VERSION "$Format:%h$"

NS_ :

BS_:

BU_: APB APP APS BCCEN BDY DAS DBG EAS EPAS EPAS2 EPAS3S EPB EPBM ESP GTW GTWU IBST IC MCU OCS PARK PARK3 RADAR RCM RT3000 SCCM SDM SEC TAS TAS2 TAS2DBG TOOL TPMS VCSEATD VCSEATP

BO_ 1486 PARK_alertLog: 8 PARK
 SG_ PARK_alertID M : 0|15@1+ (1,0) [0|0] "" GTW
 SG_ PARK_sw060_subCode m60 : 55|9@1+ (1,0) [0|0] "" GTW
 SG_ PARK_sw061_ambTemp m61 : 16|8@1+ (0.5,-40) [-40|87.5] "C" GTW
 SG_ PARK_sw061_voltage m61 : 24|8@1+ (0.1,0) [0|25.4] "V" GTW
 SG_ PARK_sw061_timeHours m61 : 32|5@1+ (1,0) [0|30] "hours" GTW
 SG_ PARK_sw061_timeMinutes m61 : 40|6@1+ (1,0) [0|60] "minutes" GTW
 SG_ PARK_sw061_timeSeconds m61 : 48|7@1+ (0.5,0) [0|60] "seconds" GTW
 SG_ PARK_sw061_subCode m61 : 55|9@1+ (1,0) [0|0] "" GTW
 SG_ PARK_sw062_ambTemp m62 : 16|8@1+ (0.5,-40) [-40|87.5] "C" GTW
 SG_ PARK_sw062_voltage m62 : 24|8@1+ (0.1,0) [0|25.4] "V" GTW
 SG_ PARK_sw062_timeHours m62 : 32|5@1+ (1,0) [0|30] "hours" GTW
 SG_ PARK_sw062_timeMinutes m62 : 40|6@1+ (1,0) [0|60] "minutes" GTW
 SG_ PARK_sw062_timeSeconds m62 : 48|7@1+ (0.5,0) [0|60] "seconds" GTW
 SG_ PARK_sw062_subCode m62 : 55|9@1+ (1,0) [0|0] "" GTW
 SG_ PARK_sw063_ambTemp m63 : 16|8@1+ (0.5,-40) [-40|87.5] "C" GTW
 SG_ PARK_sw063_voltage m63 : 24|8@1+ (0.1,0) [0|25.4] "V" GTW
 SG_ PARK_sw063_timeHours m63 : 32|5@1+ (1,0) [0|30] "hours" GTW
 SG_ PARK_sw063_timeMinutes m63 : 40|6@1+ (1,0) [0|60] "minutes" GTW
 SG_ PARK_sw063_timeSeconds m63 : 48|7@1+ (0.5,0) [0|60] "seconds" GTW
 SG_ PARK_sw063_subCode m63 : 55|9@1+ (1,0) [0|0] "" GTW
 SG_ PARK_sw064_byte2 m64 : 16|8@1+ (1,0) [0|255] "" GTW
 SG_ PARK_sw064_byte3 m64 : 24|8@1+ (1,0) [0|255] "" GTW
 SG_ PARK_sw064_byte4 m64 : 32|8@1+ (1,0) [0|255] "" GTW
 SG_ PARK_sw064_byte5 m64 : 40|8@1+ (1,0) [0|255] "" GTW
 SG_ PARK_sw064_byte6 m64 : 48|8@1+ (1,0) [0|255] "" GTW
 SG_ PARK_sw064_byte7 m64 : 56|8@1+ (1,0) [0|255] "" GTW

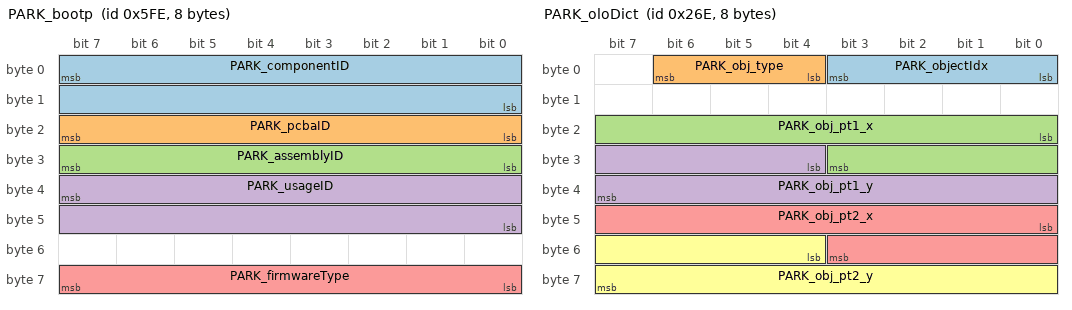
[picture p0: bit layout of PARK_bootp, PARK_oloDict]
BO_ 1534 PARK_bootp: 8 PARK
 SG_ PARK_componentID : 7|16@0+ (1,0) [0|0] "" Vector__XXX
 SG_ PARK_pcbaID : 23|8@0+ (1,0) [0|0] "" Vector__XXX
 SG_ PARK_assemblyID : 31|8@0+ (1,0) [0|0] "" Vector__XXX
 SG_ PARK_usageID : 39|16@0+ (1,0) [0|0] "" Vector__XXX
 SG_ PARK_firmwareType : 63|8@0+ (1,0) [0|0] "" Vector__XXX

BO_ 622 PARK_oloDict: 8 PARK
 SG_ PARK_objectIdx : 0|4@1+ (1,0) [0|15] "" GTW,DAS
 SG_ PARK_obj_type : 4|3@1+ (1,0) [0|7] "" GTW,DAS
 SG_ PARK_obj_pt1_x : 16|12@1+ (1,-2048) [-2048|2046] "" GTW,DAS
 SG_ PARK_obj_pt1_y : 28|12@1+ (1,-2048) [-2048|2046] "" GTW,DAS
 SG_ PARK_obj_pt2_x : 40|12@1+ (1,-2048) [-2048|2046] "" GTW,DAS
 SG_ PARK_obj_pt2_y : 52|12@1+ (1,-2048) [-2048|2046] "" GTW,DAS

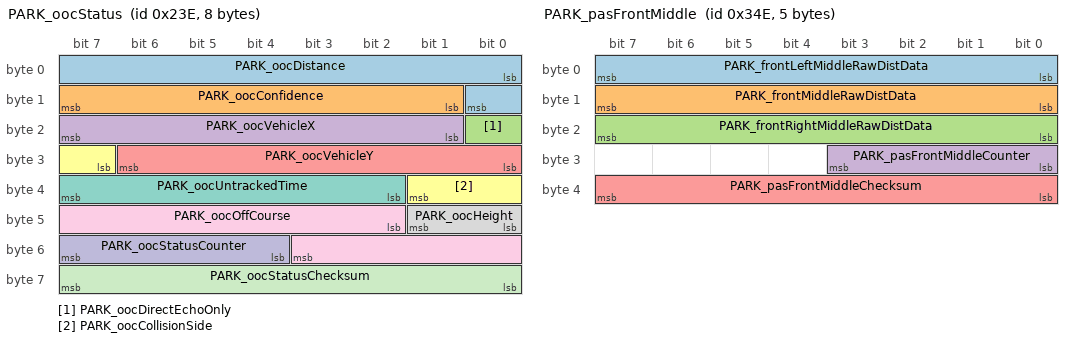
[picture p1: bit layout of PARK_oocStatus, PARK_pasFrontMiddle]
BO_ 574 PARK_oocStatus: 8 PARK
 SG_ PARK_oocDistance : 0|9@1+ (1,0) [0|512] "" EPB,EPBM,GTW,DAS
 SG_ PARK_oocConfidence : 9|7@1+ (1,0) [0|100] "" EPB,EPBM,GTW,DAS
 SG_ PARK_oocDirectEchoOnly : 16|1@1+ (1,0) [0|1] "" Vector__XXX
 SG_ PARK_oocVehicleX : 17|7@1+ (4,-114) [-114|394] "cm" Vector__XXX
 SG_ PARK_oocVehicleY : 24|7@1+ (2,-128) [-128|126] "cm" Vector__XXX
 SG_ PARK_oocCollisionSide : 31|3@1+ (1,0) [0|7] "" DAS,GTW
 SG_ PARK_oocUntrackedTime : 34|6@1+ (0.1,0) [0|6.3] "s" GTW,DAS
 SG_ PARK_oocHeight : 40|2@1+ (1,0) [0|4] "" DAS,GTW
 SG_ PARK_oocOffCourse : 42|10@1+ (1,-512) [-512|511] "" GTW,DAS
 SG_ PARK_oocStatusCounter : 52|4@1+ (1,0) [0|15] "" Vector__XXX
 SG_ PARK_oocStatusChecksum : 56|8@1+ (1,0) [0|255] "" Vector__XXX

BO_ 846 PARK_pasFrontMiddle: 5 PARK
 SG_ PARK_frontLeftMiddleRawDistData : 0|8@1+ (1,0) [0|255] "" GTW,DAS
 SG_ PARK_frontMiddleRawDistData : 8|8@1+ (1,0) [0|255] "" GTW,DAS
 SG_ PARK_frontRightMiddleRawDistData : 16|8@1+ (1,0) [0|255] "" GTW,DAS
 SG_ PARK_pasFrontMiddleCounter : 24|4@1+ (1,0) [0|0] "" GTW
 SG_ PARK_pasFrontMiddleChecksum : 32|8@1+ (1,0) [0|0] "" GTW

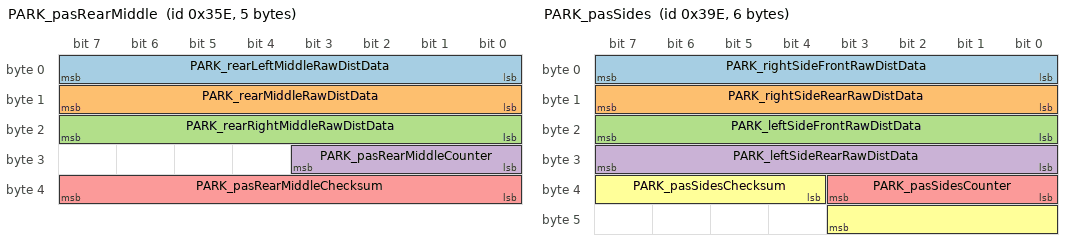
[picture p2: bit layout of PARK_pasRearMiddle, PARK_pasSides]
BO_ 862 PARK_pasRearMiddle: 5 PARK
 SG_ PARK_rearLeftMiddleRawDistData : 0|8@1+ (1,0) [0|255] "" GTW,DAS
 SG_ PARK_rearMiddleRawDistData : 8|8@1+ (1,0) [0|255] "" GTW,DAS
 SG_ PARK_rearRightMiddleRawDistData : 16|8@1+ (1,0) [0|255] "" GTW,DAS
 SG_ PARK_pasRearMiddleCounter : 24|4@1+ (1,0) [0|0] "" GTW,DAS
 SG_ PARK_pasRearMiddleChecksum : 32|8@1+ (1,0) [0|0] "" GTW

BO_ 926 PARK_pasSides: 6 PARK
 SG_ PARK_rightSideFrontRawDistData : 0|8@1+ (1,0) [0|255] "cm" GTW
 SG_ PARK_rightSideRearRawDistData : 8|8@1+ (1,0) [0|255] "cm" GTW
 SG_ PARK_leftSideFrontRawDistData : 16|8@1+ (1,0) [0|255] "cm" GTW
 SG_ PARK_leftSideRearRawDistData : 24|8@1+ (1,0) [0|255] "cm" GTW
 SG_ PARK_pasSidesCounter : 32|4@1+ (1,0) [0|0] "" GTW
 SG_ PARK_pasSidesChecksum : 36|8@1+ (1,0) [0|0] "" GTW

BO_ 606 PARK_pscEnvSlot: 8 PARK
 SG_ PARK_pscEnvSlotType M : 0|3@1+ (1,0) [0|7] "" GTW
 SG_ PARK_pscLeftParallelObj1X m0 : 3|11@1+ (2,-2048) [-2048|2046] "cm" GTW
 SG_ PARK_pscLeftParallelObj1Y m0 : 14|11@1+ (2,-2048) [-2048|2046] "cm" GTW
 SG_ PARK_pscLeftParallelObj1Alpha m0 : 25|7@1+ (2,-128) [-128|127] "deg" GTW
 SG_ PARK_pscLeftParallelObj2Y m0 : 35|11@1+ (2,-2048) [-2048|2046] "cm" GTW
 SG_ PARK_pscLeftParallelObj2X m0 : 46|11@1+ (2,-2048) [-2048|2046] "cm" GTW
 SG_ PARK_pscLeftParallelObj2Alpha m0 : 57|7@1+ (2,-128) [-128|127] "deg" GTW
 SG_ PARK_pscLeftCrossObj1X m1 : 3|11@1+ (2,-2048) [-2048|2046] "cm" GTW
 SG_ PARK_pscLeftCrossObj1Y m1 : 14|11@1+ (2,-2048) [-2048|2046] "cm" GTW
 SG_ PARK_pscLeftCrossObj1Alpha m1 : 25|7@1+ (2,-128) [-128|127] "deg" GTW
 SG_ PARK_pscLeftCrossObj2Y m1 : 35|11@1+ (2,-2048) [-2048|2046] "cm" GTW
 SG_ PARK_pscLeftCrossObj2X m1 : 46|11@1+ (2,-2048) [-2048|2046] "cm" GTW
 SG_ PARK_pscLeftCrossObj2Alpha m1 : 57|7@1+ (2,-128) [-128|127] "deg" GTW
 SG_ PARK_pscRightParallelObj1X m2 : 3|11@1+ (2,-2048) [-2048|2046] "cm" GTW
 SG_ PARK_pscRightParallelObj1Y m2 : 14|11@1+ (2,-2048) [-2048|2046] "cm" GTW
 SG_ PARK_pscRightParallelObj1Alpha m2 : 25|7@1+ (2,-128) [-128|127] "deg" GTW
 SG_ PARK_pscRightParallelObj2Y m2 : 35|11@1+ (2,-2048) [-2048|2046] "cm" GTW
 SG_ PARK_pscRightParallelObj2X m2 : 46|11@1+ (2,-2048) [-2048|2046] "cm" GTW
 SG_ PARK_pscRightParallelObj2Alpha m2 : 57|7@1+ (2,-128) [-128|127] "deg" GTW
 SG_ PARK_pscRightCrossObj1X m3 : 3|11@1+ (2,-2048) [-2048|2046] "cm" GTW
 SG_ PARK_pscRightCrossObj1Y m3 : 14|11@1+ (2,-2048) [-2048|2046] "cm" GTW
 SG_ PARK_pscRightCrossObj1Alpha m3 : 25|7@1+ (2,-128) [-128|127] "deg" GTW
 SG_ PARK_pscRightCrossObj2Y m3 : 35|11@1+ (2,-2048) [-2048|2046] "cm" GTW
 SG_ PARK_pscRightCrossObj2X m3 : 46|11@1+ (2,-2048) [-2048|2046] "cm" GTW
 SG_ PARK_pscRightCrossObj2Alpha m3 : 57|7@1+ (2,-128) [-128|127] "deg" GTW

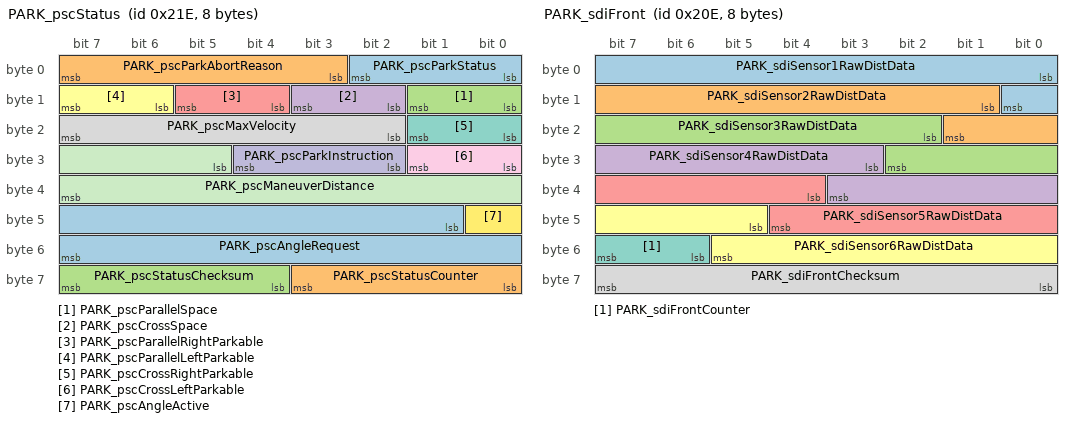
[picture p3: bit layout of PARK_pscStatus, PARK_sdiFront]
BO_ 542 PARK_pscStatus: 8 PARK
 SG_ PARK_pscParkStatus : 0|3@1+ (1,0) [0|7] "" GTW,DAS
 SG_ PARK_pscParkAbortReason : 3|5@1+ (1,0) [0|31] "" GTW,DAS
 SG_ PARK_pscParallelSpace : 8|2@1+ (1,0) [0|3] "" GTW,DAS
 SG_ PARK_pscCrossSpace : 10|2@1+ (1,0) [0|3] "" GTW,DAS
 SG_ PARK_pscParallelRightParkable : 12|2@1+ (1,0) [0|3] "" GTW,DAS
 SG_ PARK_pscParallelLeftParkable : 14|2@1+ (1,0) [0|3] "" GTW,DAS
 SG_ PARK_pscCrossRightParkable : 16|2@1+ (1,0) [0|3] "" GTW,DAS
 SG_ PARK_pscMaxVelocity : 18|6@1+ (0.1,0) [0|6.4] "kph" GTW,DAS
 SG_ PARK_pscCrossLeftParkable : 24|2@1+ (1,0) [0|3] "" GTW,DAS
 SG_ PARK_pscParkInstruction : 26|3@1+ (1,0) [0|7] "" GTW,DAS
 SG_ PARK_pscManeuverDistance : 29|11@1+ (1,0) [0|2047] "cm" GTW,DAS
 SG_ PARK_pscAngleActive : 40|1@1+ (1,0) [0|1] "" GTW,DAS
 SG_ PARK_pscAngleRequest : 41|15@1+ (0.1,-1638.4) [-1638.4|1638.4] "deg" GTW,DAS
 SG_ PARK_pscStatusCounter : 56|4@1+ (1,0) [0|15] "" GTW
 SG_ PARK_pscStatusChecksum : 60|4@1+ (1,0) [0|15] "" GTW

BO_ 590 PARK_pscVehSlot: 8 PARK
 SG_ PARK_pscVehSlotType M : 0|3@1+ (1,0) [0|7] "" GTW,DAS
 SG_ PARK_pscLeftParallelVehX m0 : 5|11@1+ (2,-2048) [-2048|2046] "cm" GTW
 SG_ PARK_pscLeftParallelVehY m0 : 16|11@1+ (2,-2048) [-2048|2046] "cm" GTW
 SG_ PARK_pscLeftParallelPsi m0 : 32|13@1+ (0.0009765625,0) [0|7.9990234375] "radians" GTW,DAS
 SG_ PARK_pscLeftParallelSizeX m0 : 48|8@1+ (4,0) [0|1020] "cm" GTW,DAS
 SG_ PARK_pscLeftParallelSizeY m0 : 56|8@1+ (4,0) [0|1020] "cm" GTW,DAS
 SG_ PARK_pscLeftCrossVehX m1 : 5|11@1+ (2,-2048) [-2048|2046] "cm" GTW
 SG_ PARK_pscLeftCrossVehY m1 : 16|11@1+ (2,-2048) [-2048|2046] "cm" GTW
 SG_ PARK_pscLeftCrossPsi m1 : 32|13@1+ (0.0009765625,0) [0|7.9990234375] "radians" GTW,DAS
 SG_ PARK_pscLeftCrossSizeX m1 : 48|8@1+ (4,0) [0|1020] "cm" GTW,DAS
 SG_ PARK_pscLeftCrossSizeY m1 : 56|8@1+ (4,0) [0|1020] "cm" GTW,DAS
 SG_ PARK_pscRightParallelVehX m2 : 5|11@1+ (2,-2048) [-2048|2046] "cm" GTW
 SG_ PARK_pscRightParallelVehY m2 : 16|11@1+ (2,-2048) [-2048|2046] "cm" GTW
 SG_ PARK_pscRightParallelPsi m2 : 32|13@1+ (0.0009765625,0) [0|7.9990234375] "radians" GTW,DAS
 SG_ PARK_pscRightParallelSizeX m2 : 48|8@1+ (4,0) [0|1020] "cm" GTW,DAS
 SG_ PARK_pscRightParallelSizeY m2 : 56|8@1+ (4,0) [0|1020] "cm" GTW,DAS
 SG_ PARK_pscRightCrossVehX m3 : 5|11@1+ (2,-2048) [-2048|2046] "cm" GTW
 SG_ PARK_pscRightCrossVehY m3 : 16|11@1+ (2,-2048) [-2048|2046] "cm" GTW
 SG_ PARK_pscRightCrossPsi m3 : 32|13@1+ (0.0009765625,0) [0|7.9990234375] "radians" GTW,DAS
 SG_ PARK_pscRightCrossSizeX m3 : 48|8@1+ (4,0) [0|1020] "cm" GTW,DAS
 SG_ PARK_pscRightCrossSizeY m3 : 56|8@1+ (4,0) [0|1020] "cm" GTW,DAS

BO_ 526 PARK_sdiFront: 8 PARK
 SG_ PARK_sdiSensor1RawDistData : 0|9@1+ (1,0) [0|511] "cm" DAS,GTW
 SG_ PARK_sdiSensor2RawDistData : 9|9@1+ (1,0) [0|511] "cm" APS,APP,GTW
 SG_ PARK_sdiSensor3RawDistData : 18|9@1+ (1,0) [0|511] "cm" DAS,APS,APP,GTW
 SG_ PARK_sdiSensor4RawDistData : 27|9@1+ (1,0) [0|511] "cm" DAS,APS,APP,GTW
 SG_ PARK_sdiSensor5RawDistData : 36|9@1+ (1,0) [0|511] "cm" APS,APP,GTW
 SG_ PARK_sdiSensor6RawDistData : 45|9@1+ (1,0) [0|511] "cm" DAS,GTW
 SG_ PARK_sdiFrontCounter : 54|2@1+ (1,0) [0|3] "" DAS,GTW
 SG_ PARK_sdiFrontChecksum : 56|8@1+ (1,0) [0|255] "" GTW

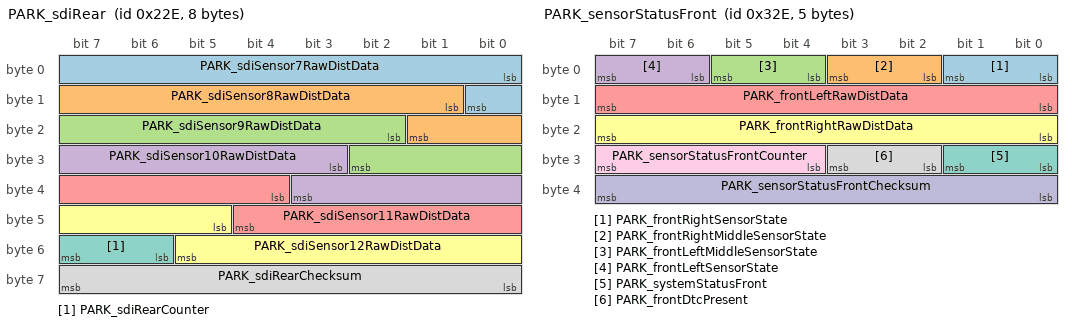
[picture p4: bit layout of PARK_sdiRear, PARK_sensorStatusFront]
BO_ 558 PARK_sdiRear: 8 PARK
 SG_ PARK_sdiSensor7RawDistData : 0|9@1+ (1,0) [0|511] "cm" DAS,GTW
 SG_ PARK_sdiSensor8RawDistData : 9|9@1+ (1,0) [0|511] "cm" DAS,GTW
 SG_ PARK_sdiSensor9RawDistData : 18|9@1+ (1,0) [0|511] "cm" DAS,GTW
 SG_ PARK_sdiSensor10RawDistData : 27|9@1+ (1,0) [0|511] "cm" DAS,GTW
 SG_ PARK_sdiSensor11RawDistData : 36|9@1+ (1,0) [0|511] "cm" DAS,GTW
 SG_ PARK_sdiSensor12RawDistData : 45|9@1+ (1,0) [0|511] "cm" DAS,GTW
 SG_ PARK_sdiRearCounter : 54|2@1+ (1,0) [0|3] "" DAS,GTW
 SG_ PARK_sdiRearChecksum : 56|8@1+ (1,0) [0|255] "" GTW

BO_ 814 PARK_sensorStatusFront: 5 PARK
 SG_ PARK_frontRightSensorState : 0|2@1+ (1,0) [0|0] "" GTW,DAS
 SG_ PARK_frontRightMiddleSensorState : 2|2@1+ (1,0) [0|0] "" GTW,DAS
 SG_ PARK_frontLeftMiddleSensorState : 4|2@1+ (1,0) [0|0] "" GTW,DAS
 SG_ PARK_frontLeftSensorState : 6|2@1+ (1,0) [0|0] "" GTW,DAS
 SG_ PARK_frontLeftRawDistData : 8|8@1+ (1,0) [0|255] "" GTW,DAS
 SG_ PARK_frontRightRawDistData : 16|8@1+ (1,0) [0|255] "" GTW,DAS
 SG_ PARK_systemStatusFront : 24|2@1+ (1,0) [0|0] "" GTW,DAS
 SG_ PARK_frontDtcPresent : 26|2@1+ (1,0) [0|0] "" GTW,DAS
 SG_ PARK_sensorStatusFrontCounter : 28|4@1+ (1,0) [0|0] "" GTW
 SG_ PARK_sensorStatusFrontChecksum : 32|8@1+ (1,0) [0|0] "" GTW

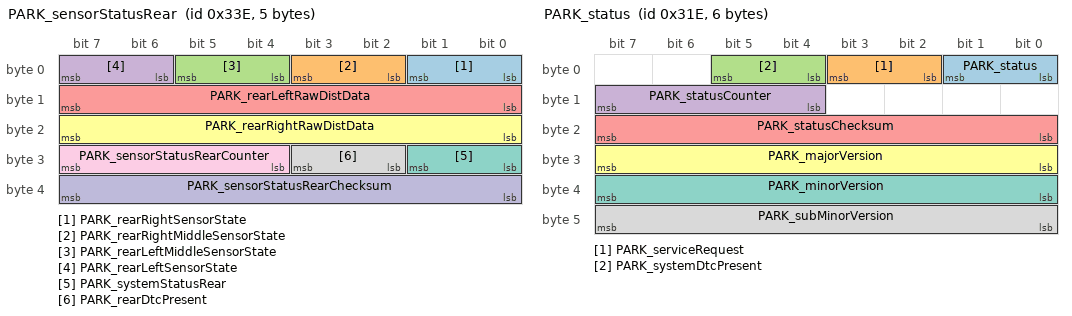
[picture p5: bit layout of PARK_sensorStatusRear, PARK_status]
BO_ 830 PARK_sensorStatusRear: 5 PARK
 SG_ PARK_rearRightSensorState : 0|2@1+ (1,0) [0|0] "" GTW,DAS
 SG_ PARK_rearRightMiddleSensorState : 2|2@1+ (1,0) [0|0] "" GTW,DAS
 SG_ PARK_rearLeftMiddleSensorState : 4|2@1+ (1,0) [0|0] "" GTW,DAS
 SG_ PARK_rearLeftSensorState : 6|2@1+ (1,0) [0|0] "" GTW,DAS
 SG_ PARK_rearLeftRawDistData : 8|8@1+ (1,0) [0|255] "" GTW,DAS
 SG_ PARK_rearRightRawDistData : 16|8@1+ (1,0) [0|255] "" GTW,DAS
 SG_ PARK_systemStatusRear : 24|2@1+ (1,0) [0|0] "" GTW,DAS
 SG_ PARK_rearDtcPresent : 26|2@1+ (1,0) [0|0] "" GTW,DAS
 SG_ PARK_sensorStatusRearCounter : 28|4@1+ (1,0) [0|0] "" GTW,DAS
 SG_ PARK_sensorStatusRearChecksum : 32|8@1+ (1,0) [0|0] "" GTW

BO_ 798 PARK_status: 6 PARK
 SG_ PARK_status : 0|2@1+ (1,0) [0|0] "" GTW,DAS
 SG_ PARK_serviceRequest : 2|2@1+ (1,0) [0|0] "" GTW,DAS
 SG_ PARK_systemDtcPresent : 4|2@1+ (1,0) [0|0] "" GTW,DAS
 SG_ PARK_statusCounter : 12|4@1+ (1,0) [0|0] "" GTW
 SG_ PARK_statusChecksum : 16|8@1+ (1,0) [0|0] "" GTW
 SG_ PARK_majorVersion : 24|8@1+ (1,0) [0|0] "" GTW,DAS
 SG_ PARK_minorVersion : 32|8@1+ (1,0) [0|0] "" GTW,DAS
 SG_ PARK_subMinorVersion : 40|8@1+ (1,0) [0|0] "" GTW,DAS

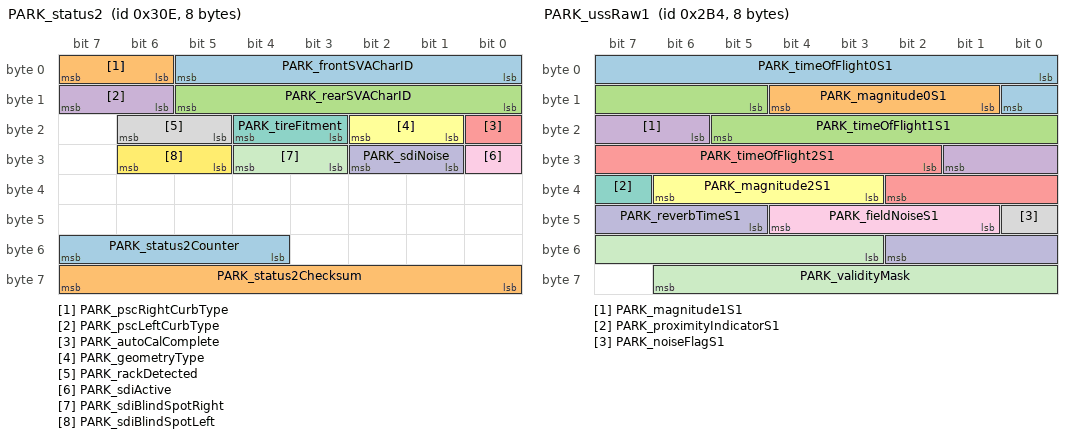
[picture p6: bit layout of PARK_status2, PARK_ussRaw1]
BO_ 782 PARK_status2: 8 PARK
 SG_ PARK_frontSVACharID : 0|6@1+ (1,0) [0|63] "" DAS,GTW
 SG_ PARK_pscRightCurbType : 6|2@1+ (1,0) [0|3] "" DAS,GTW
 SG_ PARK_rearSVACharID : 8|6@1+ (1,0) [0|63] "" DAS,GTW
 SG_ PARK_pscLeftCurbType : 14|2@1+ (1,0) [0|3] "" DAS,GTW
 SG_ PARK_autoCalComplete : 16|1@1+ (1,0) [0|1] "" DAS,GTW
 SG_ PARK_geometryType : 17|2@1+ (1,0) [0|3] "" GTW
 SG_ PARK_tireFitment : 19|2@1+ (1,0) [0|3] "" DAS,GTW
 SG_ PARK_rackDetected : 21|2@1+ (1,0) [0|3] "" DAS,GTW
 SG_ PARK_sdiActive : 24|1@1+ (1,0) [0|1] "" DAS,GTW
 SG_ PARK_sdiNoise : 25|2@1+ (1,0) [0|3] "" DAS,GTW
 SG_ PARK_sdiBlindSpotRight : 27|2@1+ (1,0) [0|3] "" DAS,GTW
 SG_ PARK_sdiBlindSpotLeft : 29|2@1+ (1,0) [0|3] "" DAS,GTW
 SG_ PARK_status2Counter : 52|4@1+ (1,0) [0|0] "" GTW,DAS
 SG_ PARK_status2Checksum : 56|8@1+ (1,0) [0|0] "" GTW

BO_ 1630 PARK_udsResponse: 8 PARK
 SG_ PARK_udsResponseData : 7|64@0+ (1,0) [0|0] "" GTW,GTWU

BO_ 692 PARK_ussRaw1: 8 PARK
 SG_ PARK_timeOfFlight0S1 : 0|9@1+ (0.0512,0) [0|26.1632] "ms" APP
 SG_ PARK_magnitude0S1 : 9|4@1+ (2,0) [0|30] "" APP
 SG_ PARK_timeOfFlight1S1 : 13|9@1+ (0.0512,0) [0|26.1632] "ms" APP
 SG_ PARK_magnitude1S1 : 22|4@1+ (2,0) [0|30] "" APP
 SG_ PARK_timeOfFlight2S1 : 26|9@1+ (0.0512,0) [0|26.1632] "ms" APP
 SG_ PARK_magnitude2S1 : 35|4@1+ (2,0) [0|30] "" APP
 SG_ PARK_proximityIndicatorS1 : 39|1@1+ (1,0) [0|0] "" APP
 SG_ PARK_noiseFlagS1 : 40|1@1+ (1,0) [0|0] "" APP
 SG_ PARK_fieldNoiseS1 : 41|4@1+ (1,0) [0|15] "" APP
 SG_ PARK_reverbTimeS1 : 45|6@1+ (0.0512,0) [0|3.2256] "ms" APP
 SG_ PARK_validityMask : 51|12@1+ (1,0) [0|0] "" APP

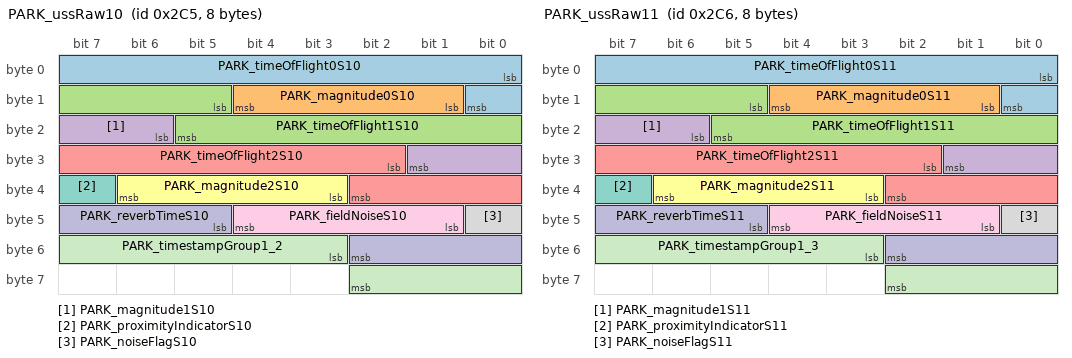
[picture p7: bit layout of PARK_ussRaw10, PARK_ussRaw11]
BO_ 709 PARK_ussRaw10: 8 PARK
 SG_ PARK_timeOfFlight0S10 : 0|9@1+ (0.0512,0) [0|26.1632] "ms" APP
 SG_ PARK_magnitude0S10 : 9|4@1+ (2,0) [0|30] "" APP
 SG_ PARK_timeOfFlight1S10 : 13|9@1+ (0.0512,0) [0|26.1632] "ms" APP
 SG_ PARK_magnitude1S10 : 22|4@1+ (2,0) [0|30] "" APP
 SG_ PARK_timeOfFlight2S10 : 26|9@1+ (0.0512,0) [0|26.1632] "ms" APP
 SG_ PARK_magnitude2S10 : 35|4@1+ (2,0) [0|30] "" APP
 SG_ PARK_proximityIndicatorS10 : 39|1@1+ (1,0) [0|0] "" APP
 SG_ PARK_noiseFlagS10 : 40|1@1+ (1,0) [0|0] "" APP
 SG_ PARK_fieldNoiseS10 : 41|4@1+ (1,0) [0|15] "" APP
 SG_ PARK_reverbTimeS10 : 45|6@1+ (0.0512,0) [0|3.2256] "ms" APP
 SG_ PARK_timestampGroup1_2 : 51|8@1+ (1,0) [0|255] "" APP

BO_ 710 PARK_ussRaw11: 8 PARK
 SG_ PARK_timeOfFlight0S11 : 0|9@1+ (0.0512,0) [0|26.1632] "ms" APP
 SG_ PARK_magnitude0S11 : 9|4@1+ (2,0) [0|30] "" APP
 SG_ PARK_timeOfFlight1S11 : 13|9@1+ (0.0512,0) [0|26.1632] "ms" APP
 SG_ PARK_magnitude1S11 : 22|4@1+ (2,0) [0|30] "" APP
 SG_ PARK_timeOfFlight2S11 : 26|9@1+ (0.0512,0) [0|26.1632] "ms" APP
 SG_ PARK_magnitude2S11 : 35|4@1+ (2,0) [0|30] "" APP
 SG_ PARK_proximityIndicatorS11 : 39|1@1+ (1,0) [0|0] "" APP
 SG_ PARK_noiseFlagS11 : 40|1@1+ (1,0) [0|0] "" APP
 SG_ PARK_fieldNoiseS11 : 41|4@1+ (1,0) [0|15] "" APP
 SG_ PARK_reverbTimeS11 : 45|6@1+ (0.0512,0) [0|3.2256] "ms" APP
 SG_ PARK_timestampGroup1_3 : 51|8@1+ (1,0) [0|255] "" APP

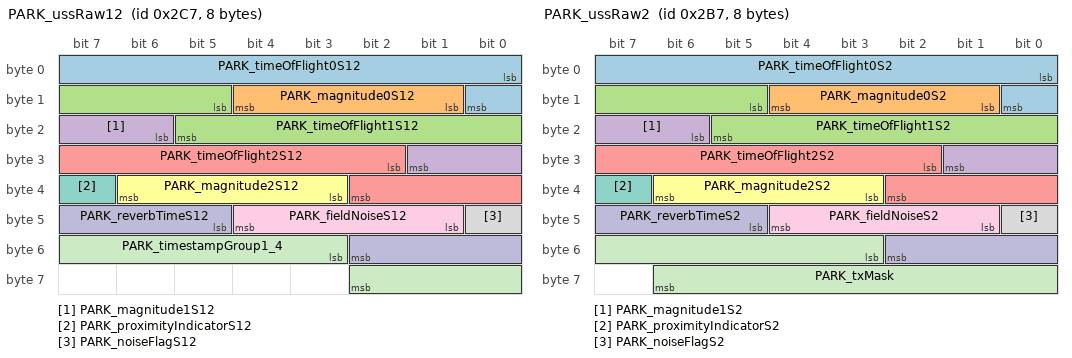
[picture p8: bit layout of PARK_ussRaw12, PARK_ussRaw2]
BO_ 711 PARK_ussRaw12: 8 PARK
 SG_ PARK_timeOfFlight0S12 : 0|9@1+ (0.0512,0) [0|26.1632] "ms" APP
 SG_ PARK_magnitude0S12 : 9|4@1+ (2,0) [0|30] "" APP
 SG_ PARK_timeOfFlight1S12 : 13|9@1+ (0.0512,0) [0|26.1632] "ms" APP
 SG_ PARK_magnitude1S12 : 22|4@1+ (2,0) [0|30] "" APP
 SG_ PARK_timeOfFlight2S12 : 26|9@1+ (0.0512,0) [0|26.1632] "ms" APP
 SG_ PARK_magnitude2S12 : 35|4@1+ (2,0) [0|30] "" APP
 SG_ PARK_proximityIndicatorS12 : 39|1@1+ (1,0) [0|0] "" APP
 SG_ PARK_noiseFlagS12 : 40|1@1+ (1,0) [0|0] "" APP
 SG_ PARK_fieldNoiseS12 : 41|4@1+ (1,0) [0|15] "" APP
 SG_ PARK_reverbTimeS12 : 45|6@1+ (0.0512,0) [0|3.2256] "ms" APP
 SG_ PARK_timestampGroup1_4 : 51|8@1+ (1,0) [0|255] "" APP

BO_ 695 PARK_ussRaw2: 8 PARK
 SG_ PARK_timeOfFlight0S2 : 0|9@1+ (0.0512,0) [0|26.1632] "ms" APP
 SG_ PARK_magnitude0S2 : 9|4@1+ (2,0) [0|30] "" APP
 SG_ PARK_timeOfFlight1S2 : 13|9@1+ (0.0512,0) [0|26.1632] "ms" APP
 SG_ PARK_magnitude1S2 : 22|4@1+ (2,0) [0|30] "" APP
 SG_ PARK_timeOfFlight2S2 : 26|9@1+ (0.0512,0) [0|26.1632] "ms" APP
 SG_ PARK_magnitude2S2 : 35|4@1+ (2,0) [0|30] "" APP
 SG_ PARK_proximityIndicatorS2 : 39|1@1+ (1,0) [0|0] "" APP
 SG_ PARK_noiseFlagS2 : 40|1@1+ (1,0) [0|0] "" APP
 SG_ PARK_fieldNoiseS2 : 41|4@1+ (1,0) [0|15] "" APP
 SG_ PARK_reverbTimeS2 : 45|6@1+ (0.0512,0) [0|3.2256] "ms" APP
 SG_ PARK_txMask : 51|12@1+ (1,0) [0|0] "" APP

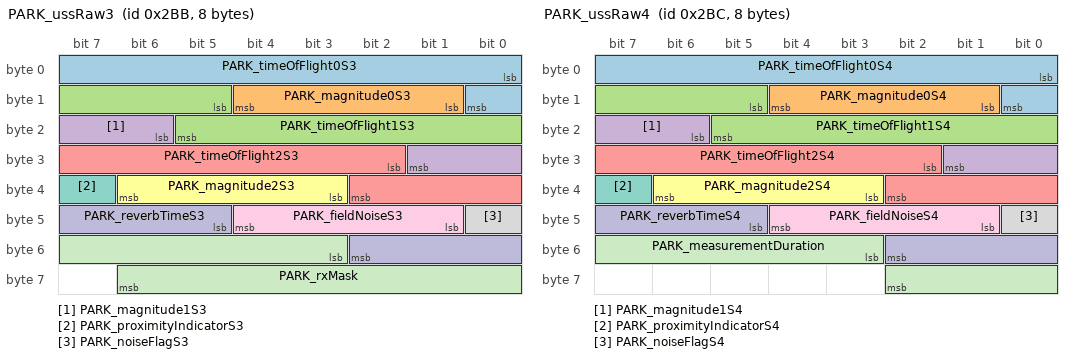
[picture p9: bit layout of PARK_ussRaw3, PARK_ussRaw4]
BO_ 699 PARK_ussRaw3: 8 PARK
 SG_ PARK_timeOfFlight0S3 : 0|9@1+ (0.0512,0) [0|26.1632] "ms" APP
 SG_ PARK_magnitude0S3 : 9|4@1+ (2,0) [0|30] "" APP
 SG_ PARK_timeOfFlight1S3 : 13|9@1+ (0.0512,0) [0|26.1632] "ms" APP
 SG_ PARK_magnitude1S3 : 22|4@1+ (2,0) [0|30] "" APP
 SG_ PARK_timeOfFlight2S3 : 26|9@1+ (0.0512,0) [0|26.1632] "ms" APP
 SG_ PARK_magnitude2S3 : 35|4@1+ (2,0) [0|30] "" APP
 SG_ PARK_proximityIndicatorS3 : 39|1@1+ (1,0) [0|0] "" APP
 SG_ PARK_noiseFlagS3 : 40|1@1+ (1,0) [0|0] "" APP
 SG_ PARK_fieldNoiseS3 : 41|4@1+ (1,0) [0|15] "" APP
 SG_ PARK_reverbTimeS3 : 45|6@1+ (0.0512,0) [0|3.2256] "ms" APP
 SG_ PARK_rxMask : 51|12@1+ (1,0) [0|0] "" APP

BO_ 700 PARK_ussRaw4: 8 PARK
 SG_ PARK_timeOfFlight0S4 : 0|9@1+ (0.0512,0) [0|26.1632] "ms" APP
 SG_ PARK_magnitude0S4 : 9|4@1+ (2,0) [0|30] "" APP
 SG_ PARK_timeOfFlight1S4 : 13|9@1+ (0.0512,0) [0|26.1632] "ms" APP
 SG_ PARK_magnitude1S4 : 22|4@1+ (2,0) [0|30] "" APP
 SG_ PARK_timeOfFlight2S4 : 26|9@1+ (0.0512,0) [0|26.1632] "ms" APP
 SG_ PARK_magnitude2S4 : 35|4@1+ (2,0) [0|30] "" APP
 SG_ PARK_proximityIndicatorS4 : 39|1@1+ (1,0) [0|0] "" APP
 SG_ PARK_noiseFlagS4 : 40|1@1+ (1,0) [0|0] "" APP
 SG_ PARK_fieldNoiseS4 : 41|4@1+ (1,0) [0|15] "" APP
 SG_ PARK_reverbTimeS4 : 45|6@1+ (0.0512,0) [0|3.2256] "ms" APP
 SG_ PARK_measurementDuration : 51|8@1+ (0.0512,0) [0|13.056] "ms" APP

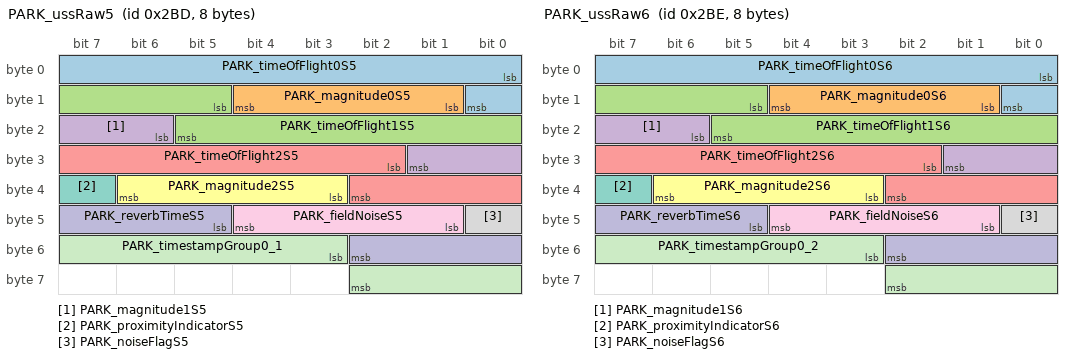
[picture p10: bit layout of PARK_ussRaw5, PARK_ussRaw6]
BO_ 701 PARK_ussRaw5: 8 PARK
 SG_ PARK_timeOfFlight0S5 : 0|9@1+ (0.0512,0) [0|26.1632] "ms" APP
 SG_ PARK_magnitude0S5 : 9|4@1+ (2,0) [0|30] "" APP
 SG_ PARK_timeOfFlight1S5 : 13|9@1+ (0.0512,0) [0|26.1632] "ms" APP
 SG_ PARK_magnitude1S5 : 22|4@1+ (2,0) [0|30] "" APP
 SG_ PARK_timeOfFlight2S5 : 26|9@1+ (0.0512,0) [0|26.1632] "ms" APP
 SG_ PARK_magnitude2S5 : 35|4@1+ (2,0) [0|30] "" APP
 SG_ PARK_proximityIndicatorS5 : 39|1@1+ (1,0) [0|0] "" APP
 SG_ PARK_noiseFlagS5 : 40|1@1+ (1,0) [0|0] "" APP
 SG_ PARK_fieldNoiseS5 : 41|4@1+ (1,0) [0|15] "" APP
 SG_ PARK_reverbTimeS5 : 45|6@1+ (0.0512,0) [0|3.2256] "ms" APP
 SG_ PARK_timestampGroup0_1 : 51|8@1+ (1,0) [0|255] "" APP

BO_ 702 PARK_ussRaw6: 8 PARK
 SG_ PARK_timeOfFlight0S6 : 0|9@1+ (0.0512,0) [0|26.1632] "ms" APP
 SG_ PARK_magnitude0S6 : 9|4@1+ (2,0) [0|30] "" APP
 SG_ PARK_timeOfFlight1S6 : 13|9@1+ (0.0512,0) [0|26.1632] "ms" APP
 SG_ PARK_magnitude1S6 : 22|4@1+ (2,0) [0|30] "" APP
 SG_ PARK_timeOfFlight2S6 : 26|9@1+ (0.0512,0) [0|26.1632] "ms" APP
 SG_ PARK_magnitude2S6 : 35|4@1+ (2,0) [0|30] "" APP
 SG_ PARK_proximityIndicatorS6 : 39|1@1+ (1,0) [0|0] "" APP
 SG_ PARK_noiseFlagS6 : 40|1@1+ (1,0) [0|0] "" APP
 SG_ PARK_fieldNoiseS6 : 41|4@1+ (1,0) [0|15] "" APP
 SG_ PARK_reverbTimeS6 : 45|6@1+ (0.0512,0) [0|3.2256] "ms" APP
 SG_ PARK_timestampGroup0_2 : 51|8@1+ (1,0) [0|255] "" APP

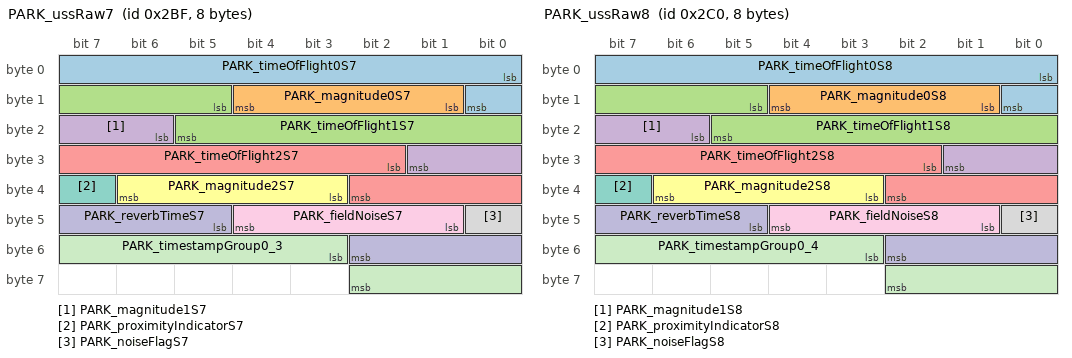
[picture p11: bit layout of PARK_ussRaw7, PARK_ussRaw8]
BO_ 703 PARK_ussRaw7: 8 PARK
 SG_ PARK_timeOfFlight0S7 : 0|9@1+ (0.0512,0) [0|26.1632] "ms" APP
 SG_ PARK_magnitude0S7 : 9|4@1+ (2,0) [0|30] "" APP
 SG_ PARK_timeOfFlight1S7 : 13|9@1+ (0.0512,0) [0|26.1632] "ms" APP
 SG_ PARK_magnitude1S7 : 22|4@1+ (2,0) [0|30] "" APP
 SG_ PARK_timeOfFlight2S7 : 26|9@1+ (0.0512,0) [0|26.1632] "ms" APP
 SG_ PARK_magnitude2S7 : 35|4@1+ (2,0) [0|30] "" APP
 SG_ PARK_proximityIndicatorS7 : 39|1@1+ (1,0) [0|0] "" APP
 SG_ PARK_noiseFlagS7 : 40|1@1+ (1,0) [0|0] "" APP
 SG_ PARK_fieldNoiseS7 : 41|4@1+ (1,0) [0|15] "" APP
 SG_ PARK_reverbTimeS7 : 45|6@1+ (0.0512,0) [0|3.2256] "ms" APP
 SG_ PARK_timestampGroup0_3 : 51|8@1+ (1,0) [0|255] "" APP

BO_ 704 PARK_ussRaw8: 8 PARK
 SG_ PARK_timeOfFlight0S8 : 0|9@1+ (0.0512,0) [0|26.1632] "ms" APP
 SG_ PARK_magnitude0S8 : 9|4@1+ (2,0) [0|30] "" APP
 SG_ PARK_timeOfFlight1S8 : 13|9@1+ (0.0512,0) [0|26.1632] "ms" APP
 SG_ PARK_magnitude1S8 : 22|4@1+ (2,0) [0|30] "" APP
 SG_ PARK_timeOfFlight2S8 : 26|9@1+ (0.0512,0) [0|26.1632] "ms" APP
 SG_ PARK_magnitude2S8 : 35|4@1+ (2,0) [0|30] "" APP
 SG_ PARK_proximityIndicatorS8 : 39|1@1+ (1,0) [0|0] "" APP
 SG_ PARK_noiseFlagS8 : 40|1@1+ (1,0) [0|0] "" APP
 SG_ PARK_fieldNoiseS8 : 41|4@1+ (1,0) [0|15] "" APP
 SG_ PARK_reverbTimeS8 : 45|6@1+ (0.0512,0) [0|3.2256] "ms" APP
 SG_ PARK_timestampGroup0_4 : 51|8@1+ (1,0) [0|255] "" APP

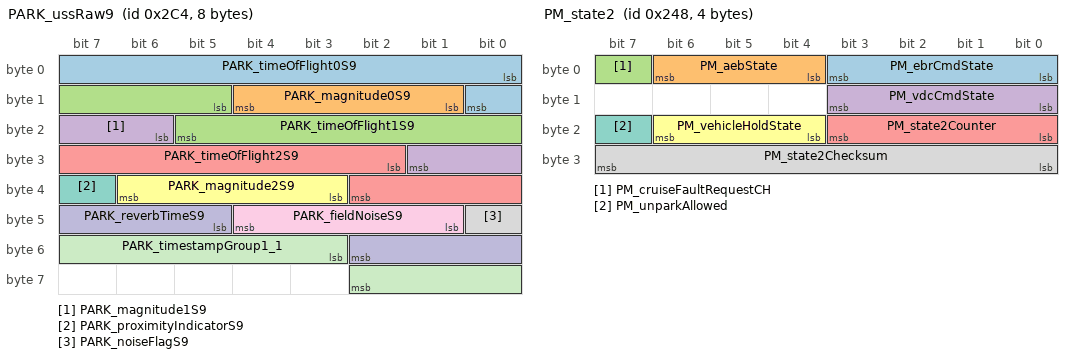
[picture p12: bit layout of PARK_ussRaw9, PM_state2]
BO_ 708 PARK_ussRaw9: 8 PARK
 SG_ PARK_timeOfFlight0S9 : 0|9@1+ (0.0512,0) [0|26.1632] "ms" APP
 SG_ PARK_magnitude0S9 : 9|4@1+ (2,0) [0|30] "" APP
 SG_ PARK_timeOfFlight1S9 : 13|9@1+ (0.0512,0) [0|26.1632] "ms" APP
 SG_ PARK_magnitude1S9 : 22|4@1+ (2,0) [0|30] "" APP
 SG_ PARK_timeOfFlight2S9 : 26|9@1+ (0.0512,0) [0|26.1632] "ms" APP
 SG_ PARK_magnitude2S9 : 35|4@1+ (2,0) [0|30] "" APP
 SG_ PARK_proximityIndicatorS9 : 39|1@1+ (1,0) [0|0] "" APP
 SG_ PARK_noiseFlagS9 : 40|1@1+ (1,0) [0|0] "" APP
 SG_ PARK_fieldNoiseS9 : 41|4@1+ (1,0) [0|15] "" APP
 SG_ PARK_reverbTimeS9 : 45|6@1+ (0.0512,0) [0|3.2256] "ms" APP
 SG_ PARK_timestampGroup1_1 : 51|8@1+ (1,0) [0|255] "" APP

BO_ 878 PARK_warningMatrix: 8 PARK
 SG_ PARK_w000_sensorDisturbance : 0|1@1+ (1,0) [0|0] "" GTW
 SG_ PARK_w001_S1_shortGround : 1|1@1+ (1,0) [0|0] "" GTW
 SG_ PARK_w002_S1_shortBattery : 2|1@1+ (1,0) [0|0] "" GTW
 SG_ PARK_w003_S1_ringTooLong : 3|1@1+ (1,0) [0|0] "" GTW
 SG_ PARK_w004_S2_shortGround : 4|1@1+ (1,0) [0|0] "" GTW
 SG_ PARK_w005_S2_shortBattery : 5|1@1+ (1,0) [0|0] "" GTW
 SG_ PARK_w006_S2_ringTooLong : 6|1@1+ (1,0) [0|0] "" GTW
 SG_ PARK_w007_S3_shortGround : 7|1@1+ (1,0) [0|0] "" GTW
 SG_ PARK_w008_S3_shortBattery : 8|1@1+ (1,0) [0|0] "" GTW
 SG_ PARK_w009_S3_ringTooLong : 9|1@1+ (1,0) [0|0] "" GTW
 SG_ PARK_w010_S4_shortGround : 10|1@1+ (1,0) [0|0] "" GTW
 SG_ PARK_w011_S4_shortBattery : 11|1@1+ (1,0) [0|0] "" GTW
 SG_ PARK_w012_S4_ringTooLong : 12|1@1+ (1,0) [0|0] "" GTW
 SG_ PARK_w013_S5_shortGround : 13|1@1+ (1,0) [0|0] "" GTW
 SG_ PARK_w014_S5_shortBattery : 14|1@1+ (1,0) [0|0] "" GTW
 SG_ PARK_w015_S5_ringTooLong : 15|1@1+ (1,0) [0|0] "" GTW
 SG_ PARK_w016_S6_shortGround : 16|1@1+ (1,0) [0|0] "" GTW
 SG_ PARK_w017_S6_shortBattery : 17|1@1+ (1,0) [0|0] "" GTW
 SG_ PARK_w018_S6_ringTooLong : 18|1@1+ (1,0) [0|0] "" GTW
 SG_ PARK_w019_S7_shortGround : 19|1@1+ (1,0) [0|0] "" GTW
 SG_ PARK_w020_S7_shortBattery : 20|1@1+ (1,0) [0|0] "" GTW
 SG_ PARK_w021_S7_ringTooLong : 21|1@1+ (1,0) [0|0] "" GTW
 SG_ PARK_w022_S8_shortGround : 22|1@1+ (1,0) [0|0] "" GTW
 SG_ PARK_w023_S8_shortBattery : 23|1@1+ (1,0) [0|0] "" GTW
 SG_ PARK_w024_S8_ringTooLong : 24|1@1+ (1,0) [0|0] "" GTW
 SG_ PARK_w025_S9_shortGround : 25|1@1+ (1,0) [0|0] "" GTW
 SG_ PARK_w026_S9_shortBattery : 26|1@1+ (1,0) [0|0] "" GTW
 SG_ PARK_w027_S9_ringTooLong : 27|1@1+ (1,0) [0|0] "" GTW
 SG_ PARK_w028_S10_shortGround : 28|1@1+ (1,0) [0|0] "" GTW
 SG_ PARK_w029_S10_shortBattery : 29|1@1+ (1,0) [0|0] "" GTW
 SG_ PARK_w030_S10_ringTooLong : 30|1@1+ (1,0) [0|0] "" GTW
 SG_ PARK_w031_S11_shortGround : 31|1@1+ (1,0) [0|0] "" GTW
 SG_ PARK_w032_S11_shortBattery : 32|1@1+ (1,0) [0|0] "" GTW
 SG_ PARK_w033_S11_ringTooLong : 33|1@1+ (1,0) [0|0] "" GTW
 SG_ PARK_w034_S12_shortGround : 34|1@1+ (1,0) [0|0] "" GTW
 SG_ PARK_w035_S12_shortBattery : 35|1@1+ (1,0) [0|0] "" GTW
 SG_ PARK_w036_S12_ringTooLong : 36|1@1+ (1,0) [0|0] "" GTW
 SG_ PARK_w037_sensorSupplyLow : 37|1@1+ (1,0) [0|0] "" GTW
 SG_ PARK_w038_sensorSupplyHigh : 38|1@1+ (1,0) [0|0] "" GTW
 SG_ PARK_w039_hardwareError : 39|1@1+ (1,0) [0|0] "" GTW
 SG_ PARK_w040_ECUSupplyLow : 40|1@1+ (1,0) [0|0] "" GTW
 SG_ PARK_w041_ECUSupplyHigh : 41|1@1+ (1,0) [0|0] "" GTW
 SG_ PARK_w042_dasMIA : 42|1@1+ (1,0) [0|0] "" GTW
 SG_ PARK_w043_epasMIA : 43|1@1+ (1,0) [0|0] "" GTW
 SG_ PARK_w044_epbMIA : 44|1@1+ (1,0) [0|0] "" GTW
 SG_ PARK_w045_espMIA : 45|1@1+ (1,0) [0|0] "" GTW
 SG_ PARK_w046_sccmMIA : 46|1@1+ (1,0) [0|0] "" GTW
 SG_ PARK_w047_dasErr : 47|1@1+ (1,0) [0|0] "" GTW
 SG_ PARK_w048_epasErr : 48|1@1+ (1,0) [0|0] "" GTW
 SG_ PARK_w049_epbErr : 49|1@1+ (1,0) [0|0] "" GTW
 SG_ PARK_w050_espErr : 50|1@1+ (1,0) [0|0] "" GTW
 SG_ PARK_w051_sccmErr : 51|1@1+ (1,0) [0|0] "" GTW
 SG_ PARK_w052_S1_sensorState : 52|1@1+ (1,0) [0|0] "" GTW
 SG_ PARK_w053_S2_sensorState : 53|1@1+ (1,0) [0|0] "" GTW
 SG_ PARK_w054_S3_sensorState : 54|1@1+ (1,0) [0|0] "" GTW
 SG_ PARK_w055_S4_sensorState : 55|1@1+ (1,0) [0|0] "" GTW
 SG_ PARK_w056_S5_sensorState : 56|1@1+ (1,0) [0|0] "" GTW
 SG_ PARK_w057_S6_sensorState : 57|1@1+ (1,0) [0|0] "" GTW
 SG_ PARK_w058_S7_sensorState : 58|1@1+ (1,0) [0|0] "" GTW
 SG_ PARK_w059_S8_sensorState : 59|1@1+ (1,0) [0|0] "" GTW
 SG_ PARK_w060_S9_sensorState : 60|1@1+ (1,0) [0|0] "" GTW
 SG_ PARK_w061_S10_sensorState : 61|1@1+ (1,0) [0|0] "" GTW
 SG_ PARK_w062_S11_sensorState : 62|1@1+ (1,0) [0|0] "" GTW
 SG_ PARK_w063_S12_sensorState : 63|1@1+ (1,0) [0|0] "" GTW

BO_ 584 PM_state2: 4 GTW
 SG_ PM_ebrCmdState : 0|4@1+ (1,0) [0|0] "" ESP
 SG_ PM_aebState : 4|3@1+ (1,0) [0|0] "" GTW
 SG_ PM_cruiseFaultRequestCH : 7|1@1+ (1,0) [0|0] "" EPB,EPBM
 SG_ PM_vdcCmdState : 8|4@1+ (1,0) [0|0] "" ESP
 SG_ PM_state2Counter : 16|4@1+ (1,0) [0|0] "" ESP
 SG_ PM_vehicleHoldState : 20|3@1+ (1,0) [0|0] "" Vector__XXX
 SG_ PM_unparkAllowed : 23|1@1+ (1,0) [0|1] "" EPB,EPBM
 SG_ PM_state2Checksum : 24|8@1+ (1,0) [0|0] "" ESP

BO_ 517 PN14_STAT: 8 GTW
 SG_ PN14_BackupBat_Flt : 2|1@1+ (1,0) [0|0] "" Vector__XXX
 SG_ PN14_RemPerm : 4|1@1+ (1,0) [0|0] "" Vector__XXX
 SG_ PN14_RevBltTns_Off_Rq : 5|1@1+ (1,0) [0|0] "" Vector__XXX
 SG_ PN14_SBC_Add_Off_Rq : 6|1@1+ (1,0) [0|0] "" Vector__XXX
 SG_ PN14_SupBat_Volt : 8|8@1+ (0.1,0) [0|25.4] "V" SCCM
 SG_ PN14_SupBatCutSw_Stat : 16|2@1+ (1,0) [0|0] "" Vector__XXX
 SG_ PN14_GM1_Actv : 18|1@1+ (1,0) [0|0] "" Vector__XXX
 SG_ PN14_GM1_Avl : 19|1@1+ (1,0) [0|0] "" Vector__XXX
 SG_ PN14_AS_Off_Rq : 24|2@1+ (1,0) [0|0] "" Vector__XXX
 SG_ SPCR_Flt_PN14 : 26|2@1+ (1,0) [0|0] "" Vector__XXX
 SG_ LHC_PosnLmp_Rq : 29|1@1+ (1,0) [0|0] "" Vector__XXX
 SG_ LHC_PkLmp_Rq : 30|1@1+ (1,0) [0|0] "" Vector__XXX
 SG_ PN14_LHC_Actv : 31|1@1+ (1,0) [0|0] "" Vector__XXX
 SG_ LHC_PTC6_Rq : 32|1@1+ (1,0) [0|0] "" Vector__XXX
 SG_ LHC_PTC5_Rq : 33|1@1+ (1,0) [0|0] "" Vector__XXX
 SG_ LHC_PTC4_Rq : 34|1@1+ (1,0) [0|0] "" Vector__XXX
 SG_ LHC_PTC3_Rq : 35|1@1+ (1,0) [0|0] "" Vector__XXX
 SG_ LHC_PTC2_Rq : 36|1@1+ (1,0) [0|0] "" Vector__XXX
 SG_ LHC_PTC1_Rq : 37|1@1+ (1,0) [0|0] "" Vector__XXX
 SG_ LHC_IntFan_R_50_Rq : 38|1@1+ (1,0) [0|0] "" Vector__XXX
 SG_ LHC_IntFan_F_50_Rq : 39|1@1+ (1,0) [0|0] "" Vector__XXX
 SG_ LHC_DSH_Stg2_Rq : 40|1@1+ (1,0) [0|0] "" Vector__XXX
 SG_ LHC_DSH_Stg1_Rq : 41|1@1+ (1,0) [0|0] "" Vector__XXX
 SG_ LHC_SeatHtStg3_Rq : 42|1@1+ (1,0) [0|0] "" Vector__XXX
 SG_ LHC_SeatHtStg2_Rq : 43|1@1+ (1,0) [0|0] "" Vector__XXX
 SG_ LHC_SeatHtStg1_Rq : 44|1@1+ (1,0) [0|0] "" Vector__XXX
 SG_ LHC_SeatVn_Rq : 45|1@1+ (1,0) [0|0] "" Vector__XXX
 SG_ LHC_Tlm_Rq : 46|1@1+ (1,0) [0|0] "" Vector__XXX
 SG_ LHC_TrlrSock_Rq : 47|1@1+ (1,0) [0|0] "" Vector__XXX
 SG_ LHC_WprPkHt_Rq : 48|1@1+ (1,0) [0|0] "" Vector__XXX
 SG_ LHC_EBL_Rq : 49|1@1+ (1,0) [0|0] "" Vector__XXX
 SG_ LHC_StW_Ht_Rq : 50|1@1+ (1,0) [0|0] "" Vector__XXX
 SG_ LHC_WShHt_Rq : 51|1@1+ (1,0) [0|0] "" Vector__XXX
 SG_ LHC_MirrHt_Rq : 52|1@1+ (1,0) [0|0] "" Vector__XXX
 SG_ LHC_CoolBox_R_Rq : 53|1@1+ (1,0) [0|0] "" Vector__XXX
 SG_ LHC_EngFan_50_Rq : 54|1@1+ (1,0) [0|0] "" Vector__XXX
 SG_ LHC_FogLmp_Ft_Rq : 55|1@1+ (1,0) [0|0] "" Vector__XXX
 SG_ LHC_TrkSock_Rq : 56|1@1+ (1,0) [0|0] "" Vector__XXX
 SG_ LHC_ComfLmp_Rq : 57|1@1+ (1,0) [0|0] "" Vector__XXX
 SG_ LHC_RHU_Rq : 58|1@1+ (1,0) [0|0] "" Vector__XXX
 SG_ LHC_ICH_Rq : 59|1@1+ (1,0) [0|0] "" Vector__XXX
 SG_ PN14_LHC_Taxi_Rq : 60|1@1+ (1,0) [0|0] "" Vector__XXX
 SG_ PN14_TransMd_Stat : 62|2@1+ (1,0) [0|0] "" Vector__XXX

BO_ 1365 RADC_alertLog: 8 DAS
 SG_ RADC_alertID M : 0|10@1+ (1,0) [0|1023] "" GTW
 SG_ RADC_a002_ecuAdcErrType m2 : 16|8@1+ (1,0) [0|255] "" GTW
 SG_ RADC_a008_interLockErrType m8 : 16|8@1+ (1,0) [0|255] "" GTW
 SG_ RADC_a011_ecuMcemErrType m11 : 16|8@1+ (1,0) [0|255] "" GTW
 SG_ RADC_a013_ecuWdgErrType m13 : 16|8@1+ (1,0) [0|255] "" GTW
 SG_ RADC_a016_adcOverVoltType m16 : 16|8@1+ (1,0) [0|255] "" GTW
 SG_ RADC_a016_adcVoltage m16 : 24|6@1+ (0.1,0) [0|5] "v" GTW
 SG_ RADC_a017_adcUnderVoltType m17 : 16|8@1+ (1,0) [0|255] "" GTW
 SG_ RADC_a017_adcVoltage m17 : 24|6@1+ (0.1,0) [0|5] "v" GTW
 SG_ RADC_a019_internalSWFaultType m19 : 16|8@1+ (1,0) [0|255] "" GTW
 SG_ RADC_a019_internalSWFaultCoreID m19 : 24|4@1+ (1,0) [0|15] "" GTW
 SG_ RADC_a020_ecuTemp m20 : 16|16@1+ (0.1,-44) [-46|122] "deg" GTW
 SG_ RADC_a023_ecuTemp m23 : 16|16@1+ (0.1,-44) [-46|122] "deg" GTW
 SG_ RADC_a025_ecuVoltage m25 : 16|8@1+ (0.1,0) [0|25.5] "v" GTW
 SG_ RADC_a026_ecuVoltage m26 : 16|8@1+ (0.1,0) [0|25.5] "v" GTW
 SG_ RADC_a027_nvmFailureType m27 : 16|8@1+ (1,0) [0|255] "" GTW
 SG_ RADC_a028_rfComRegCheckFail m28 : 16|8@1+ (1,0) [0|255] "" GTW
 SG_ RADC_a029_rhcChirpMonErrType m29 : 16|8@1+ (1,0) [0|255] "" GTW
 SG_ RADC_a029_rhcRxLongTermErrType m29 : 24|8@1+ (1,0) [0|255] "" GTW
 SG_ RADC_a029_rhcRxErrType m29 : 32|8@1+ (1,0) [0|255] "" GTW
 SG_ RADC_a029_rhcVcoPowerErrType m29 : 40|8@1+ (1,0) [0|255] "" GTW
 SG_ RADC_a029_rhcSp1ErrType m29 : 48|8@1+ (1,0) [0|255] "" GTW
 SG_ RADC_a029_rhcFdcErrType m29 : 56|8@1+ (1,0) [0|255] "" GTW
 SG_ RADC_a030_rspErrType m30 : 16|8@1+ (1,0) [0|255] "" GTW
 SG_ RADC_a031_horizMisalignAngle m31 : 16|8@1+ (0.001953125,-0.25) [-0.25|0.248046875] "rad" GTW
 SG_ RADC_a031_vertMisalignAngle m31 : 24|12@1+ (0.0001220703125,-0.25) [-0.25|0.2498779296875] "rad" GTW
 SG_ RADC_a032_blockageType m32 : 16|8@1+ (1,0) [0|255] "" GTW
 SG_ RADC_a032_block_SPMBlockageState m32 : 24|3@1+ (1,0) [0|5] "" GTW
 SG_ RADC_a032_block_SPMSelfTestState m32 : 30|2@1+ (1,0) [0|4] "" GTW
 SG_ RADC_a032_block_ucEstiRange m32 : 32|8@1+ (1,0) [0|255] "m" GTW
 SG_ RADC_a032_block_ucEstiRangeConf m32 : 40|8@1+ (1,0) [0|255] "" GTW
 SG_ RADC_a032_block_ucEstiRangeProb m32 : 48|8@1+ (1,0) [0|255] "" GTW
 SG_ RADC_a032_block_ucTimeoutBlkConf m32 : 56|8@1+ (1,0) [0|255] "" GTW
 SG_ RADC_a034_vehDynamicsErrType m34 : 16|8@1+ (1,0) [0|255] "" GTW
 SG_ RADC_a035_msgID m35 : 16|12@1+ (1,0) [0|4095] "" GTW
 SG_ RADC_a036_msgID m36 : 16|12@1+ (1,0) [0|4095] "" GTW
 SG_ RADC_a037_msgID m37 : 16|12@1+ (1,0) [0|4095] "" GTW
 SG_ RADC_a038_msgID m38 : 16|12@1+ (1,0) [0|4095] "" GTW
 SG_ RADC_a039_msgID m39 : 16|12@1+ (1,0) [0|4095] "" GTW
 SG_ RADC_a040_msgID m40 : 16|12@1+ (1,0) [0|4095] "" GTW
 SG_ RADC_a041_vinErrType m41 : 16|4@1+ (1,0) [0|15] "" GTW
 SG_ RADC_a041_vinErrExp m41 : 20|16@1+ (1,0) [0|65535] "" GTW
 SG_ RADC_a041_vinErrRx m41 : 36|16@1+ (1,0) [0|65535] "" GTW
 SG_ RADC_a041_msgID m41 : 52|12@1+ (1,0) [0|4095] "" GTW
 SG_ RADC_a042_carConfigErrType m42 : 16|4@1+ (1,0) [0|15] "" GTW
 SG_ RADC_a042_carConfigErrExp m42 : 20|16@1+ (1,0) [0|65535] "" GTW
 SG_ RADC_a042_carConfigErrRx m42 : 36|16@1+ (1,0) [0|65535] "" GTW
 SG_ RADC_a042_msgID m42 : 52|12@1+ (1,0) [0|4095] "" GTW
 SG_ RADC_a043_inertialSignalsErrType m43 : 16|4@1+ (1,0) [0|15] "" GTW
 SG_ RADC_a043_inertialSignalsErrExp m43 : 20|16@1+ (1,0) [0|65535] "" GTW
 SG_ RADC_a043_inertialSignalsErrRx m43 : 36|16@1+ (1,0) [0|65535] "" GTW
 SG_ RADC_a043_msgID m43 : 52|12@1+ (1,0) [0|4095] "" GTW
 SG_ RADC_a044_stwAngleErrType m44 : 16|4@1+ (1,0) [0|15] "" GTW
 SG_ RADC_a044_stwAngleErrExp m44 : 20|16@1+ (1,0) [0|65535] "" GTW
 SG_ RADC_a044_stwAngleErrRx m44 : 36|16@1+ (1,0) [0|65535] "" GTW
 SG_ RADC_a044_msgID m44 : 52|12@1+ (1,0) [0|4095] "" GTW
 SG_ RADC_a045_vehicleStateErrType m45 : 16|4@1+ (1,0) [0|15] "" GTW
 SG_ RADC_a045_vehicleStateErrExp m45 : 20|16@1+ (1,0) [0|65535] "" GTW
 SG_ RADC_a045_vehicleStateErrRx m45 : 36|16@1+ (1,0) [0|65535] "" GTW
 SG_ RADC_a045_msgID m45 : 52|12@1+ (1,0) [0|4095] "" GTW
 SG_ RADC_a046_wheelSpeedsErrType m46 : 16|4@1+ (1,0) [0|15] "" GTW
 SG_ RADC_a046_wheelSpeedsErrExp m46 : 20|16@1+ (1,0) [0|65535] "" GTW
 SG_ RADC_a046_wheelSpeedsErrRx m46 : 36|16@1+ (1,0) [0|65535] "" GTW
 SG_ RADC_a046_msgID m46 : 52|12@1+ (1,0) [0|4095] "" GTW
 SG_ RADC_a047_chassisTypeExp m47 : 16|8@1+ (1,0) [0|255] "" GTW
 SG_ RADC_a047_chassisTypeRx m47 : 24|8@1+ (1,0) [0|255] "" GTW
 SG_ RADC_a048_airSuspensionExp m48 : 16|8@1+ (1,0) [0|255] "" GTW
 SG_ RADC_a048_airSuspensionRx m48 : 24|8@1+ (1,0) [0|255] "" GTW
 SG_ RADC_a049_fourWheelDriveExp m49 : 16|8@1+ (1,0) [0|255] "" GTW
 SG_ RADC_a049_fourWheelDriveRx m49 : 24|8@1+ (1,0) [0|255] "" GTW
 SG_ RADC_a050_countryExp m50 : 16|16@1+ (1,0) [0|65535] "" GTW
 SG_ RADC_a050_countryRx m50 : 32|16@1+ (1,0) [0|65535] "" GTW
 SG_ RADC_a051_epasTypeExp m51 : 16|8@1+ (1,0) [0|255] "" GTW
 SG_ RADC_a051_epasTypeRx m51 : 24|8@1+ (1,0) [0|255] "" GTW
 SG_ RADC_a052_radarPositionExp m52 : 16|8@1+ (1,0) [0|255] "" GTW
 SG_ RADC_a052_radarPositionRx m52 : 24|8@1+ (1,0) [0|255] "" GTW
 SG_ RADC_a053_emError_LatYawRate m53 : 16|1@1+ (1,0) [0|1] "" GTW
 SG_ RADC_a053_emError_EGOAccelState m53 : 17|1@1+ (1,0) [0|1] "" GTW
 SG_ RADC_a053_emError_EGOMotionState m53 : 18|1@1+ (1,0) [0|1] "" GTW
 SG_ RADC_a053_emError_EGOCurveState m53 : 19|1@1+ (1,0) [0|1] "" GTW
 SG_ RADC_a053_emError_EGOSpeedState m53 : 20|1@1+ (1,0) [0|1] "" GTW
 SG_ RADC_a053_emError_EGOSpeedCorrSt m53 : 21|1@1+ (1,0) [0|1] "" GTW
 SG_ RADC_a053_emError_MountVertPos m53 : 22|1@1+ (1,0) [0|1] "" GTW
 SG_ RADC_a053_emError_MountLongPos m53 : 23|1@1+ (1,0) [0|1] "" GTW
 SG_ RADC_a053_emError_LongPosToCoG m53 : 24|1@1+ (1,0) [0|1] "" GTW
 SG_ RADC_a053_emError_WheelbaseStat m53 : 25|1@1+ (1,0) [0|1] "" GTW
 SG_ RADC_a053_emError_TrackWidthFr m53 : 26|1@1+ (1,0) [0|1] "" GTW
 SG_ RADC_a053_emError_TrackWidthRe m53 : 27|1@1+ (1,0) [0|1] "" GTW
 SG_ RADC_a053_emError_VehicleWeight m53 : 28|1@1+ (1,0) [0|1] "" GTW
 SG_ RADC_a053_emError_CentGravHeight m53 : 29|1@1+ (1,0) [0|1] "" GTW
 SG_ RADC_a053_emError_AxisLoadDistr m53 : 30|1@1+ (1,0) [0|1] "" GTW
 SG_ RADC_a053_emError_PreClusterList m53 : 31|1@1+ (1,0) [0|1] "" GTW
 SG_ RADC_a053_emError_RSPClusterList m53 : 32|1@1+ (1,0) [0|1] "" GTW
 SG_ RADC_a054_block_ucObjLossProb m54 : 16|8@1+ (1,0) [0|255] "" GTW
 SG_ RADC_a054_block_ucObjLossConf m54 : 24|8@1+ (1,0) [0|255] "" GTW
 SG_ RADC_a054_block_ucOverallProb m54 : 32|8@1+ (1,0) [0|255] "" GTW
 SG_ RADC_a054_block_ucOverallConf m54 : 40|8@1+ (1,0) [0|255] "" GTW
 SG_ RADC_a054_block_RoadbeamTimeCnt m54 : 48|16@1+ (1,0) [0|65535] "s" GTW
 SG_ RADC_a055_block_usTimeoutWayCnt m55 : 16|16@1+ (1,0) [0|65535] "m" GTW
 SG_ RADC_a055_block_ucTimeoutTimeCnt m55 : 32|8@1+ (1,0) [0|255] "s" GTW
 SG_ RADC_a055_block_ucTimeoutBlkProb m55 : 40|8@1+ (1,0) [0|255] "" GTW
 SG_ RADC_a055_block_usFullBlkTimer m55 : 48|16@1+ (1,0) [0|65535] "s" GTW

BO_ 1282 RADC_alertMatrix0: 8 DAS
 SG_ RADC_w001_can1BusOff : 1|1@1+ (1,0) [0|1] "" GTW
 SG_ RADC_w002_ecuAdcError : 2|1@1+ (1,0) [0|1] "" GTW
 SG_ RADC_w003_ecuBistDisabled : 3|1@1+ (1,0) [0|1] "" GTW
 SG_ RADC_w004_ecuCrcHwError : 4|1@1+ (1,0) [0|1] "" GTW
 SG_ RADC_w005_ecuEcuMError : 5|1@1+ (1,0) [0|1] "" GTW
 SG_ RADC_w006_ecuFimError : 6|1@1+ (1,0) [0|1] "" GTW
 SG_ RADC_w007_ecuGptCheckError : 7|1@1+ (1,0) [0|1] "" GTW
 SG_ RADC_w008_ecuHwSwInterlock : 8|1@1+ (1,0) [0|1] "" GTW
 SG_ RADC_w009_plantModeActive : 9|1@1+ (1,0) [0|1] "" GTW
 SG_ RADC_w010_ecuIoHwAbError : 10|1@1+ (1,0) [0|1] "" GTW
 SG_ RADC_w011_ecuMcemError : 11|1@1+ (1,0) [0|1] "" GTW
 SG_ RADC_w012_ecuSpiError : 12|1@1+ (1,0) [0|1] "" GTW
 SG_ RADC_w013_ecuWdgError : 13|1@1+ (1,0) [0|1] "" GTW
 SG_ RADC_w014_fctSelfTestNotDone : 14|1@1+ (1,0) [0|1] "" GTW
 SG_ RADC_w015_fctSenInterference : 15|1@1+ (1,0) [0|1] "" GTW
 SG_ RADC_w016_adcOverVolt : 16|1@1+ (1,0) [0|1] "" GTW
 SG_ RADC_w017_adcUnderVolt : 17|1@1+ (1,0) [0|1] "" GTW
 SG_ RADC_w018_internalHardwareFault : 18|1@1+ (1,0) [0|1] "" GTW
 SG_ RADC_w019_internalSoftwareFault : 19|1@1+ (1,0) [0|1] "" GTW
 SG_ RADC_w020_overTemp : 20|1@1+ (1,0) [0|1] "" GTW
 SG_ RADC_w021_overTempCrit : 21|1@1+ (1,0) [0|1] "" GTW
 SG_ RADC_w022_tempImplausible : 22|1@1+ (1,0) [0|1] "" GTW
 SG_ RADC_w023_underTemp : 23|1@1+ (1,0) [0|1] "" GTW
 SG_ RADC_w024_underTempCrit : 24|1@1+ (1,0) [0|1] "" GTW
 SG_ RADC_w025_overVoltage : 25|1@1+ (1,0) [0|1] "" GTW
 SG_ RADC_w026_underVoltage : 26|1@1+ (1,0) [0|1] "" GTW
 SG_ RADC_w027_nvmFailure : 27|1@1+ (1,0) [0|1] "" GTW
 SG_ RADC_w028_rfChipError : 28|1@1+ (1,0) [0|1] "" GTW
 SG_ RADC_w029_rhcError : 29|1@1+ (1,0) [0|1] "" GTW
 SG_ RADC_w030_rspError : 30|1@1+ (1,0) [0|1] "" GTW
 SG_ RADC_w031_sensorMisaligned : 31|1@1+ (1,0) [0|1] "" GTW
 SG_ RADC_w032_sensorBlocked : 32|1@1+ (1,0) [0|1] "" GTW
 SG_ RADC_w033_sensorNeverAligned : 33|1@1+ (1,0) [0|1] "" GTW
 SG_ RADC_w034_vehDynamicsError : 34|1@1+ (1,0) [0|1] "" GTW
 SG_ RADC_w035_vinMIA : 35|1@1+ (1,0) [0|1] "" GTW
 SG_ RADC_w036_carConfigMIA : 36|1@1+ (1,0) [0|1] "" GTW
 SG_ RADC_w037_inertialSignalsMIA : 37|1@1+ (1,0) [0|1] "" GTW
 SG_ RADC_w038_steeringWheelAngleMIA : 38|1@1+ (1,0) [0|1] "" GTW
 SG_ RADC_w039_vehicleStateMIA : 39|1@1+ (1,0) [0|1] "" GTW
 SG_ RADC_w040_wheelSpeedsMIA : 40|1@1+ (1,0) [0|1] "" GTW
 SG_ RADC_w041_vinErr : 41|1@1+ (1,0) [0|1] "" GTW
 SG_ RADC_w042_carConfigErr : 42|1@1+ (1,0) [0|1] "" GTW
 SG_ RADC_w043_inertialSignalsErr : 43|1@1+ (1,0) [0|1] "" GTW
 SG_ RADC_w044_steeringWheelAngleErr : 44|1@1+ (1,0) [0|1] "" GTW
 SG_ RADC_w045_vehicleStateErr : 45|1@1+ (1,0) [0|1] "" GTW
 SG_ RADC_w046_wheelSpeedsErr : 46|1@1+ (1,0) [0|1] "" GTW
 SG_ RADC_w047_mismatchChassisType : 47|1@1+ (1,0) [0|1] "" GTW
 SG_ RADC_w048_mismatchAirSuspension : 48|1@1+ (1,0) [0|1] "" GTW
 SG_ RADC_w049_mismatchFourWheelDrive : 49|1@1+ (1,0) [0|1] "" GTW
 SG_ RADC_w050_mismatchCountry : 50|1@1+ (1,0) [0|1] "" GTW
 SG_ RADC_w051_mismatchEPASType : 51|1@1+ (1,0) [0|1] "" GTW
 SG_ RADC_w052_mismatcRadPos : 52|1@1+ (1,0) [0|1] "" GTW
 SG_ RADC_w053_emError : 53|1@1+ (1,0) [0|1] "" GTW
 SG_ RADC_w054_blockageInfo_Frame_1 : 54|1@1+ (1,0) [0|1] "" GTW
 SG_ RADC_w055_blockageInfo_Frame_2 : 55|1@1+ (1,0) [0|1] "" GTW

BO_ 1329 RADC_info: 8 DAS
 SG_ RADC_infoIndex M : 0|8@1+ (1,0) [0|0] "" GTW,GTWU
 SG_ RADC_infoBuildType m10 : 8|8@1+ (1,0) [0|0] "" GTW
 SG_ RADC_infoBuildConfigID m10 : 16|16@1+ (1,0) [0|0] "" GTW
 SG_ RADC_infoHardwareID m10 : 32|16@1+ (1,0) [0|0] "" GTW
 SG_ RADC_infoComponentID m10 : 48|16@1+ (1,0) [0|0] "" GTW
 SG_ RADC_infoPcbaID m11 : 16|8@1+ (1,0) [0|0] "" GTW,GTWU
 SG_ RADC_infoAssemblyID m11 : 24|8@1+ (1,0) [0|255] "" GTW,GTWU
 SG_ RADC_infoUsageID m11 : 32|16@1+ (1,0) [0|65535] "" GTW,GTWU
 SG_ RADC_infoSubUsageID m11 : 48|16@1+ (1,0) [0|65535] "" GTW
 SG_ RADC_infoApplicationCRC m13 : 32|32@1+ (1,0) [0|0] "" GTW,GTWU
 SG_ RADC_infoPlatformType m19 : 8|8@1+ (1,0) [0|0] "" GTW
 SG_ RADC_infoMajorVersion m19 : 16|8@1+ (1,0) [0|0] "" GTW
 SG_ RADC_infoBranchOrigin m19 : 24|8@1+ (1,0) [0|0] "" GTW
 SG_ RADC_infoMaturity m19 : 32|8@1+ (1,0) [0|0] "" GTW
 SG_ RADC_infoHardwareRevision m19 : 40|8@1+ (1,0) [0|0] "" GTW
 SG_ RADC_infoBootUdsProtoVersion m20 : 8|8@1+ (1,0) [0|0] "" GTW,GTWU
 SG_ RADC_infoBootloaderCRC m20 : 32|32@1+ (1,0) [0|0] "" GTW

BO_ 1665 RADC_udsResponse: 8 DAS
 SG_ RADC_udsResponseData : 7|64@0+ (1,0) [0|0] "" GTW,GTWU

BO_ 1668 RADFL_udsResponse: 8 DAS
 SG_ RADFL_udsResponseData : 7|64@0+ (1,0) [0|0] "" GTW,GTWU

BO_ 1669 RADFR_udsResponse: 8 DAS
 SG_ RADFR_udsResponseData : 7|64@0+ (1,0) [0|0] "" GTW,GTWU

BO_ 1666 RADRL_udsResponse: 8 DAS
 SG_ RADRL_udsResponseData : 7|64@0+ (1,0) [0|0] "" GTW,GTWU

BO_ 1667 RADRR_udsResponse: 8 DAS
 SG_ RADRR_udsResponseData : 7|64@0+ (1,0) [0|0] "" GTW,GTWU

CM_ BO_ 574 "OOC is Object on Course and refers to a collision object detected on the current travel path.";
CM_ BO_ 590 "Message to indicate the real time location of all possible parking slots with respect to the vehicle's frame of refence.";
CM_ BO_ 526 "Direct echo data from sensors in firing group 1, and some system wide status information. The sensors are numbered 1-12, starting the front left corner of the vehicle and going around clockwise.";
CM_ BO_ 558 "Direct echo data from sensors in firing group 2, and some system wide status information.";
CM_ SG_ 574 PARK_oocDistance "The distance the vehicle would travel along its current trajectory until the detected object would collide with the vehicle. Units are in cm";
CM_ SG_ 574 PARK_oocConfidence "0-100% Confidence that the detected object is real and on the current path. Units are in percent";
CM_ SG_ 574 PARK_oocDirectEchoOnly "False = No object is detected or the object is direct echoes and cross echoes; True = The object detected is being detected from direct echoes only.";
CM_ SG_ 574 PARK_oocVehicleX "X axis coordinate on the surface of the ego vehicle of the most imminent collision based on the current path of travel. (x-axis is parallel to vehicle path)";
CM_ SG_ 574 PARK_oocVehicleY "Y axis coordinate on the surface of the ego vehicle of the most imminent collision based on the current path of travel. (Y-axis is defined as perpendicular to the vehicle path)";
CM_ SG_ 574 PARK_oocCollisionSide "The side of the car that the collision is expected to occur on (or no collision).";
CM_ SG_ 574 PARK_oocUntrackedTime "Time since the last echo measurement on the detected object.";
CM_ SG_ 574 PARK_oocHeight "The detected object is a high object or not a high object. The high object is when the system detects two objects very close together.";
CM_ SG_ 574 PARK_oocOffCourse "Distance nearest object is off from the edge of the tube of travel of the vehicle, eg 0 = side of car, and 100 is centerlines. Units are in cm";
CM_ SG_ 574 PARK_oocStatusCounter "Stale data counter. Since this message will not be gatewayed, it does not need a checksum.";
CM_ SG_ 846 PARK_frontLeftMiddleRawDistData "Zone defined as -38 degrees -> +12 degrees, distance to object in units of centimeters.";
CM_ SG_ 846 PARK_frontMiddleRawDistData "Zone defined as -12 degrees to +12 degrees, distance to object in units of centimeters.";
CM_ SG_ 846 PARK_frontRightMiddleRawDistData "Zone defined +12 degrees to +38 degreees, distance to object in units of centimeters.";
CM_ SG_ 846 PARK_pasFrontMiddleChecksum "Message checksum for PARK_sensorStatusFrontChecksum: sum of all bytes in message + originating CAN ID (0x3 + 0x4E = 0x51)";
CM_ SG_ 862 PARK_rearLeftMiddleRawDistData "Zone defined as -124 degrees to -166 degrees, distance to object in units of centimeters.";
CM_ SG_ 862 PARK_rearMiddleRawDistData "Zone defined as -166 degrees to +166 degrees, distance to object in units of centimeters.";
CM_ SG_ 862 PARK_rearRightMiddleRawDistData "Zone defined as +166 degrees to +124 degrees, distance to object in units of centimeters.";
CM_ SG_ 862 PARK_pasRearMiddleChecksum "Message checksum for PARK_sensorStatusRearChecksum: sum of all bytes in message + originating CAN ID (0x3 + 0x5E = 0x61)";
CM_ SG_ 926 PARK_rightSideFrontRawDistData "Right side (from inside the car) towards the front of the car (split evenly between axles).";
CM_ SG_ 926 PARK_rightSideRearRawDistData "Right side (from inside the car) towards the rear of the car (split evenly between axles).";
CM_ SG_ 926 PARK_leftSideFrontRawDistData "Left side (from inside the car) towards the front of the car (split evenly between axles).";
CM_ SG_ 926 PARK_leftSideRearRawDistData "Left side (from inside the car) towards the rear of the car (split evenly between axles).";
CM_ SG_ 606 PARK_pscLeftCrossObj1X "The x coordinate of the forward left corner of the parking slot based on border as defined by lead object";
CM_ SG_ 606 PARK_pscLeftCrossObj1Y "The y coordinate of the forward left corner of the parking slot based on border as defined by lead object";
CM_ SG_ 606 PARK_pscLeftCrossObj1Alpha "The angle of the lead object, always zeor for parallel clockwise negative for perpendicular.";
CM_ SG_ 606 PARK_pscLeftCrossObj2Y "The y coordinate of the forward left corner of the parking slot based on border as defined by following object";
CM_ SG_ 606 PARK_pscLeftCrossObj2X "The x coordinate of the forward left corner of the parking slot based on border as defined by following object";
CM_ SG_ 606 PARK_pscLeftCrossObj2Alpha "The angle of the following object, always zero for parallel clockwise negative for perpendicular.";
CM_ SG_ 542 PARK_pscMaxVelocity "The maximum velocity allowed during each manuever. Updated during each manuever.";
CM_ SG_ 542 PARK_pscManeuverDistance "Real time updated path length from center of vehicle reference frame to desired center of vehicle at end of current parking manuever.";
CM_ SG_ 542 PARK_pscStatusChecksum "Four bit checksum, calculated as the sum of the data bytes of the message + the originating message ID (0x4 + 0x48 = 0x4C)";
CM_ SG_ 590 PARK_pscLeftCrossVehX "The x component of the vector from the center of the vehicle's rear axle to the rear street side corner of the lead vehicle forming the parking slot. Set to NO_SPACE until status = pre-guidance.";
CM_ SG_ 590 PARK_pscLeftCrossVehY "The y component of the vector from the center of the vehicle's rear axle to the rear street side corner of the lead vehicle forming the parking slot. Set to NO_SPACE until status = pre-guidance.";
CM_ SG_ 590 PARK_pscLeftCrossPsi "Angle of car with respect to the front target vehicle. Set to NO_SPACE until status = pre-guidance.";
CM_ SG_ 590 PARK_pscLeftCrossSizeX "The x axis dimension of the pependicular space on the left side of the road. (x axis is along the length of the vehicle)";
CM_ SG_ 590 PARK_pscLeftCrossSizeY "The y-axis dimension of the pependicular space on the left side of the road. (y axis is along the width of the vehicle)";
CM_ SG_ 526 PARK_sdiFrontChecksum "Checksum should be calculated as sum of all non-checksum bytes + originating message ID (0x2 + 0x0E) = 0x10.";
CM_ SG_ 558 PARK_sdiRearChecksum "Checksum should be calculated as sum of all non checksum bytes + originating message ID (0x2 + 0x2E) = (0x30).";
CM_ SG_ 814 PARK_frontLeftRawDistData "Zone defined as -90 degrees -> -38 degrees, distance to object in units of centimeters.";
CM_ SG_ 814 PARK_frontRightRawDistData "Zone defined as +38 degrees -> +90 degrees, distance to object in units of centimeters.";
CM_ SG_ 814 PARK_sensorStatusFrontChecksum "Message checksum for PARK_sensorStatusFrontChecksum: sum of all bytes in message + originating CAN ID (0x3 + 0x2E = 0x31)";
CM_ SG_ 830 PARK_rearLeftRawDistData "Zone defined as -90 degrees to -125 degrees, distance to object in units of centimeters.";
CM_ SG_ 830 PARK_rearRightRawDistData "Zone defined as +125 degrees to +90 degrees, distance to object in units of centimeters.";
CM_ SG_ 830 PARK_sensorStatusRearChecksum "Message checksum for PARK_sensorStatusRearChecksum: sum of all bytes in message + originating CAN ID (0x3 + 0x3E = 0x41)";
CM_ SG_ 798 PARK_statusChecksum "Message checksum for PARK_statusChecksum: sum of all bytes in message + originating CAN ID (0x3 + 0x1E = 0x21)";
CM_ SG_ 584 PM_ebrCmdState "Safety ECU signal to disable external brake request.";
CM_ SG_ 584 PM_aebState "State of AEB state machine in safety ECU";
CM_ SG_ 584 PM_vdcCmdState "Safety ECU signal to disable vdc brake request.";
CM_ SG_ 584 PM_state2Counter "Message counter for PM_state2 message: increments in each message.";
CM_ SG_ 584 PM_state2Checksum "Message checksum for PM_state2 message: sum of all bytes in message + originating CAN ID (0x2 + 0x04 = 0x06).";
CM_ SG_ 517 PN14_BackupBat_Flt "Backup battery fault";
CM_ SG_ 517 PN14_RemPerm "Remote functions permission";
CM_ SG_ 517 PN14_RevBltTns_Off_Rq "Reversible belt tensioner off request";
CM_ SG_ 517 PN14_SBC_Add_Off_Rq "SBC additional value off request";
CM_ SG_ 517 PN14_SupBat_Volt "Supply battery voltage";
CM_ SG_ 517 PN14_SupBatCutSw_Stat "Supply battery cutoff switch state";
CM_ SG_ 517 PN14_GM1_Actv "Generator management activated";
CM_ SG_ 517 PN14_GM1_Avl "Generator management available, ready for activation";
CM_ SG_ 517 PN14_AS_Off_Rq "Assistance system off request";
CM_ SG_ 517 SPCR_Flt_PN14 "Stop coordinator fault detected by PN14";
CM_ SG_ 517 LHC_PosnLmp_Rq "Limp-home cutoff position lamps request";
CM_ SG_ 517 LHC_PkLmp_Rq "Limp-home cutoff parking lamps request";
CM_ SG_ 517 PN14_LHC_Actv "14 V powernet limp-home cutoff active";
CM_ SG_ 517 LHC_PTC6_Rq "Limp-home cutoff PTC 6th branch request";
CM_ SG_ 517 LHC_PTC5_Rq "Limp-home cutoff PTC 5th branch request";
CM_ SG_ 517 LHC_PTC4_Rq "Limp-home cutoff PTC 4th branch request";
CM_ SG_ 517 LHC_PTC3_Rq "Limp-home cutoff PTC 3rd branch request";
CM_ SG_ 517 LHC_PTC2_Rq "Limp-home cutoff PTC 2nd branch request";
CM_ SG_ 517 LHC_PTC1_Rq "Limp-home cutoff PTC 1st branch request";
CM_ SG_ 517 LHC_IntFan_R_50_Rq "Limp-home cutoff rear interior fan to 50 % request";
CM_ SG_ 517 LHC_IntFan_F_50_Rq "Limp-home cutoff front interior fan to 50 % request";
CM_ SG_ 517 LHC_DSH_Stg2_Rq "Limp-home cutoff door surface heating stage 2 request";
CM_ SG_ 517 LHC_DSH_Stg1_Rq "Limp-home cutoff door surface heating stage 1 request";
CM_ SG_ 517 LHC_SeatHtStg3_Rq "Limp-home cutoff seat heating stage 3 request";
CM_ SG_ 517 LHC_SeatHtStg2_Rq "Limp-home cutoff seat heating stage 2 request";
CM_ SG_ 517 LHC_SeatHtStg1_Rq "Limp-home cutoff seat heating stage 1 request";
CM_ SG_ 517 LHC_SeatVn_Rq "Limp-home cutoff seat ventilation request";
CM_ SG_ 517 LHC_Tlm_Rq "Limp-home cutoff Telematics/Audio/Phone/GPS request";
CM_ SG_ 517 LHC_TrlrSock_Rq "Limp-home cutoff trailer socket request";
CM_ SG_ 517 LHC_WprPkHt_Rq "Limp-home cutoff wiper park position heater  request";
CM_ SG_ 517 LHC_EBL_Rq "Limp-home cutoff electric backlite heater request";
CM_ SG_ 517 LHC_StW_Ht_Rq "Limp-home cutoff steering wheel heater  request";
CM_ SG_ 517 LHC_WShHt_Rq "Limp-home cutoff windshield heater request";
CM_ SG_ 517 LHC_MirrHt_Rq "Limp-home cutoff mirror heater Request";
CM_ SG_ 517 LHC_CoolBox_R_Rq "Limp-home cutoff rear cooler box request";
CM_ SG_ 517 LHC_EngFan_50_Rq "Limp-home cutoff engine fan to 50 % request";
CM_ SG_ 517 LHC_FogLmp_Ft_Rq "Limp-home cutoff fog lamps front request";
CM_ SG_ 517 LHC_TrkSock_Rq "Limp-home cutoff trunk socket/cigarette lighter request";
CM_ SG_ 517 LHC_ComfLmp_Rq "Limp-home cutoff comfort lamps request";
CM_ SG_ 517 LHC_RHU_Rq "Limp-home cutoff residual heat utilization request";
CM_ SG_ 517 LHC_ICH_Rq "Limp-home cutoff independant car heater request";
CM_ SG_ 517 PN14_LHC_Taxi_Rq "Limp-home cutoff taxi roofsign/printer request";
CM_ SG_ 517 PN14_TransMd_Stat "Powernet transport mode status";
BA_DEF_ BO_ "AlertLogSubSystemId" INT 0 0;
BA_DEF_ BO_ "AlertType" INT 0 4;
BA_DEF_ BO_ "AppBotschaft" ENUM "nein","ja";
BA_DEF_ BO_ "DiagRequest" ENUM "No","Yes";
BA_DEF_ BO_ "DiagResponse" ENUM "No","Yes";
BA_DEF_ BO_ "ETHGatewayMessageSendType" ENUM "UseGenMsgSendType","onWrite","noAutoCode";
BA_DEF_ BO_ "ETHId" STRING ;
BA_DEF_ BO_ "GatewayHandlerEnum" ENUM "noHandler","uds","alertLog","messageLogOnReception","udsClient";
BA_DEF_ BO_ "GatewayMessageAtomic" ENUM "No","Yes";
BA_DEF_ BO_ "GatewayMessageSendType" ENUM "UseGenMsgSendType","onWrite","noAutoCode";
BA_DEF_ BO_ "GenMsgCycleTime" INT 0 0;
BA_DEF_ BO_ "GenMsgCycleTimeFast" INT 0 0;
BA_DEF_ BO_ "GenMsgDelayTime" INT 0 0;
BA_DEF_ BO_ "GenMsgForceMiaCheck" ENUM "No","Yes";
BA_DEF_ BO_ "GenMsgGatewayNotification" STRING ;
BA_DEF_ BO_ "GenMsgILSupport" ENUM "No","Yes";
BA_DEF_ BO_ "GenMsgSaltingFunction" ENUM "No","Yes";
BA_DEF_ BO_ "GenMsgSendType" ENUM "Cyclic","NotUsed","NotUsed","NotUsed","NotUsed","NotUsed","NotUsed","IfActive","NoMsgSendType","Sporadic";
BA_DEF_ BO_ "GenMsgStartValue" STRING ;
BA_DEF_ BO_ "GenMsgTimeOut" INT 0 0;
BA_DEF_ BO_ "MessageIdType" ENUM "normal","udsRequest","udsResponse","udsReserved","udsFunctionalRequest","networkManagement","bootloader","xcp","dtc","diagnostic","vendorExempt";
BA_DEF_ BO_ "NWMBotschaft" ENUM "nein","ja";
BA_DEF_ BO_ "NmMessage" ENUM "No","Yes";
BA_DEF_ BO_ "SubSystemId" INT 0 256;
BA_DEF_ BO_ "UsesChecksum" ENUM "No","Yes";
BA_DEF_ SG_ "FieldType" STRING ;
BA_DEF_ SG_ "FlexKomComment" STRING ;
BA_DEF_ SG_ "FlexKomIsMotorola" ENUM "nein","ja";
BA_DEF_ SG_ "FlexKomSID" INT 0 2147483647;
BA_DEF_ SG_ "FlexKomSigLaenge" INT 0 64;
BA_DEF_ SG_ "FlexKomSigName" STRING ;
BA_DEF_ SG_ "FlexKomSigStartPos" INT 0 63;
BA_DEF_ SG_ "FlexKomSigStartValue" STRING ;
BA_DEF_ SG_ "Gatewaysignal" INT 0 1;
BA_DEF_ SG_ "GenSigCycleTime" INT 0 0;
BA_DEF_ SG_ "GenSigCycleTimeActive" INT 0 0;
BA_DEF_ SG_ "GenSigPersistent" ENUM "No","Yes";
BA_DEF_ SG_ "GenSigSNA" STRING ;
BA_DEF_ SG_ "GenSigSendType" ENUM "Cyclic","OnWrite","OnWriteWithRepetition","OnChange","OnChangeWithRepetition","IfActive","IfActiveWithRepetition","NoSigSendType","NotUsed","NotUsed","NotUsed","NotUsed","NotUsed";
BA_DEF_ SG_ "GenSigStartValue" INT 0 0;
BA_DEF_ SG_ "GenSigTimeout_CGW" INT 0 65535;
BA_DEF_ SG_ "GenSigTimeout_DRVU" INT 0 65535;
BA_DEF_ SG_ "GenSigTimeout_ECM" INT 0 65535;
BA_DEF_ SG_ "GenSigTimeout_EIS" INT 0 65535;
BA_DEF_ SG_ "GenSigTimeout_EPS" INT 0 65535;
BA_DEF_ SG_ "GenSigTimeout_ESP_ABR" INT 0 65535;
BA_DEF_ SG_ "GenSigTimeout_IC" INT 0 65535;
BA_DEF_ SG_ "GenSigTimeout_MPC" INT 0 65535;
BA_DEF_ SG_ "GenSigTimeout_NV" INT 0 65535;
BA_DEF_ SG_ "GenSigTimeout_ORC" INT 0 65535;
BA_DEF_ SG_ "GenSigTimeout_PTS" INT 0 65535;
BA_DEF_ SG_ "GenSigTimeout_RBTM_FL" INT 0 65535;
BA_DEF_ SG_ "GenSigTimeout_RBTM_FR" INT 0 65535;
BA_DEF_ SG_ "GenSigTimeout_RDU" INT 0 65535;
BA_DEF_ SG_ "GenSigTimeout_SCCM" INT 0 65535;
BA_DEF_ SG_ "GenSigTimeout_SPC" INT 0 65535;
BA_DEF_ SG_ "GenSigTimeout_TPM" INT 0 65535;
BA_DEF_ SG_ "LogSignal" STRING ;
BA_DEF_ SG_ "PektronUpdateBitType" ENUM "Not used","Has update bit","Is update bit";
BA_DEF_REL_ BU_SG_REL_ "GenSigTimeoutTime" INT 0 0;

BA_DEF_DEF_ "AlertLogSubSystemId" 0;
BA_DEF_DEF_ "AlertType" 4;
BA_DEF_DEF_ "AppBotschaft" "nein";
BA_DEF_DEF_ "DiagRequest" "No";
BA_DEF_DEF_ "DiagResponse" "No";
BA_DEF_DEF_ "ETHGatewayMessageSendType" "UseGenMsgSendType";
BA_DEF_DEF_ "ETHId" "";
BA_DEF_DEF_ "FieldType" "";
BA_DEF_DEF_ "FlexKomComment" "";
BA_DEF_DEF_ "FlexKomIsMotorola" "";
BA_DEF_DEF_ "FlexKomSID" 0;
BA_DEF_DEF_ "FlexKomSigLaenge" 0;
BA_DEF_DEF_ "FlexKomSigName" "";
BA_DEF_DEF_ "FlexKomSigStartPos" 0;
BA_DEF_DEF_ "FlexKomSigStartValue" "";
BA_DEF_DEF_ "GatewayHandlerEnum" "noHandler";
BA_DEF_DEF_ "GatewayMessageAtomic" "No";
BA_DEF_DEF_ "GatewayMessageSendType" "UseGenMsgSendType";
BA_DEF_DEF_ "Gatewaysignal" 0;
BA_DEF_DEF_ "GenMsgCycleTime" 0;
BA_DEF_DEF_ "GenMsgCycleTimeFast" 0;
BA_DEF_DEF_ "GenMsgDelayTime" 0;
BA_DEF_DEF_ "GenMsgForceMiaCheck" "No";
BA_DEF_DEF_ "GenMsgGatewayNotification" "";
BA_DEF_DEF_ "GenMsgILSupport" "Yes";
BA_DEF_DEF_ "GenMsgSaltingFunction" "No";
BA_DEF_DEF_ "GenMsgSendType" "Cyclic";
BA_DEF_DEF_ "GenMsgStartValue" "";
BA_DEF_DEF_ "GenMsgTimeOut" 0;
BA_DEF_DEF_ "GenSigCycleTime" 0;
BA_DEF_DEF_ "GenSigCycleTimeActive" 0;
BA_DEF_DEF_ "GenSigPersistent" "No";
BA_DEF_DEF_ "GenSigSNA" "";
BA_DEF_DEF_ "GenSigSendType" "Cyclic";
BA_DEF_DEF_ "GenSigStartValue" 0;
BA_DEF_DEF_ "GenSigTimeout_CGW" 0;
BA_DEF_DEF_ "GenSigTimeout_DRVU" 0;
BA_DEF_DEF_ "GenSigTimeout_ECM" 0;
BA_DEF_DEF_ "GenSigTimeout_EIS" 0;
BA_DEF_DEF_ "GenSigTimeout_EPS" 0;
BA_DEF_DEF_ "GenSigTimeout_ESP_ABR" 0;
BA_DEF_DEF_ "GenSigTimeout_IC" 0;
BA_DEF_DEF_ "GenSigTimeout_MPC" 0;
BA_DEF_DEF_ "GenSigTimeout_NV" 0;
BA_DEF_DEF_ "GenSigTimeout_ORC" 0;
BA_DEF_DEF_ "GenSigTimeout_PTS" 0;
BA_DEF_DEF_ "GenSigTimeout_RBTM_FL" 0;
BA_DEF_DEF_ "GenSigTimeout_RBTM_FR" 0;
BA_DEF_DEF_ "GenSigTimeout_RDU" 0;
BA_DEF_DEF_ "GenSigTimeout_SCCM" 0;
BA_DEF_DEF_ "GenSigTimeout_SPC" 0;
BA_DEF_DEF_ "GenSigTimeout_TPM" 0;
BA_DEF_DEF_ "LogSignal" "";
BA_DEF_DEF_ "MessageIdType" "normal";
BA_DEF_DEF_ "NWMBotschaft" "nein";
BA_DEF_DEF_ "NmMessage" "No";
BA_DEF_DEF_ "PektronUpdateBitType" "Not used";
BA_DEF_DEF_ "SubSystemId" 0;
BA_DEF_DEF_ "UsesChecksum" "No";
BA_DEF_DEF_REL_ "GenSigTimeoutTime" 0;
BA_ "GenMsgSendType" BO_ 1534 8;
BA_ "GenMsgCycleTime" BO_ 622 20;
BA_ "GenMsgCycleTime" BO_ 574 40;
BA_ "GenMsgCycleTime" BO_ 846 100;
BA_ "GenMsgCycleTime" BO_ 862 100;
BA_ "GenMsgCycleTime" BO_ 926 100;
BA_ "GenMsgCycleTime" BO_ 606 100;
BA_ "GenMsgCycleTime" BO_ 542 40;
BA_ "GenMsgCycleTime" BO_ 590 100;
BA_ "GenMsgCycleTime" BO_ 526 40;
BA_ "GenMsgCycleTime" BO_ 558 40;
BA_ "GenMsgCycleTime" BO_ 814 100;
BA_ "GenMsgCycleTime" BO_ 830 100;
BA_ "GenMsgCycleTime" BO_ 798 500;
BA_ "GenMsgCycleTime" BO_ 782 250;
BA_ "DiagResponse" BO_ 1630 1;
BA_ "GatewayHandlerEnum" BO_ 1630 4;
BA_ "GenMsgSendType" BO_ 1630 8;
BA_ "MessageIdType" BO_ 1630 2;
BA_ "GenMsgSendType" BO_ 692 9;
BA_ "GenMsgSendType" BO_ 709 9;
BA_ "GenMsgSendType" BO_ 710 9;
BA_ "GenMsgSendType" BO_ 711 9;
BA_ "GenMsgSendType" BO_ 695 9;
BA_ "GenMsgSendType" BO_ 699 9;
BA_ "GenMsgSendType" BO_ 700 9;
BA_ "GenMsgSendType" BO_ 701 9;
BA_ "GenMsgSendType" BO_ 702 9;
BA_ "GenMsgSendType" BO_ 703 9;
BA_ "GenMsgSendType" BO_ 704 9;
BA_ "GenMsgSendType" BO_ 708 9;
BA_ "GenMsgCycleTime" BO_ 878 1000;
BA_ "GatewayMessageSendType" BO_ 584 2;
BA_ "GenMsgCycleTime" BO_ 584 50;
BA_ "GenMsgSendType" BO_ 517 8;
BA_ "GenMsgStartValue" BO_ 517 "02FF000F000000C0h";
BA_ "MessageIdType" BO_ 517 10;
BA_ "AlertLogSubSystemId" BO_ 1365 264;
BA_ "GatewayHandlerEnum" BO_ 1365 2;
BA_ "GenMsgSendType" BO_ 1365 8;
BA_ "GenMsgCycleTime" BO_ 1282 1000;
BA_ "GenMsgCycleTime" BO_ 1329 2000;
BA_ "DiagResponse" BO_ 1665 1;
BA_ "GatewayHandlerEnum" BO_ 1665 4;
BA_ "GenMsgSendType" BO_ 1665 8;
BA_ "MessageIdType" BO_ 1665 2;
BA_ "DiagResponse" BO_ 1668 1;
BA_ "GatewayHandlerEnum" BO_ 1668 4;
BA_ "GenMsgSendType" BO_ 1668 8;
BA_ "MessageIdType" BO_ 1668 2;
BA_ "DiagResponse" BO_ 1669 1;
BA_ "GatewayHandlerEnum" BO_ 1669 4;
BA_ "GenMsgSendType" BO_ 1669 8;
BA_ "MessageIdType" BO_ 1669 2;
BA_ "DiagResponse" BO_ 1666 1;
BA_ "GatewayHandlerEnum" BO_ 1666 4;
BA_ "GenMsgSendType" BO_ 1666 8;
BA_ "MessageIdType" BO_ 1666 2;
BA_ "DiagResponse" BO_ 1667 1;
BA_ "GatewayHandlerEnum" BO_ 1667 4;
BA_ "GenMsgSendType" BO_ 1667 8;
BA_ "MessageIdType" BO_ 1667 2;
BA_ "GenSigSendType" SG_ 1534 PARK_componentID 7;
BA_ "GenSigSendType" SG_ 1534 PARK_pcbaID 7;
BA_ "GenSigSendType" SG_ 1534 PARK_assemblyID 7;
BA_ "GenSigSendType" SG_ 1534 PARK_usageID 7;
BA_ "GenSigSendType" SG_ 1534 PARK_firmwareType 7;
BA_ "GenSigSNA" SG_ 574 PARK_oocDistance "511";
BA_ "LogSignal" SG_ 574 PARK_oocDistance "periodic HALF_SECOND parkOocValid";
BA_ "GenSigSNA" SG_ 574 PARK_oocConfidence "127";
BA_ "LogSignal" SG_ 574 PARK_oocConfidence "periodic HALF_SECOND parkOocValid";
BA_ "GenSigStartValue" SG_ 574 PARK_oocVehicleX 57;
BA_ "GenSigStartValue" SG_ 574 PARK_oocVehicleY 127;
BA_ "GenSigSNA" SG_ 574 PARK_oocCollisionSide "7";
BA_ "LogSignal" SG_ 574 PARK_oocCollisionSide "periodic HALF_SECOND parkOocValid";
BA_ "GenSigSNA" SG_ 574 PARK_oocUntrackedTime "63";
BA_ "LogSignal" SG_ 574 PARK_oocUntrackedTime "periodic HALF_SECOND parkOocValid";
BA_ "LogSignal" SG_ 574 PARK_oocHeight "periodic HALF_SECOND parkOocValid";
BA_ "LogSignal" SG_ 574 PARK_oocOffCourse "periodic HALF_SECOND parkOocValid";
BA_ "GenSigSNA" SG_ 846 PARK_frontLeftMiddleRawDistData "255";
BA_ "GenSigSNA" SG_ 846 PARK_frontMiddleRawDistData "255";
BA_ "GenSigSNA" SG_ 846 PARK_frontRightMiddleRawDistData "255";
BA_ "GenSigSNA" SG_ 862 PARK_rearLeftMiddleRawDistData "255";
BA_ "GenSigSNA" SG_ 862 PARK_rearMiddleRawDistData "255";
BA_ "GenSigSNA" SG_ 862 PARK_rearRightMiddleRawDistData "255";
BA_ "GenSigSNA" SG_ 926 PARK_rightSideFrontRawDistData "255";
BA_ "GenSigSNA" SG_ 926 PARK_rightSideRearRawDistData "255";
BA_ "GenSigSNA" SG_ 926 PARK_leftSideFrontRawDistData "255";
BA_ "GenSigSNA" SG_ 926 PARK_leftSideRearRawDistData "255";
BA_ "GenSigSNA" SG_ 606 PARK_pscLeftParallelObj1X "2047";
BA_ "GenSigSNA" SG_ 606 PARK_pscLeftParallelObj1Y "2047";
BA_ "GenSigSNA" SG_ 606 PARK_pscLeftParallelObj1Alpha "127";
BA_ "GenSigSNA" SG_ 606 PARK_pscLeftParallelObj2Y "2047";
BA_ "GenSigSNA" SG_ 606 PARK_pscLeftParallelObj2X "2047";
BA_ "GenSigSNA" SG_ 606 PARK_pscLeftParallelObj2Alpha "127";
BA_ "GenSigSNA" SG_ 606 PARK_pscLeftCrossObj1X "2047";
BA_ "GenSigSNA" SG_ 606 PARK_pscLeftCrossObj1Y "2047";
BA_ "GenSigSNA" SG_ 606 PARK_pscLeftCrossObj1Alpha "127";
BA_ "GenSigSNA" SG_ 606 PARK_pscLeftCrossObj2Y "2047";
BA_ "GenSigSNA" SG_ 606 PARK_pscLeftCrossObj2X "2047";
BA_ "GenSigSNA" SG_ 606 PARK_pscLeftCrossObj2Alpha "127";
BA_ "GenSigSNA" SG_ 606 PARK_pscRightParallelObj1X "2047";
BA_ "GenSigSNA" SG_ 606 PARK_pscRightParallelObj1Y "2047";
BA_ "GenSigSNA" SG_ 606 PARK_pscRightParallelObj1Alpha "127";
BA_ "GenSigSNA" SG_ 606 PARK_pscRightParallelObj2Y "2047";
BA_ "GenSigSNA" SG_ 606 PARK_pscRightParallelObj2X "2047";
BA_ "GenSigSNA" SG_ 606 PARK_pscRightParallelObj2Alpha "127";
BA_ "GenSigSNA" SG_ 606 PARK_pscRightCrossObj1X "2047";
BA_ "GenSigSNA" SG_ 606 PARK_pscRightCrossObj1Y "2047";
BA_ "GenSigSNA" SG_ 606 PARK_pscRightCrossObj1Alpha "127";
BA_ "GenSigSNA" SG_ 606 PARK_pscRightCrossObj2Y "2047";
BA_ "GenSigSNA" SG_ 606 PARK_pscRightCrossObj2X "2047";
BA_ "GenSigSNA" SG_ 606 PARK_pscRightCrossObj2Alpha "127";
BA_ "GenSigSNA" SG_ 542 PARK_pscParkStatus "7";
BA_ "GenSigSNA" SG_ 542 PARK_pscParkAbortReason "31";
BA_ "LogSignal" SG_ 542 PARK_pscParallelSpace "onChange";
BA_ "LogSignal" SG_ 542 PARK_pscCrossSpace "onChange";
BA_ "GenSigSNA" SG_ 542 PARK_pscParallelRightParkable "3";
BA_ "GenSigSNA" SG_ 542 PARK_pscParallelLeftParkable "3";
BA_ "GenSigSNA" SG_ 542 PARK_pscCrossRightParkable "3";
BA_ "GenSigSNA" SG_ 542 PARK_pscMaxVelocity "63";
BA_ "GenSigSNA" SG_ 542 PARK_pscCrossLeftParkable "3";
BA_ "GenSigSNA" SG_ 542 PARK_pscParkInstruction "7";
BA_ "LogSignal" SG_ 542 PARK_pscParkInstruction "onChange";
BA_ "GenSigSNA" SG_ 542 PARK_pscManeuverDistance "2047";
BA_ "GenSigSNA" SG_ 590 PARK_pscLeftParallelVehX "2047";
BA_ "GenSigSNA" SG_ 590 PARK_pscLeftParallelVehY "2047";
BA_ "GenSigSNA" SG_ 590 PARK_pscLeftParallelPsi "8191";
BA_ "GenSigSNA" SG_ 590 PARK_pscLeftParallelSizeX "255";
BA_ "GenSigSNA" SG_ 590 PARK_pscLeftParallelSizeY "255";
BA_ "GenSigSNA" SG_ 590 PARK_pscLeftCrossVehX "2047";
BA_ "GenSigSNA" SG_ 590 PARK_pscLeftCrossVehY "2047";
BA_ "GenSigSNA" SG_ 590 PARK_pscLeftCrossPsi "8191";
BA_ "GenSigSNA" SG_ 590 PARK_pscLeftCrossSizeX "255";
BA_ "GenSigSNA" SG_ 590 PARK_pscLeftCrossSizeY "255";
BA_ "GenSigSNA" SG_ 590 PARK_pscRightParallelVehX "2047";
BA_ "GenSigSNA" SG_ 590 PARK_pscRightParallelVehY "2047";
BA_ "GenSigSNA" SG_ 590 PARK_pscRightParallelPsi "8191";
BA_ "GenSigSNA" SG_ 590 PARK_pscRightParallelSizeX "255";
BA_ "GenSigSNA" SG_ 590 PARK_pscRightParallelSizeY "255";
BA_ "GenSigSNA" SG_ 590 PARK_pscRightCrossVehX "2047";
BA_ "GenSigSNA" SG_ 590 PARK_pscRightCrossVehY "2047";
BA_ "GenSigSNA" SG_ 590 PARK_pscRightCrossPsi "8191";
BA_ "GenSigSNA" SG_ 590 PARK_pscRightCrossSizeX "255";
BA_ "GenSigSNA" SG_ 590 PARK_pscRightCrossSizeY "255";
BA_ "GenSigSNA" SG_ 526 PARK_sdiSensor1RawDistData "511";
BA_ "GenSigSNA" SG_ 526 PARK_sdiSensor2RawDistData "511";
BA_ "GenSigSNA" SG_ 526 PARK_sdiSensor3RawDistData "511";
BA_ "GenSigSNA" SG_ 526 PARK_sdiSensor4RawDistData "511";
BA_ "GenSigSNA" SG_ 526 PARK_sdiSensor5RawDistData "511";
BA_ "GenSigSNA" SG_ 526 PARK_sdiSensor6RawDistData "511";
BA_ "GenSigSNA" SG_ 558 PARK_sdiSensor7RawDistData "511";
BA_ "GenSigSNA" SG_ 558 PARK_sdiSensor8RawDistData "511";
BA_ "GenSigSNA" SG_ 558 PARK_sdiSensor9RawDistData "511";
BA_ "GenSigSNA" SG_ 558 PARK_sdiSensor10RawDistData "511";
BA_ "GenSigSNA" SG_ 558 PARK_sdiSensor11RawDistData "511";
BA_ "GenSigSNA" SG_ 558 PARK_sdiSensor12RawDistData "511";
BA_ "GenSigSNA" SG_ 814 PARK_frontRightSensorState "3";
BA_ "GenSigSNA" SG_ 814 PARK_frontRightMiddleSensorState "3";
BA_ "GenSigSNA" SG_ 814 PARK_frontLeftMiddleSensorState "3";
BA_ "GenSigSNA" SG_ 814 PARK_frontLeftSensorState "3";
BA_ "GenSigSNA" SG_ 814 PARK_frontLeftRawDistData "255";
BA_ "GenSigSNA" SG_ 814 PARK_frontRightRawDistData "255";
BA_ "GenSigSNA" SG_ 814 PARK_systemStatusFront "3";
BA_ "GenSigSNA" SG_ 814 PARK_frontDtcPresent "3";
BA_ "GenSigSNA" SG_ 830 PARK_rearRightSensorState "3";
BA_ "GenSigSNA" SG_ 830 PARK_rearRightMiddleSensorState "3";
BA_ "GenSigSNA" SG_ 830 PARK_rearLeftMiddleSensorState "3";
BA_ "GenSigSNA" SG_ 830 PARK_rearLeftSensorState "3";
BA_ "GenSigSNA" SG_ 830 PARK_rearLeftRawDistData "255";
BA_ "GenSigSNA" SG_ 830 PARK_rearRightRawDistData "255";
BA_ "GenSigSNA" SG_ 830 PARK_systemStatusRear "3";
BA_ "GenSigSNA" SG_ 830 PARK_rearDtcPresent "3";
BA_ "GenSigSNA" SG_ 798 PARK_status "3";
BA_ "GenSigSNA" SG_ 798 PARK_serviceRequest "3";
BA_ "GenSigSNA" SG_ 798 PARK_systemDtcPresent "3";
BA_ "GenSigSNA" SG_ 798 PARK_majorVersion "255";
BA_ "GenSigStartValue" SG_ 798 PARK_majorVersion 255;
BA_ "GenSigSNA" SG_ 798 PARK_minorVersion "255";
BA_ "GenSigStartValue" SG_ 798 PARK_minorVersion 255;
BA_ "GenSigSNA" SG_ 798 PARK_subMinorVersion "255";
BA_ "GenSigStartValue" SG_ 798 PARK_subMinorVersion 255;
BA_ "LogSignal" SG_ 782 PARK_frontSVACharID "periodic TEN_SECONDS driveModeModelS";
BA_ "LogSignal" SG_ 782 PARK_pscRightCurbType "onChange";
BA_ "LogSignal" SG_ 782 PARK_rearSVACharID "periodic TEN_SECONDS driveModeModelS";
BA_ "LogSignal" SG_ 782 PARK_pscLeftCurbType "onChange";
BA_ "GenSigSNA" SG_ 782 PARK_tireFitment "3";
BA_ "GenSigSNA" SG_ 782 PARK_rackDetected "3";
BA_ "LogSignal" SG_ 782 PARK_sdiActive "onChange";
BA_ "GenSigSNA" SG_ 782 PARK_sdiNoise "3";
BA_ "LogSignal" SG_ 782 PARK_sdiNoise "onChange";
BA_ "GenSigSNA" SG_ 782 PARK_sdiBlindSpotRight "3";
BA_ "GenSigSNA" SG_ 782 PARK_sdiBlindSpotLeft "3";
BA_ "FieldType" SG_ 584 PM_ebrCmdState "PM_ebrCmdState";
BA_ "GenSigSNA" SG_ 584 PM_ebrCmdState "0";
BA_ "FieldType" SG_ 584 PM_aebState "DI_aebState";
BA_ "GenSigSNA" SG_ 584 PM_aebState "7";
BA_ "FieldType" SG_ 584 PM_vdcCmdState "PM_vdcCmdState";
BA_ "GenSigSNA" SG_ 584 PM_vdcCmdState "0";
BA_ "FlexKomComment" SG_ 517 PN14_BackupBat_Flt "Backup battery fault";
BA_ "FlexKomIsMotorola" SG_ 517 PN14_BackupBat_Flt 1;
BA_ "FlexKomSID" SG_ 517 PN14_BackupBat_Flt 117443632;
BA_ "FlexKomSigLaenge" SG_ 517 PN14_BackupBat_Flt 1;
BA_ "FlexKomSigName" SG_ 517 PN14_BackupBat_Flt "PN14_BackupBat_Flt";
BA_ "FlexKomSigStartPos" SG_ 517 PN14_BackupBat_Flt 2;
BA_ "FlexKomSigStartValue" SG_ 517 PN14_BackupBat_Flt "00h";
BA_ "GenSigCycleTime" SG_ 517 PN14_BackupBat_Flt 100;
BA_ "GenSigSendType" SG_ 517 PN14_BackupBat_Flt 5;
BA_ "GenSigTimeout_ESP_ABR" SG_ 517 PN14_BackupBat_Flt 1550;
BA_ "FlexKomComment" SG_ 517 PN14_RemPerm "Remote functions permission";
BA_ "FlexKomIsMotorola" SG_ 517 PN14_RemPerm 1;
BA_ "FlexKomSID" SG_ 517 PN14_RemPerm 117442667;
BA_ "FlexKomSigLaenge" SG_ 517 PN14_RemPerm 1;
BA_ "FlexKomSigName" SG_ 517 PN14_RemPerm "PN14_RemPerm";
BA_ "FlexKomSigStartPos" SG_ 517 PN14_RemPerm 4;
BA_ "FlexKomSigStartValue" SG_ 517 PN14_RemPerm "00h";
BA_ "GenSigCycleTime" SG_ 517 PN14_RemPerm 100;
BA_ "GenSigSendType" SG_ 517 PN14_RemPerm 5;
BA_ "FlexKomComment" SG_ 517 PN14_RevBltTns_Off_Rq "Reversible belt tensioner off request";
BA_ "FlexKomIsMotorola" SG_ 517 PN14_RevBltTns_Off_Rq 1;
BA_ "FlexKomSID" SG_ 517 PN14_RevBltTns_Off_Rq 117442375;
BA_ "FlexKomSigLaenge" SG_ 517 PN14_RevBltTns_Off_Rq 1;
BA_ "FlexKomSigName" SG_ 517 PN14_RevBltTns_Off_Rq "PN14_RevBltTns_Off_Rq";
BA_ "FlexKomSigStartPos" SG_ 517 PN14_RevBltTns_Off_Rq 5;
BA_ "FlexKomSigStartValue" SG_ 517 PN14_RevBltTns_Off_Rq "00h";
BA_ "GenSigCycleTime" SG_ 517 PN14_RevBltTns_Off_Rq 100;
BA_ "GenSigSendType" SG_ 517 PN14_RevBltTns_Off_Rq 5;
BA_ "GenSigTimeout_RBTM_FL" SG_ 517 PN14_RevBltTns_Off_Rq 5050;
BA_ "GenSigTimeout_RBTM_FR" SG_ 517 PN14_RevBltTns_Off_Rq 5050;
BA_ "FlexKomComment" SG_ 517 PN14_SBC_Add_Off_Rq "SBC additional value off request";
BA_ "FlexKomIsMotorola" SG_ 517 PN14_SBC_Add_Off_Rq 1;
BA_ "FlexKomSID" SG_ 517 PN14_SBC_Add_Off_Rq 117442376;
BA_ "FlexKomSigLaenge" SG_ 517 PN14_SBC_Add_Off_Rq 1;
BA_ "FlexKomSigName" SG_ 517 PN14_SBC_Add_Off_Rq "PN14_SBC_Add_Off_Rq";
BA_ "FlexKomSigStartPos" SG_ 517 PN14_SBC_Add_Off_Rq 6;
BA_ "FlexKomSigStartValue" SG_ 517 PN14_SBC_Add_Off_Rq "00h";
BA_ "GenSigCycleTime" SG_ 517 PN14_SBC_Add_Off_Rq 100;
BA_ "GenSigSendType" SG_ 517 PN14_SBC_Add_Off_Rq 5;
BA_ "FlexKomComment" SG_ 517 PN14_SupBat_Volt "Supply battery state";
BA_ "FlexKomIsMotorola" SG_ 517 PN14_SupBat_Volt 1;
BA_ "FlexKomSID" SG_ 517 PN14_SupBat_Volt 117440574;
BA_ "FlexKomSigLaenge" SG_ 517 PN14_SupBat_Volt 16;
BA_ "FlexKomSigName" SG_ 517 PN14_SupBat_Volt "PN14_SupBat_Stat";
BA_ "FlexKomSigStartPos" SG_ 517 PN14_SupBat_Volt 15;
BA_ "FlexKomSigStartValue" SG_ 517 PN14_SupBat_Volt "FF00h";
BA_ "GenSigSNA" SG_ 517 PN14_SupBat_Volt "255";
BA_ "GenSigSendType" SG_ 517 PN14_SupBat_Volt 10;
BA_ "GenSigStartValue" SG_ 517 PN14_SupBat_Volt 255;
BA_ "GenSigTimeout_DRVU" SG_ 517 PN14_SupBat_Volt 1050;
BA_ "GenSigTimeout_EPS" SG_ 517 PN14_SupBat_Volt 1050;
BA_ "GenSigTimeout_MPC" SG_ 517 PN14_SupBat_Volt 1050;
BA_ "GenSigTimeout_ORC" SG_ 517 PN14_SupBat_Volt 1050;
BA_ "GenSigTimeout_PTS" SG_ 517 PN14_SupBat_Volt 1050;
BA_ "GenSigTimeout_RBTM_FL" SG_ 517 PN14_SupBat_Volt 5050;
BA_ "GenSigTimeout_RBTM_FR" SG_ 517 PN14_SupBat_Volt 5050;
BA_ "GenSigTimeout_SCCM" SG_ 517 PN14_SupBat_Volt 1050;
BA_ "GenSigTimeout_SPC" SG_ 517 PN14_SupBat_Volt 1050;
BA_ "GenSigTimeout_TPM" SG_ 517 PN14_SupBat_Volt 1550;
BA_ "FlexKomComment" SG_ 517 PN14_SupBatCutSw_Stat "Supply battery state";
BA_ "FlexKomIsMotorola" SG_ 517 PN14_SupBatCutSw_Stat 1;
BA_ "FlexKomSID" SG_ 517 PN14_SupBatCutSw_Stat 117440574;
BA_ "FlexKomSigLaenge" SG_ 517 PN14_SupBatCutSw_Stat 16;
BA_ "FlexKomSigName" SG_ 517 PN14_SupBatCutSw_Stat "PN14_SupBat_Stat";
BA_ "FlexKomSigStartPos" SG_ 517 PN14_SupBatCutSw_Stat 15;
BA_ "FlexKomSigStartValue" SG_ 517 PN14_SupBatCutSw_Stat "FF00h";
BA_ "GenSigCycleTime" SG_ 517 PN14_SupBatCutSw_Stat 100;
BA_ "GenSigSNA" SG_ 517 PN14_SupBatCutSw_Stat "3";
BA_ "GenSigSendType" SG_ 517 PN14_SupBatCutSw_Stat 5;
BA_ "GenSigTimeout_DRVU" SG_ 517 PN14_SupBatCutSw_Stat 1050;
BA_ "GenSigTimeout_RBTM_FL" SG_ 517 PN14_SupBatCutSw_Stat 5050;
BA_ "GenSigTimeout_RBTM_FR" SG_ 517 PN14_SupBatCutSw_Stat 5050;
BA_ "GenSigTimeout_TPM" SG_ 517 PN14_SupBatCutSw_Stat 1550;
BA_ "FlexKomComment" SG_ 517 PN14_GM1_Actv "Supply battery state";
BA_ "FlexKomIsMotorola" SG_ 517 PN14_GM1_Actv 1;
BA_ "FlexKomSID" SG_ 517 PN14_GM1_Actv 117440574;
BA_ "FlexKomSigLaenge" SG_ 517 PN14_GM1_Actv 16;
BA_ "FlexKomSigName" SG_ 517 PN14_GM1_Actv "PN14_SupBat_Stat";
BA_ "FlexKomSigStartPos" SG_ 517 PN14_GM1_Actv 15;
BA_ "FlexKomSigStartValue" SG_ 517 PN14_GM1_Actv "FF00h";
BA_ "GenSigCycleTime" SG_ 517 PN14_GM1_Actv 100;
BA_ "GenSigSendType" SG_ 517 PN14_GM1_Actv 5;
BA_ "GenSigTimeout_SPC" SG_ 517 PN14_GM1_Actv 1050;
BA_ "FlexKomComment" SG_ 517 PN14_GM1_Avl "Supply battery state";
BA_ "FlexKomIsMotorola" SG_ 517 PN14_GM1_Avl 1;
BA_ "FlexKomSID" SG_ 517 PN14_GM1_Avl 117440574;
BA_ "FlexKomSigLaenge" SG_ 517 PN14_GM1_Avl 16;
BA_ "FlexKomSigName" SG_ 517 PN14_GM1_Avl "PN14_SupBat_Stat";
BA_ "FlexKomSigStartPos" SG_ 517 PN14_GM1_Avl 15;
BA_ "FlexKomSigStartValue" SG_ 517 PN14_GM1_Avl "FF00h";
BA_ "GenSigCycleTime" SG_ 517 PN14_GM1_Avl 100;
BA_ "GenSigSendType" SG_ 517 PN14_GM1_Avl 5;
BA_ "FlexKomComment" SG_ 517 PN14_AS_Off_Rq "Stop coordinator state";
BA_ "FlexKomIsMotorola" SG_ 517 PN14_AS_Off_Rq 1;
BA_ "FlexKomSID" SG_ 517 PN14_AS_Off_Rq 117450694;
BA_ "FlexKomSigLaenge" SG_ 517 PN14_AS_Off_Rq 4;
BA_ "FlexKomSigName" SG_ 517 PN14_AS_Off_Rq "SPCR_Stat_PN14";
BA_ "FlexKomSigStartPos" SG_ 517 PN14_AS_Off_Rq 27;
BA_ "FlexKomSigStartValue" SG_ 517 PN14_AS_Off_Rq "0Fh";
BA_ "GenSigCycleTime" SG_ 517 PN14_AS_Off_Rq 100;
BA_ "GenSigSNA" SG_ 517 PN14_AS_Off_Rq "3";
BA_ "GenSigSendType" SG_ 517 PN14_AS_Off_Rq 5;
BA_ "GenSigStartValue" SG_ 517 PN14_AS_Off_Rq 3;
BA_ "GenSigTimeout_ESP_ABR" SG_ 517 PN14_AS_Off_Rq 1550;
BA_ "FlexKomComment" SG_ 517 SPCR_Flt_PN14 "Stop coordinator state";
BA_ "FlexKomIsMotorola" SG_ 517 SPCR_Flt_PN14 1;
BA_ "FlexKomSID" SG_ 517 SPCR_Flt_PN14 117450694;
BA_ "FlexKomSigLaenge" SG_ 517 SPCR_Flt_PN14 4;
BA_ "FlexKomSigName" SG_ 517 SPCR_Flt_PN14 "SPCR_Stat_PN14";
BA_ "FlexKomSigStartPos" SG_ 517 SPCR_Flt_PN14 27;
BA_ "FlexKomSigStartValue" SG_ 517 SPCR_Flt_PN14 "0Fh";
BA_ "GenSigCycleTime" SG_ 517 SPCR_Flt_PN14 100;
BA_ "GenSigSNA" SG_ 517 SPCR_Flt_PN14 "3";
BA_ "GenSigSendType" SG_ 517 SPCR_Flt_PN14 5;
BA_ "GenSigStartValue" SG_ 517 SPCR_Flt_PN14 3;
BA_ "GenSigTimeout_ESP_ABR" SG_ 517 SPCR_Flt_PN14 1550;
BA_ "FlexKomComment" SG_ 517 LHC_PosnLmp_Rq "14 V powernet limp-home cutoff state";
BA_ "FlexKomIsMotorola" SG_ 517 LHC_PosnLmp_Rq 1;
BA_ "FlexKomSID" SG_ 517 LHC_PosnLmp_Rq 117440570;
BA_ "FlexKomSigLaenge" SG_ 517 LHC_PosnLmp_Rq 40;
BA_ "FlexKomSigName" SG_ 517 LHC_PosnLmp_Rq "PN14_LHC_Stat";
BA_ "FlexKomSigStartPos" SG_ 517 LHC_PosnLmp_Rq 31;
BA_ "FlexKomSigStartValue" SG_ 517 LHC_PosnLmp_Rq "00000000C0h";
BA_ "GenSigCycleTime" SG_ 517 LHC_PosnLmp_Rq 100;
BA_ "GenSigSendType" SG_ 517 LHC_PosnLmp_Rq 5;
BA_ "FlexKomComment" SG_ 517 LHC_PkLmp_Rq "14 V powernet limp-home cutoff state";
BA_ "FlexKomIsMotorola" SG_ 517 LHC_PkLmp_Rq 1;
BA_ "FlexKomSID" SG_ 517 LHC_PkLmp_Rq 117440570;
BA_ "FlexKomSigLaenge" SG_ 517 LHC_PkLmp_Rq 40;
BA_ "FlexKomSigName" SG_ 517 LHC_PkLmp_Rq "PN14_LHC_Stat";
BA_ "FlexKomSigStartPos" SG_ 517 LHC_PkLmp_Rq 31;
BA_ "FlexKomSigStartValue" SG_ 517 LHC_PkLmp_Rq "00000000C0h";
BA_ "GenSigCycleTime" SG_ 517 LHC_PkLmp_Rq 100;
BA_ "GenSigSendType" SG_ 517 LHC_PkLmp_Rq 5;
BA_ "FlexKomComment" SG_ 517 PN14_LHC_Actv "14 V powernet limp-home cutoff state";
BA_ "FlexKomIsMotorola" SG_ 517 PN14_LHC_Actv 1;
BA_ "FlexKomSID" SG_ 517 PN14_LHC_Actv 117440570;
BA_ "FlexKomSigLaenge" SG_ 517 PN14_LHC_Actv 40;
BA_ "FlexKomSigName" SG_ 517 PN14_LHC_Actv "PN14_LHC_Stat";
BA_ "FlexKomSigStartPos" SG_ 517 PN14_LHC_Actv 31;
BA_ "FlexKomSigStartValue" SG_ 517 PN14_LHC_Actv "00000000C0h";
BA_ "GenSigCycleTime" SG_ 517 PN14_LHC_Actv 100;
BA_ "GenSigSendType" SG_ 517 PN14_LHC_Actv 5;
BA_ "GenSigTimeout_SPC" SG_ 517 PN14_LHC_Actv 1050;
BA_ "FlexKomComment" SG_ 517 LHC_PTC6_Rq "14 V powernet limp-home cutoff state";
BA_ "FlexKomIsMotorola" SG_ 517 LHC_PTC6_Rq 1;
BA_ "FlexKomSID" SG_ 517 LHC_PTC6_Rq 117440570;
BA_ "FlexKomSigLaenge" SG_ 517 LHC_PTC6_Rq 40;
BA_ "FlexKomSigName" SG_ 517 LHC_PTC6_Rq "PN14_LHC_Stat";
BA_ "FlexKomSigStartPos" SG_ 517 LHC_PTC6_Rq 31;
BA_ "FlexKomSigStartValue" SG_ 517 LHC_PTC6_Rq "00000000C0h";
BA_ "GenSigCycleTime" SG_ 517 LHC_PTC6_Rq 100;
BA_ "GenSigSendType" SG_ 517 LHC_PTC6_Rq 5;
BA_ "FlexKomComment" SG_ 517 LHC_PTC5_Rq "14 V powernet limp-home cutoff state";
BA_ "FlexKomIsMotorola" SG_ 517 LHC_PTC5_Rq 1;
BA_ "FlexKomSID" SG_ 517 LHC_PTC5_Rq 117440570;
BA_ "FlexKomSigLaenge" SG_ 517 LHC_PTC5_Rq 40;
BA_ "FlexKomSigName" SG_ 517 LHC_PTC5_Rq "PN14_LHC_Stat";
BA_ "FlexKomSigStartPos" SG_ 517 LHC_PTC5_Rq 31;
BA_ "FlexKomSigStartValue" SG_ 517 LHC_PTC5_Rq "00000000C0h";
BA_ "GenSigCycleTime" SG_ 517 LHC_PTC5_Rq 100;
BA_ "GenSigSendType" SG_ 517 LHC_PTC5_Rq 5;
BA_ "FlexKomComment" SG_ 517 LHC_PTC4_Rq "14 V powernet limp-home cutoff state";
BA_ "FlexKomIsMotorola" SG_ 517 LHC_PTC4_Rq 1;
BA_ "FlexKomSID" SG_ 517 LHC_PTC4_Rq 117440570;
BA_ "FlexKomSigLaenge" SG_ 517 LHC_PTC4_Rq 40;
BA_ "FlexKomSigName" SG_ 517 LHC_PTC4_Rq "PN14_LHC_Stat";
BA_ "FlexKomSigStartPos" SG_ 517 LHC_PTC4_Rq 31;
BA_ "FlexKomSigStartValue" SG_ 517 LHC_PTC4_Rq "00000000C0h";
BA_ "GenSigCycleTime" SG_ 517 LHC_PTC4_Rq 100;
BA_ "GenSigSendType" SG_ 517 LHC_PTC4_Rq 5;
BA_ "FlexKomComment" SG_ 517 LHC_PTC3_Rq "14 V powernet limp-home cutoff state";
BA_ "FlexKomIsMotorola" SG_ 517 LHC_PTC3_Rq 1;
BA_ "FlexKomSID" SG_ 517 LHC_PTC3_Rq 117440570;
BA_ "FlexKomSigLaenge" SG_ 517 LHC_PTC3_Rq 40;
BA_ "FlexKomSigName" SG_ 517 LHC_PTC3_Rq "PN14_LHC_Stat";
BA_ "FlexKomSigStartPos" SG_ 517 LHC_PTC3_Rq 31;
BA_ "FlexKomSigStartValue" SG_ 517 LHC_PTC3_Rq "00000000C0h";
BA_ "GenSigCycleTime" SG_ 517 LHC_PTC3_Rq 100;
BA_ "GenSigSendType" SG_ 517 LHC_PTC3_Rq 5;
BA_ "FlexKomComment" SG_ 517 LHC_PTC2_Rq "14 V powernet limp-home cutoff state";
BA_ "FlexKomIsMotorola" SG_ 517 LHC_PTC2_Rq 1;
BA_ "FlexKomSID" SG_ 517 LHC_PTC2_Rq 117440570;
BA_ "FlexKomSigLaenge" SG_ 517 LHC_PTC2_Rq 40;
BA_ "FlexKomSigName" SG_ 517 LHC_PTC2_Rq "PN14_LHC_Stat";
BA_ "FlexKomSigStartPos" SG_ 517 LHC_PTC2_Rq 31;
BA_ "FlexKomSigStartValue" SG_ 517 LHC_PTC2_Rq "00000000C0h";
BA_ "GenSigCycleTime" SG_ 517 LHC_PTC2_Rq 100;
BA_ "GenSigSendType" SG_ 517 LHC_PTC2_Rq 5;
BA_ "FlexKomComment" SG_ 517 LHC_PTC1_Rq "14 V powernet limp-home cutoff state";
BA_ "FlexKomIsMotorola" SG_ 517 LHC_PTC1_Rq 1;
BA_ "FlexKomSID" SG_ 517 LHC_PTC1_Rq 117440570;
BA_ "FlexKomSigLaenge" SG_ 517 LHC_PTC1_Rq 40;
BA_ "FlexKomSigName" SG_ 517 LHC_PTC1_Rq "PN14_LHC_Stat";
BA_ "FlexKomSigStartPos" SG_ 517 LHC_PTC1_Rq 31;
BA_ "FlexKomSigStartValue" SG_ 517 LHC_PTC1_Rq "00000000C0h";
BA_ "GenSigCycleTime" SG_ 517 LHC_PTC1_Rq 100;
BA_ "GenSigSendType" SG_ 517 LHC_PTC1_Rq 5;
BA_ "FlexKomComment" SG_ 517 LHC_IntFan_R_50_Rq "14 V powernet limp-home cutoff state";
BA_ "FlexKomIsMotorola" SG_ 517 LHC_IntFan_R_50_Rq 1;
BA_ "FlexKomSID" SG_ 517 LHC_IntFan_R_50_Rq 117440570;
BA_ "FlexKomSigLaenge" SG_ 517 LHC_IntFan_R_50_Rq 40;
BA_ "FlexKomSigName" SG_ 517 LHC_IntFan_R_50_Rq "PN14_LHC_Stat";
BA_ "FlexKomSigStartPos" SG_ 517 LHC_IntFan_R_50_Rq 31;
BA_ "FlexKomSigStartValue" SG_ 517 LHC_IntFan_R_50_Rq "00000000C0h";
BA_ "GenSigCycleTime" SG_ 517 LHC_IntFan_R_50_Rq 100;
BA_ "GenSigSendType" SG_ 517 LHC_IntFan_R_50_Rq 5;
BA_ "FlexKomComment" SG_ 517 LHC_IntFan_F_50_Rq "14 V powernet limp-home cutoff state";
BA_ "FlexKomIsMotorola" SG_ 517 LHC_IntFan_F_50_Rq 1;
BA_ "FlexKomSID" SG_ 517 LHC_IntFan_F_50_Rq 117440570;
BA_ "FlexKomSigLaenge" SG_ 517 LHC_IntFan_F_50_Rq 40;
BA_ "FlexKomSigName" SG_ 517 LHC_IntFan_F_50_Rq "PN14_LHC_Stat";
BA_ "FlexKomSigStartPos" SG_ 517 LHC_IntFan_F_50_Rq 31;
BA_ "FlexKomSigStartValue" SG_ 517 LHC_IntFan_F_50_Rq "00000000C0h";
BA_ "GenSigCycleTime" SG_ 517 LHC_IntFan_F_50_Rq 100;
BA_ "GenSigSendType" SG_ 517 LHC_IntFan_F_50_Rq 5;
BA_ "FlexKomComment" SG_ 517 LHC_DSH_Stg2_Rq "14 V powernet limp-home cutoff state";
BA_ "FlexKomIsMotorola" SG_ 517 LHC_DSH_Stg2_Rq 1;
BA_ "FlexKomSID" SG_ 517 LHC_DSH_Stg2_Rq 117440570;
BA_ "FlexKomSigLaenge" SG_ 517 LHC_DSH_Stg2_Rq 40;
BA_ "FlexKomSigName" SG_ 517 LHC_DSH_Stg2_Rq "PN14_LHC_Stat";
BA_ "FlexKomSigStartPos" SG_ 517 LHC_DSH_Stg2_Rq 31;
BA_ "FlexKomSigStartValue" SG_ 517 LHC_DSH_Stg2_Rq "00000000C0h";
BA_ "GenSigCycleTime" SG_ 517 LHC_DSH_Stg2_Rq 100;
BA_ "GenSigSendType" SG_ 517 LHC_DSH_Stg2_Rq 5;
BA_ "FlexKomComment" SG_ 517 LHC_DSH_Stg1_Rq "14 V powernet limp-home cutoff state";
BA_ "FlexKomIsMotorola" SG_ 517 LHC_DSH_Stg1_Rq 1;
BA_ "FlexKomSID" SG_ 517 LHC_DSH_Stg1_Rq 117440570;
BA_ "FlexKomSigLaenge" SG_ 517 LHC_DSH_Stg1_Rq 40;
BA_ "FlexKomSigName" SG_ 517 LHC_DSH_Stg1_Rq "PN14_LHC_Stat";
BA_ "FlexKomSigStartPos" SG_ 517 LHC_DSH_Stg1_Rq 31;
BA_ "FlexKomSigStartValue" SG_ 517 LHC_DSH_Stg1_Rq "00000000C0h";
BA_ "GenSigCycleTime" SG_ 517 LHC_DSH_Stg1_Rq 100;
BA_ "GenSigSendType" SG_ 517 LHC_DSH_Stg1_Rq 5;
BA_ "FlexKomComment" SG_ 517 LHC_SeatHtStg3_Rq "14 V powernet limp-home cutoff state";
BA_ "FlexKomIsMotorola" SG_ 517 LHC_SeatHtStg3_Rq 1;
BA_ "FlexKomSID" SG_ 517 LHC_SeatHtStg3_Rq 117440570;
BA_ "FlexKomSigLaenge" SG_ 517 LHC_SeatHtStg3_Rq 40;
BA_ "FlexKomSigName" SG_ 517 LHC_SeatHtStg3_Rq "PN14_LHC_Stat";
BA_ "FlexKomSigStartPos" SG_ 517 LHC_SeatHtStg3_Rq 31;
BA_ "FlexKomSigStartValue" SG_ 517 LHC_SeatHtStg3_Rq "00000000C0h";
BA_ "GenSigCycleTime" SG_ 517 LHC_SeatHtStg3_Rq 100;
BA_ "GenSigSendType" SG_ 517 LHC_SeatHtStg3_Rq 5;
BA_ "FlexKomComment" SG_ 517 LHC_SeatHtStg2_Rq "14 V powernet limp-home cutoff state";
BA_ "FlexKomIsMotorola" SG_ 517 LHC_SeatHtStg2_Rq 1;
BA_ "FlexKomSID" SG_ 517 LHC_SeatHtStg2_Rq 117440570;
BA_ "FlexKomSigLaenge" SG_ 517 LHC_SeatHtStg2_Rq 40;
BA_ "FlexKomSigName" SG_ 517 LHC_SeatHtStg2_Rq "PN14_LHC_Stat";
BA_ "FlexKomSigStartPos" SG_ 517 LHC_SeatHtStg2_Rq 31;
BA_ "FlexKomSigStartValue" SG_ 517 LHC_SeatHtStg2_Rq "00000000C0h";
BA_ "GenSigCycleTime" SG_ 517 LHC_SeatHtStg2_Rq 100;
BA_ "GenSigSendType" SG_ 517 LHC_SeatHtStg2_Rq 5;
BA_ "FlexKomComment" SG_ 517 LHC_SeatHtStg1_Rq "14 V powernet limp-home cutoff state";
BA_ "FlexKomIsMotorola" SG_ 517 LHC_SeatHtStg1_Rq 1;
BA_ "FlexKomSID" SG_ 517 LHC_SeatHtStg1_Rq 117440570;
BA_ "FlexKomSigLaenge" SG_ 517 LHC_SeatHtStg1_Rq 40;
BA_ "FlexKomSigName" SG_ 517 LHC_SeatHtStg1_Rq "PN14_LHC_Stat";
BA_ "FlexKomSigStartPos" SG_ 517 LHC_SeatHtStg1_Rq 31;
BA_ "FlexKomSigStartValue" SG_ 517 LHC_SeatHtStg1_Rq "00000000C0h";
BA_ "GenSigCycleTime" SG_ 517 LHC_SeatHtStg1_Rq 100;
BA_ "GenSigSendType" SG_ 517 LHC_SeatHtStg1_Rq 5;
BA_ "FlexKomComment" SG_ 517 LHC_SeatVn_Rq "14 V powernet limp-home cutoff state";
BA_ "FlexKomIsMotorola" SG_ 517 LHC_SeatVn_Rq 1;
BA_ "FlexKomSID" SG_ 517 LHC_SeatVn_Rq 117440570;
BA_ "FlexKomSigLaenge" SG_ 517 LHC_SeatVn_Rq 40;
BA_ "FlexKomSigName" SG_ 517 LHC_SeatVn_Rq "PN14_LHC_Stat";
BA_ "FlexKomSigStartPos" SG_ 517 LHC_SeatVn_Rq 31;
BA_ "FlexKomSigStartValue" SG_ 517 LHC_SeatVn_Rq "00000000C0h";
BA_ "GenSigCycleTime" SG_ 517 LHC_SeatVn_Rq 100;
BA_ "GenSigSendType" SG_ 517 LHC_SeatVn_Rq 5;
BA_ "FlexKomComment" SG_ 517 LHC_Tlm_Rq "14 V powernet limp-home cutoff state";
BA_ "FlexKomIsMotorola" SG_ 517 LHC_Tlm_Rq 1;
BA_ "FlexKomSID" SG_ 517 LHC_Tlm_Rq 117440570;
BA_ "FlexKomSigLaenge" SG_ 517 LHC_Tlm_Rq 40;
BA_ "FlexKomSigName" SG_ 517 LHC_Tlm_Rq "PN14_LHC_Stat";
BA_ "FlexKomSigStartPos" SG_ 517 LHC_Tlm_Rq 31;
BA_ "FlexKomSigStartValue" SG_ 517 LHC_Tlm_Rq "00000000C0h";
BA_ "GenSigCycleTime" SG_ 517 LHC_Tlm_Rq 100;
BA_ "GenSigSendType" SG_ 517 LHC_Tlm_Rq 5;
BA_ "FlexKomComment" SG_ 517 LHC_TrlrSock_Rq "14 V powernet limp-home cutoff state";
BA_ "FlexKomIsMotorola" SG_ 517 LHC_TrlrSock_Rq 1;
BA_ "FlexKomSID" SG_ 517 LHC_TrlrSock_Rq 117440570;
BA_ "FlexKomSigLaenge" SG_ 517 LHC_TrlrSock_Rq 40;
BA_ "FlexKomSigName" SG_ 517 LHC_TrlrSock_Rq "PN14_LHC_Stat";
BA_ "FlexKomSigStartPos" SG_ 517 LHC_TrlrSock_Rq 31;
BA_ "FlexKomSigStartValue" SG_ 517 LHC_TrlrSock_Rq "00000000C0h";
BA_ "GenSigCycleTime" SG_ 517 LHC_TrlrSock_Rq 100;
BA_ "GenSigSendType" SG_ 517 LHC_TrlrSock_Rq 5;
BA_ "FlexKomComment" SG_ 517 LHC_WprPkHt_Rq "14 V powernet limp-home cutoff state";
BA_ "FlexKomIsMotorola" SG_ 517 LHC_WprPkHt_Rq 1;
BA_ "FlexKomSID" SG_ 517 LHC_WprPkHt_Rq 117440570;
BA_ "FlexKomSigLaenge" SG_ 517 LHC_WprPkHt_Rq 40;
BA_ "FlexKomSigName" SG_ 517 LHC_WprPkHt_Rq "PN14_LHC_Stat";
BA_ "FlexKomSigStartPos" SG_ 517 LHC_WprPkHt_Rq 31;
BA_ "FlexKomSigStartValue" SG_ 517 LHC_WprPkHt_Rq "00000000C0h";
BA_ "GenSigCycleTime" SG_ 517 LHC_WprPkHt_Rq 100;
BA_ "GenSigSendType" SG_ 517 LHC_WprPkHt_Rq 5;
BA_ "FlexKomComment" SG_ 517 LHC_EBL_Rq "14 V powernet limp-home cutoff state";
BA_ "FlexKomIsMotorola" SG_ 517 LHC_EBL_Rq 1;
BA_ "FlexKomSID" SG_ 517 LHC_EBL_Rq 117440570;
BA_ "FlexKomSigLaenge" SG_ 517 LHC_EBL_Rq 40;
BA_ "FlexKomSigName" SG_ 517 LHC_EBL_Rq "PN14_LHC_Stat";
BA_ "FlexKomSigStartPos" SG_ 517 LHC_EBL_Rq 31;
BA_ "FlexKomSigStartValue" SG_ 517 LHC_EBL_Rq "00000000C0h";
BA_ "GenSigCycleTime" SG_ 517 LHC_EBL_Rq 100;
BA_ "GenSigSendType" SG_ 517 LHC_EBL_Rq 5;
BA_ "FlexKomComment" SG_ 517 LHC_StW_Ht_Rq "14 V powernet limp-home cutoff state";
BA_ "FlexKomIsMotorola" SG_ 517 LHC_StW_Ht_Rq 1;
BA_ "FlexKomSID" SG_ 517 LHC_StW_Ht_Rq 117440570;
BA_ "FlexKomSigLaenge" SG_ 517 LHC_StW_Ht_Rq 40;
BA_ "FlexKomSigName" SG_ 517 LHC_StW_Ht_Rq "PN14_LHC_Stat";
BA_ "FlexKomSigStartPos" SG_ 517 LHC_StW_Ht_Rq 31;
BA_ "FlexKomSigStartValue" SG_ 517 LHC_StW_Ht_Rq "00000000C0h";
BA_ "GenSigCycleTime" SG_ 517 LHC_StW_Ht_Rq 100;
BA_ "GenSigSendType" SG_ 517 LHC_StW_Ht_Rq 5;
BA_ "FlexKomComment" SG_ 517 LHC_WShHt_Rq "14 V powernet limp-home cutoff state";
BA_ "FlexKomIsMotorola" SG_ 517 LHC_WShHt_Rq 1;
BA_ "FlexKomSID" SG_ 517 LHC_WShHt_Rq 117440570;
BA_ "FlexKomSigLaenge" SG_ 517 LHC_WShHt_Rq 40;
BA_ "FlexKomSigName" SG_ 517 LHC_WShHt_Rq "PN14_LHC_Stat";
BA_ "FlexKomSigStartPos" SG_ 517 LHC_WShHt_Rq 31;
BA_ "FlexKomSigStartValue" SG_ 517 LHC_WShHt_Rq "00000000C0h";
BA_ "GenSigCycleTime" SG_ 517 LHC_WShHt_Rq 100;
BA_ "GenSigSendType" SG_ 517 LHC_WShHt_Rq 5;
BA_ "FlexKomComment" SG_ 517 LHC_MirrHt_Rq "14 V powernet limp-home cutoff state";
BA_ "FlexKomIsMotorola" SG_ 517 LHC_MirrHt_Rq 1;
BA_ "FlexKomSID" SG_ 517 LHC_MirrHt_Rq 117440570;
BA_ "FlexKomSigLaenge" SG_ 517 LHC_MirrHt_Rq 40;
BA_ "FlexKomSigName" SG_ 517 LHC_MirrHt_Rq "PN14_LHC_Stat";
BA_ "FlexKomSigStartPos" SG_ 517 LHC_MirrHt_Rq 31;
BA_ "FlexKomSigStartValue" SG_ 517 LHC_MirrHt_Rq "00000000C0h";
BA_ "GenSigCycleTime" SG_ 517 LHC_MirrHt_Rq 100;
BA_ "GenSigSendType" SG_ 517 LHC_MirrHt_Rq 5;
BA_ "FlexKomComment" SG_ 517 LHC_CoolBox_R_Rq "14 V powernet limp-home cutoff state";
BA_ "FlexKomIsMotorola" SG_ 517 LHC_CoolBox_R_Rq 1;
BA_ "FlexKomSID" SG_ 517 LHC_CoolBox_R_Rq 117440570;
BA_ "FlexKomSigLaenge" SG_ 517 LHC_CoolBox_R_Rq 40;
BA_ "FlexKomSigName" SG_ 517 LHC_CoolBox_R_Rq "PN14_LHC_Stat";
BA_ "FlexKomSigStartPos" SG_ 517 LHC_CoolBox_R_Rq 31;
BA_ "FlexKomSigStartValue" SG_ 517 LHC_CoolBox_R_Rq "00000000C0h";
BA_ "GenSigCycleTime" SG_ 517 LHC_CoolBox_R_Rq 100;
BA_ "GenSigSendType" SG_ 517 LHC_CoolBox_R_Rq 5;
BA_ "FlexKomComment" SG_ 517 LHC_EngFan_50_Rq "14 V powernet limp-home cutoff state";
BA_ "FlexKomIsMotorola" SG_ 517 LHC_EngFan_50_Rq 1;
BA_ "FlexKomSID" SG_ 517 LHC_EngFan_50_Rq 117440570;
BA_ "FlexKomSigLaenge" SG_ 517 LHC_EngFan_50_Rq 40;
BA_ "FlexKomSigName" SG_ 517 LHC_EngFan_50_Rq "PN14_LHC_Stat";
BA_ "FlexKomSigStartPos" SG_ 517 LHC_EngFan_50_Rq 31;
BA_ "FlexKomSigStartValue" SG_ 517 LHC_EngFan_50_Rq "00000000C0h";
BA_ "GenSigCycleTime" SG_ 517 LHC_EngFan_50_Rq 100;
BA_ "GenSigSendType" SG_ 517 LHC_EngFan_50_Rq 5;
BA_ "FlexKomComment" SG_ 517 LHC_FogLmp_Ft_Rq "14 V powernet limp-home cutoff state";
BA_ "FlexKomIsMotorola" SG_ 517 LHC_FogLmp_Ft_Rq 1;
BA_ "FlexKomSID" SG_ 517 LHC_FogLmp_Ft_Rq 117440570;
BA_ "FlexKomSigLaenge" SG_ 517 LHC_FogLmp_Ft_Rq 40;
BA_ "FlexKomSigName" SG_ 517 LHC_FogLmp_Ft_Rq "PN14_LHC_Stat";
BA_ "FlexKomSigStartPos" SG_ 517 LHC_FogLmp_Ft_Rq 31;
BA_ "FlexKomSigStartValue" SG_ 517 LHC_FogLmp_Ft_Rq "00000000C0h";
BA_ "GenSigCycleTime" SG_ 517 LHC_FogLmp_Ft_Rq 100;
BA_ "GenSigSendType" SG_ 517 LHC_FogLmp_Ft_Rq 5;
BA_ "FlexKomComment" SG_ 517 LHC_TrkSock_Rq "14 V powernet limp-home cutoff state";
BA_ "FlexKomIsMotorola" SG_ 517 LHC_TrkSock_Rq 1;
BA_ "FlexKomSID" SG_ 517 LHC_TrkSock_Rq 117440570;
BA_ "FlexKomSigLaenge" SG_ 517 LHC_TrkSock_Rq 40;
BA_ "FlexKomSigName" SG_ 517 LHC_TrkSock_Rq "PN14_LHC_Stat";
BA_ "FlexKomSigStartPos" SG_ 517 LHC_TrkSock_Rq 31;
BA_ "FlexKomSigStartValue" SG_ 517 LHC_TrkSock_Rq "00000000C0h";
BA_ "GenSigCycleTime" SG_ 517 LHC_TrkSock_Rq 100;
BA_ "GenSigSendType" SG_ 517 LHC_TrkSock_Rq 5;
BA_ "FlexKomComment" SG_ 517 LHC_ComfLmp_Rq "14 V powernet limp-home cutoff state";
BA_ "FlexKomIsMotorola" SG_ 517 LHC_ComfLmp_Rq 1;
BA_ "FlexKomSID" SG_ 517 LHC_ComfLmp_Rq 117440570;
BA_ "FlexKomSigLaenge" SG_ 517 LHC_ComfLmp_Rq 40;
BA_ "FlexKomSigName" SG_ 517 LHC_ComfLmp_Rq "PN14_LHC_Stat";
BA_ "FlexKomSigStartPos" SG_ 517 LHC_ComfLmp_Rq 31;
BA_ "FlexKomSigStartValue" SG_ 517 LHC_ComfLmp_Rq "00000000C0h";
BA_ "GenSigCycleTime" SG_ 517 LHC_ComfLmp_Rq 100;
BA_ "GenSigSendType" SG_ 517 LHC_ComfLmp_Rq 5;
BA_ "FlexKomComment" SG_ 517 LHC_RHU_Rq "14 V powernet limp-home cutoff state";
BA_ "FlexKomIsMotorola" SG_ 517 LHC_RHU_Rq 1;
BA_ "FlexKomSID" SG_ 517 LHC_RHU_Rq 117440570;
BA_ "FlexKomSigLaenge" SG_ 517 LHC_RHU_Rq 40;
BA_ "FlexKomSigName" SG_ 517 LHC_RHU_Rq "PN14_LHC_Stat";
BA_ "FlexKomSigStartPos" SG_ 517 LHC_RHU_Rq 31;
BA_ "FlexKomSigStartValue" SG_ 517 LHC_RHU_Rq "00000000C0h";
BA_ "GenSigCycleTime" SG_ 517 LHC_RHU_Rq 100;
BA_ "GenSigSendType" SG_ 517 LHC_RHU_Rq 5;
BA_ "FlexKomComment" SG_ 517 LHC_ICH_Rq "14 V powernet limp-home cutoff state";
BA_ "FlexKomIsMotorola" SG_ 517 LHC_ICH_Rq 1;
BA_ "FlexKomSID" SG_ 517 LHC_ICH_Rq 117440570;
BA_ "FlexKomSigLaenge" SG_ 517 LHC_ICH_Rq 40;
BA_ "FlexKomSigName" SG_ 517 LHC_ICH_Rq "PN14_LHC_Stat";
BA_ "FlexKomSigStartPos" SG_ 517 LHC_ICH_Rq 31;
BA_ "FlexKomSigStartValue" SG_ 517 LHC_ICH_Rq "00000000C0h";
BA_ "GenSigCycleTime" SG_ 517 LHC_ICH_Rq 100;
BA_ "GenSigSendType" SG_ 517 LHC_ICH_Rq 5;
BA_ "FlexKomComment" SG_ 517 PN14_LHC_Taxi_Rq "14 V powernet limp-home cutoff state";
BA_ "FlexKomIsMotorola" SG_ 517 PN14_LHC_Taxi_Rq 1;
BA_ "FlexKomSID" SG_ 517 PN14_LHC_Taxi_Rq 117440570;
BA_ "FlexKomSigLaenge" SG_ 517 PN14_LHC_Taxi_Rq 40;
BA_ "FlexKomSigName" SG_ 517 PN14_LHC_Taxi_Rq "PN14_LHC_Stat";
BA_ "FlexKomSigStartPos" SG_ 517 PN14_LHC_Taxi_Rq 31;
BA_ "FlexKomSigStartValue" SG_ 517 PN14_LHC_Taxi_Rq "00000000C0h";
BA_ "GenSigCycleTime" SG_ 517 PN14_LHC_Taxi_Rq 100;
BA_ "GenSigSendType" SG_ 517 PN14_LHC_Taxi_Rq 5;
BA_ "FlexKomComment" SG_ 517 PN14_TransMd_Stat "14 V powernet limp-home cutoff state";
BA_ "FlexKomIsMotorola" SG_ 517 PN14_TransMd_Stat 1;
BA_ "FlexKomSID" SG_ 517 PN14_TransMd_Stat 117440570;
BA_ "FlexKomSigLaenge" SG_ 517 PN14_TransMd_Stat 40;
BA_ "FlexKomSigName" SG_ 517 PN14_TransMd_Stat "PN14_LHC_Stat";
BA_ "FlexKomSigStartPos" SG_ 517 PN14_TransMd_Stat 31;
BA_ "FlexKomSigStartValue" SG_ 517 PN14_TransMd_Stat "00000000C0h";
BA_ "GenSigCycleTime" SG_ 517 PN14_TransMd_Stat 100;
BA_ "GenSigSNA" SG_ 517 PN14_TransMd_Stat "3";
BA_ "GenSigSendType" SG_ 517 PN14_TransMd_Stat 5;
BA_ "GenSigStartValue" SG_ 517 PN14_TransMd_Stat 3;
BA_ "GenSigSNA" SG_ 1365 RADC_a034_vehDynamicsErrType "0";
BA_ "GenSigSNA" SG_ 1365 RADC_a047_chassisTypeExp "7";
BA_ "GenSigSNA" SG_ 1365 RADC_a047_chassisTypeRx "7";
BA_ "GenSigSNA" SG_ 1365 RADC_a048_airSuspensionExp "7";
BA_ "GenSigSNA" SG_ 1365 RADC_a048_airSuspensionRx "7";
BA_ "GenSigSNA" SG_ 1365 RADC_a049_fourWheelDriveExp "3";
BA_ "GenSigSNA" SG_ 1365 RADC_a049_fourWheelDriveRx "3";
BA_ "GenSigSNA" SG_ 1365 RADC_a050_countryExp "8191";
BA_ "GenSigSNA" SG_ 1365 RADC_a050_countryRx "8191";
BA_ "GenSigSNA" SG_ 1365 RADC_a051_epasTypeExp "7";
BA_ "GenSigSNA" SG_ 1365 RADC_a051_epasTypeRx "7";
BA_ "GenSigSNA" SG_ 1365 RADC_a052_radarPositionExp "7";
BA_ "GenSigSNA" SG_ 1365 RADC_a052_radarPositionRx "7";
BA_ "FieldType" SG_ 1329 RADC_infoIndex "infoIndex";
BA_ "GenSigCycleTime" SG_ 1329 RADC_infoIndex 2000;
BA_ "GenSigStartValue" SG_ 1329 RADC_infoApplicationCRC 4294967295;
BA_ "GenSigStartValue" SG_ 1329 RADC_infoPlatformType 255;
BA_ "GenSigSendType" SG_ 1665 RADC_udsResponseData 1;
BA_ "GenSigSendType" SG_ 1668 RADFL_udsResponseData 1;
BA_ "GenSigSendType" SG_ 1669 RADFR_udsResponseData 1;
BA_ "GenSigSendType" SG_ 1666 RADRL_udsResponseData 1;
BA_ "GenSigSendType" SG_ 1667 RADRR_udsResponseData 1;
VAL_ 1486 PARK_sw060_subCode 254 "MID_ADC_E_TOUT_N" 253 "MID_ADC_E_INIT_FAILURE_N" 252 "MID_CAN_E_TIMEOUT_N" 251 "MID_CANIF_E_FULL_TX_BUFFER_N" 250 "MID_CANIF_E_INVALID_DLC_N" 249 "MID_CANIF_E_INVALID_TXPDUID_N" 248 "MID_CANIF_E_STOPPED_N" 247 "MID_CANNM_E_CANIF_TRANSMIT_ERROR_N" 246 "MID_CANNM_E_INIT_FAILED_N" 245 "MID_CANNM_E_NETWORK_TIMEOUT_N" 244 "MID_CANSM_E_BUSOFF_NETWORK_N" 243 "MID_CANTP_E_COM_DIAMANT_N" 242 "MID_ECU_E_EEP_DATAFLASH_LAYOUT_N" 241 "MID_ECU_E_RAM_N" 240 "MID_ECU_E_ROM_N" 239 "MID_FEE_E_LAYOUT_FAILED_N" 238 "MID_NVM_E_CONFIG_FAILED_N" 237 "MID_CAN_DASInvalidData_N" 236 "MID_CAN_C_BUSOFF_N" 235 "MID_NVM_E_INTEGRITY_FAILED_N" 234 "MID_NVM_E_REQ_FAILED_N" 233 "MID_PA_E_ASIC_COM_FAILURE_N" 232 "MID_PA_E_ASIC_HW_FAILURE_N" 231 "MID_PA_E_ENGINE_START_INVALID_N" 230 "MID_PA_E_EPS_STATUS_INVALID_N" 229 "MID_PA_E_GEAR_INVALID_N" 228 "MID_PA_E_LONG_ACC_INVALID_N" 227 "MID_PA_E_OUTSIDE_TEMP_INVALID_N" 226 "MID_CAN_EPASInvalidData_N" 225 "MID_PA_E_SPEED_INVALID_N" 224 "MID_PA_E_SVA_BLOCKED_USS_FL_N" 223 "MID_PA_E_SVA_BLOCKED_USS_FR_N" 222 "MID_PA_E_SVA_BLOCKED_USS_RL_N" 221 "MID_PA_E_SVA_BLOCKED_USS_RR_N" 220 "MID_PA_E_SWA_INVALID_N" 219 "MID_PA_E_SWCPA_APT_MONITOR_FAILURE_N" 218 "MID_PA_E_SWCPA_INHIBIT_HSS_PWRLOCK_N" 217 "MID_PA_E_SWCPA_INIT_FAILURE_N" 216 "MID_PA_E_SWCPA_PARFAILURE_N" 215 "MID_CAN_EPBInvalidData_N" 214 "MID_PA_E_UBAT_HIGH_N" 213 "MID_PA_E_UBAT_LOW_N" 212 "MID_PA_E_USENS_OVERTEMPERATURE_N" 211 "MID_PA_E_USENS_OVERVOLTAGE_N" 210 "MID_PA_E_USENS_SHORT_2_GND_N" 209 "MID_PA_E_USENS_SHORT_2_UBAT_N" 208 "MID_PA_E_USENS_UNDERVOLTAGE_N" 207 "MID_PA_E_USS_01_NO_COM_N" 206 "MID_PA_E_USS_01_OPEN_N" 205 "MID_PA_E_USS_01_RING_TOO_SHORT_N" 204 "MID_PA_E_USS_01_RINGING_TOO_LONG_N" 203 "MID_PA_E_USS_01_SHORT_2_GND_N" 202 "MID_PA_E_USS_01_SHORT_2_USENS_N" 201 "MID_PA_E_USS_01_STATE_COM_VERIFIED_N" 200 "MID_PA_E_USS_01_STATE_OFFSET_N" 199 "MID_PA_E_USS_01_STATE_PROG_N" 198 "MID_PA_E_USS_01_STATE_TYPE_N" 197 "MID_PA_E_USS_02_NO_COM_N" 196 "MID_PA_E_USS_02_OPEN_N" 195 "MID_PA_E_USS_02_RING_TOO_SHORT_N" 194 "MID_PA_E_USS_02_RINGING_TOO_LONG_N" 193 "MID_PA_E_USS_02_SHORT_2_GND_N" 192 "MID_PA_E_USS_02_SHORT_2_USENS_N" 191 "MID_PA_E_USS_02_STATE_COM_VERIFIED_N" 190 "MID_PA_E_USS_02_STATE_OFFSET_N" 189 "MID_PA_E_USS_02_STATE_PROG_N" 188 "MID_PA_E_USS_02_STATE_TYPE_N" 187 "MID_PA_E_USS_03_NO_COM_N" 186 "MID_PA_E_USS_03_OPEN_N" 185 "MID_PA_E_USS_03_RING_TOO_SHORT_N" 184 "MID_PA_E_USS_03_RINGING_TOO_LONG_N" 183 "MID_PA_E_USS_03_SHORT_2_GND_N" 182 "MID_PA_E_USS_03_SHORT_2_USENS_N" 181 "MID_PA_E_USS_03_STATE_COM_VERIFIED_N" 180 "MID_PA_E_USS_03_STATE_OFFSET_N" 179 "MID_PA_E_USS_03_STATE_PROG_N" 178 "MID_PA_E_USS_03_STATE_TYPE_N" 177 "MID_PA_E_USS_04_NO_COM_N" 176 "MID_PA_E_USS_04_OPEN_N" 175 "MID_PA_E_USS_04_RING_TOO_SHORT_N" 174 "MID_PA_E_USS_04_RINGING_TOO_LONG_N" 173 "MID_PA_E_USS_04_SHORT_2_GND_N" 172 "MID_PA_E_USS_04_SHORT_2_USENS_N" 171 "MID_PA_E_USS_04_STATE_COM_VERIFIED_N" 170 "MID_PA_E_USS_04_STATE_OFFSET_N" 169 "MID_PA_E_USS_04_STATE_PROG_N" 168 "MID_PA_E_USS_04_STATE_TYPE_N" 167 "MID_PA_E_USS_05_NO_COM_N" 166 "MID_PA_E_USS_05_OPEN_N" 165 "MID_PA_E_USS_05_RING_TOO_SHORT_N" 164 "MID_PA_E_USS_05_RINGING_TOO_LONG_N" 163 "MID_PA_E_USS_05_SHORT_2_GND_N" 162 "MID_PA_E_USS_05_SHORT_2_USENS_N" 161 "MID_PA_E_USS_05_STATE_COM_VERIFIED_N" 160 "MID_PA_E_USS_05_STATE_OFFSET_N" 159 "MID_PA_E_USS_05_STATE_PROG_N" 158 "MID_PA_E_USS_05_STATE_TYPE_N" 157 "MID_PA_E_USS_06_NO_COM_N" 156 "MID_PA_E_USS_06_OPEN_N" 155 "MID_PA_E_USS_06_RING_TOO_SHORT_N" 154 "MID_PA_E_USS_06_RINGING_TOO_LONG_N" 153 "MID_PA_E_USS_06_SHORT_2_GND_N" 152 "MID_PA_E_USS_06_SHORT_2_USENS_N" 151 "MID_PA_E_USS_06_STATE_COM_VERIFIED_N" 150 "MID_PA_E_USS_06_STATE_OFFSET_N" 149 "MID_PA_E_USS_06_STATE_PROG_N" 148 "MID_PA_E_USS_06_STATE_TYPE_N" 147 "MID_CAN_ESPInvalidData_N" 146 "MID_CAN_GTWInvalidData_N" 145 "MID_CAN_SCCMInvalidData_N" 144 "MID_CAN_DASLossOfCommunication_N" 143 "MID_CAN_EPASLossOfCommunication_N" 142 "MID_CAN_EPBLossOfCommunication_N" 141 "MID_CAN_ESPLossOfCommunication_N" 140 "MID_CAN_GTWLossOfCommunication_N" 139 "MID_CAN_SCCMLossOfCommunication_N" 138 "MID_PA_E_USS_08_NO_COM_N" 137 "MID_PA_E_USS_08_OPEN_N" 136 "MID_PA_E_USS_08_RING_TOO_SHORT_N" 135 "MID_PA_E_USS_08_RINGING_TOO_LONG_N" 134 "MID_PA_E_USS_08_SHORT_2_GND_N" 133 "MID_PA_E_USS_08_SHORT_2_USENS_N" 132 "MID_PA_E_USS_08_STATE_COM_VERIFIED_N" 131 "MID_PA_E_USS_08_STATE_OFFSET_N" 130 "MID_PA_E_USS_08_STATE_PROG_N" 129 "MID_PA_E_USS_08_STATE_TYPE_N" 128 "MID_PA_E_USS_09_NO_COM_N" 127 "MID_PA_E_USS_09_OPEN_N" 126 "MID_PA_E_USS_09_RING_TOO_SHORT_N" 125 "MID_PA_E_USS_09_RINGING_TOO_LONG_N" 124 "MID_PA_E_USS_09_SHORT_2_GND_N" 123 "MID_PA_E_USS_09_SHORT_2_USENS_N" 122 "MID_PA_E_USS_09_STATE_COM_VERIFIED_N" 121 "MID_PA_E_USS_09_STATE_OFFSET_N" 120 "MID_PA_E_USS_09_STATE_PROG_N" 119 "MID_PA_E_USS_09_STATE_TYPE_N" 118 "MID_PA_E_USS_10_NO_COM_N" 117 "MID_PA_E_USS_10_OPEN_N" 116 "MID_PA_E_USS_10_RING_TOO_SHORT_N" 115 "MID_PA_E_USS_10_RINGING_TOO_LONG_N" 114 "MID_PA_E_USS_10_SHORT_2_GND_N" 113 "MID_PA_E_USS_10_SHORT_2_USENS_N" 112 "MID_PA_E_USS_10_STATE_COM_VERIFIED_N" 111 "MID_PA_E_USS_10_STATE_OFFSET_N" 110 "MID_PA_E_USS_10_STATE_PROG_N" 109 "MID_PA_E_USS_10_STATE_TYPE_N" 108 "MID_PA_E_USS_11_NO_COM_N" 107 "MID_PA_E_USS_11_OPEN_N" 106 "MID_PA_E_USS_11_RING_TOO_SHORT_N" 105 "MID_PA_E_USS_11_RINGING_TOO_LONG_N" 104 "MID_PA_E_USS_11_SHORT_2_GND_N" 103 "MID_PA_E_USS_11_SHORT_2_USENS_N" 102 "MID_PA_E_USS_11_STATE_COM_VERIFIED_N" 101 "MID_PA_E_USS_11_STATE_OFFSET_N" 100 "MID_PA_E_USS_11_STATE_PROG_N" 99 "MID_PA_E_USS_11_STATE_TYPE_N" 98 "MID_PA_E_USS_12_NO_COM_N" 97 "MID_PA_E_USS_12_OPEN_N" 96 "MID_PA_E_USS_12_RING_TOO_SHORT_N" 95 "MID_PA_E_USS_12_RINGING_TOO_LONG_N" 94 "MID_PA_E_USS_12_SHORT_2_GND_N" 93 "MID_PA_E_USS_12_SHORT_2_USENS_N" 92 "MID_PA_E_USS_12_STATE_COM_VERIFIED_N" 91 "MID_PA_E_USS_12_STATE_OFFSET_N" 90 "MID_PA_E_USS_12_STATE_PROG_N" 89 "MID_PA_E_USS_12_STATE_TYPE_N" 88 "MID_PA_E_USS_13_NO_COM_N" 87 "MID_PA_E_USS_13_OPEN_N" 86 "MID_PA_E_USS_13_RING_TOO_SHORT_N" 85 "MID_PA_E_USS_13_RINGING_TOO_LONG_N" 84 "MID_PA_E_USS_13_SHORT_2_GND_N" 83 "MID_PA_E_USS_13_SHORT_2_USENS_N" 82 "MID_PA_E_USS_13_STATE_COM_VERIFIED_N" 81 "MID_PA_E_USS_13_STATE_OFFSET_N" 80 "MID_PA_E_USS_13_STATE_PROG_N" 79 "MID_PA_E_USS_13_STATE_TYPE_N" 78 "MID_PA_E_SVA_BLOCKED_USS_ML_N" 77 "MID_PA_E_SVA_BLOCKED_USS_MR_N" 76 "MID_PA_E_WHEEL_DIR_FL_INVALID_N" 75 "MID_PA_E_WHEEL_DIR_FR_INVALID_N" 74 "MID_PA_E_WHEEL_DIR_RL_INVALID_N" 73 "MID_PA_E_WHEEL_DIR_RR_INVALID_N" 72 "MID_PA_E_WHEEL_ROTATION_FL_INVALID_N" 71 "MID_PA_E_WHEEL_ROTATION_FR_INVALID_N" 70 "MID_PA_E_WHEEL_ROTATION_RL_INVALID_N" 69 "MID_PA_E_WHEEL_ROTATION_RR_INVALID_N" 68 "MID_PA_E_WICFL_INVALID_N" 67 "MID_PA_E_WICFR_INVALID_N" 66 "MID_PA_E_WICRL_INVALID_N" 65 "MID_PA_E_WICRR_INVALID_N" 64 "MID_PA_E_YAW_RATE_INVALID_N" 63 "MID_PDUR_E_INIT_FAILED_N" 62 "MID_PDUR_E_PDU_INSTANCE_LOST_N" 61 "MID_COMM_E_NET_START_IND_CHANNEL_0_N" 60 "MID_SPI_E_DMA_TRANSFER_N" 59 "MID_SPI_E_RECEIVE_OVERFLOW_N" 58 "MID_SPI_E_TRANSFER_TIMEOUT_N" 57 "MID_PA_E_VEHDYNINTERVENTION_TIMEOUT_N" 56 "MID_TRAILER_HITCH_PRES_INVALID_N" 55 "MID_PA_E_CL15_STATE_INVALID_N" 54 "MID_PA_E_YAW_RATE_SIGN_INVALID_N" 53 "MID_PA_E_ESP_WIC_FRONT_TIMEOUT_N" 52 "MID_PA_E_SEQ_CALL_FAILURE_N" 51 "MID_PA_E_HMI_FUNCACTIVATION_TIMEOUT_N" 50 "MID_PA_E_LOWBEAM_INVALID_N" 49 "MID_PA_E_ENGINESTART_TIMEOUT_N" 48 "MID_ADC_E_VREF_N" 47 "MID_PA_E_ESP_YAW_TIMEOUT_N" 46 "MID_PA_E_TCM_PRG_TIMEOUT_N" 45 "MID_WDG_E_MODE_SWITCH_FAILED_N" 44 "MID_WDG_E_DISABLE_REJECTED_N" 43 "MID_PA_E_ESP_WHEELDIR_TIMEOUT_N" 42 "MID_PA_E_SWCPA_E_INIT_FAILURE_N" 41 "MID_PA_E_DIR_INDICATOR_INVALID_N" 40 "MID_PA_E_ESP_WIC_TIMEOUT_N" 39 "MID_PA_E_EPS_SWA_TIMEOUT_N" 38 "MID_PA_E_INSTRCLUSTER4_TIMEOUT_N" 37 "MID_PA_E_INSTRCLUSTER5_TIMEOUT_N" 36 "MID_PA_E_INSTRCLUSTER3_TIMEOUT_N" 35 "MID_PA_E_INSTRCLUSTER2_TIMEOUT_N" 34 "MID_PA_E_ASIC_WTD_RESET_N" 33 "MID_PA_E_INSTRCLUSTER1_TIMEOUT_N" 32 "MID_PA_E_ASIC_LOW_VOLT_RESET_N" 31 "MID_PA_E_POWERMODE_TIMEOUT_N" 30 "MID_PA_E_ESP_PS_TIMEOUT_N" 29 "MID_PA_E_ESP_WIC_REAR_TIMEOUT_N" 28 "MID_PA_E_TRAILER_ATTACH_INVALID_N" 27 "MID_PA_E_EXTERNAL_EPS_FAILURE_N" 26 "MID_PA_E_PSX_ACTIVATION_INVALID_N" 25 "MID_PA_E_ESP_WHEELVELO_TIMEOUT_N" 24 "MID_PA_E_ESP_LONGACC_TIMEOUT_N" 23 "MID_PA_E_VEH_DYN_INTERVENTION_INVALID_N" 22 "MID_ZPA_E_PS_MODE_INVALID_N" 21 "MID_ZPA_E_EPS_ERROR_INVALID_N" 20 "MID_ZPA_E1_ESP_PSState_INVALID_N" 19 "MID_ZPA_E2_BdaUss01BlindnessDetect_N" 18 "MID_ZPA_E2_BdaUss02BlindnessDetect_N" 17 "MID_ZPA_E2_BdaUss03BlindnessDetect_N" 16 "MID_ZPA_E2_BdaUss10BlindnessDetect_N" 15 "MID_ZPA_E2_BdaUss05BlindnessDetect_N" 14 "MID_ZPA_E2_BdaUss11BlindnessDetect_N" 13 "MID_ZPA_E2_BdaUss07BlindnessDetect_N" 12 "MID_ZPA_E2_BdaUss12BlindnessDetect_N" 11 "MID_ZPA_E2_BdaUss06BlindnessDetect_N" 10 "MID_ZPA_E2_BdaUss08BlindnessDetect_N" 9 "MID_ZPA_E2_BdaUss13BlindnessDetect_N" 8 "MID_ZPA_E2_BdaUss09BlindnessDetect_N" 7 "MID_ZPA_E2_BdaUss04BlindnessDetect_N" 6 "MID_ZPA_E2_BdaUss14BlindnessDetect_N" 5 "MID_FLS_E_READ_FAILED_N" 4 "MID_FLS_E_COMPARE_FAILED_N" 3 "MID_FLS_E_ERASE_FAILED_N" 2 "MID_FLS_E_WRITE_FAILED_N" 1 "MID_NO_FAULT_N" 0 "MID_INVALID" ;
VAL_ 1486 PARK_sw061_ambTemp 255 "UNKNOWN" ;
VAL_ 1486 PARK_sw061_voltage 255 "UNKNOWN" ;
VAL_ 1486 PARK_sw061_subCode 254 "MID_ADC_E_TOUT_N" 253 "MID_ADC_E_INIT_FAILURE_N" 252 "MID_CAN_E_TIMEOUT_N" 251 "MID_CANIF_E_FULL_TX_BUFFER_N" 250 "MID_CANIF_E_INVALID_DLC_N" 249 "MID_CANIF_E_INVALID_TXPDUID_N" 248 "MID_CANIF_E_STOPPED_N" 247 "MID_CANNM_E_CANIF_TRANSMIT_ERROR_N" 246 "MID_CANNM_E_INIT_FAILED_N" 245 "MID_CANNM_E_NETWORK_TIMEOUT_N" 244 "MID_CANSM_E_BUSOFF_NETWORK_N" 243 "MID_CANTP_E_COM_DIAMANT_N" 242 "MID_ECU_E_EEP_DATAFLASH_LAYOUT_N" 241 "MID_ECU_E_RAM_N" 240 "MID_ECU_E_ROM_N" 239 "MID_FEE_E_LAYOUT_FAILED_N" 238 "MID_NVM_E_CONFIG_FAILED_N" 237 "MID_CAN_DASInvalidData_N" 236 "MID_CAN_C_BUSOFF_N" 235 "MID_NVM_E_INTEGRITY_FAILED_N" 234 "MID_NVM_E_REQ_FAILED_N" 233 "MID_PA_E_ASIC_COM_FAILURE_N" 232 "MID_PA_E_ASIC_HW_FAILURE_N" 231 "MID_PA_E_ENGINE_START_INVALID_N" 230 "MID_PA_E_EPS_STATUS_INVALID_N" 229 "MID_PA_E_GEAR_INVALID_N" 228 "MID_PA_E_LONG_ACC_INVALID_N" 227 "MID_PA_E_OUTSIDE_TEMP_INVALID_N" 226 "MID_CAN_EPASInvalidData_N" 225 "MID_PA_E_SPEED_INVALID_N" 224 "MID_PA_E_SVA_BLOCKED_USS_FL_N" 223 "MID_PA_E_SVA_BLOCKED_USS_FR_N" 222 "MID_PA_E_SVA_BLOCKED_USS_RL_N" 221 "MID_PA_E_SVA_BLOCKED_USS_RR_N" 220 "MID_PA_E_SWA_INVALID_N" 219 "MID_PA_E_SWCPA_APT_MONITOR_FAILURE_N" 218 "MID_PA_E_SWCPA_INHIBIT_HSS_PWRLOCK_N" 217 "MID_PA_E_SWCPA_INIT_FAILURE_N" 216 "MID_PA_E_SWCPA_PARFAILURE_N" 215 "MID_CAN_EPBInvalidData_N" 214 "MID_PA_E_UBAT_HIGH_N" 213 "MID_PA_E_UBAT_LOW_N" 212 "MID_PA_E_USENS_OVERTEMPERATURE_N" 211 "MID_PA_E_USENS_OVERVOLTAGE_N" 210 "MID_PA_E_USENS_SHORT_2_GND_N" 209 "MID_PA_E_USENS_SHORT_2_UBAT_N" 208 "MID_PA_E_USENS_UNDERVOLTAGE_N" 207 "MID_PA_E_USS_01_NO_COM_N" 206 "MID_PA_E_USS_01_OPEN_N" 205 "MID_PA_E_USS_01_RING_TOO_SHORT_N" 204 "MID_PA_E_USS_01_RINGING_TOO_LONG_N" 203 "MID_PA_E_USS_01_SHORT_2_GND_N" 202 "MID_PA_E_USS_01_SHORT_2_USENS_N" 201 "MID_PA_E_USS_01_STATE_COM_VERIFIED_N" 200 "MID_PA_E_USS_01_STATE_OFFSET_N" 199 "MID_PA_E_USS_01_STATE_PROG_N" 198 "MID_PA_E_USS_01_STATE_TYPE_N" 197 "MID_PA_E_USS_02_NO_COM_N" 196 "MID_PA_E_USS_02_OPEN_N" 195 "MID_PA_E_USS_02_RING_TOO_SHORT_N" 194 "MID_PA_E_USS_02_RINGING_TOO_LONG_N" 193 "MID_PA_E_USS_02_SHORT_2_GND_N" 192 "MID_PA_E_USS_02_SHORT_2_USENS_N" 191 "MID_PA_E_USS_02_STATE_COM_VERIFIED_N" 190 "MID_PA_E_USS_02_STATE_OFFSET_N" 189 "MID_PA_E_USS_02_STATE_PROG_N" 188 "MID_PA_E_USS_02_STATE_TYPE_N" 187 "MID_PA_E_USS_03_NO_COM_N" 186 "MID_PA_E_USS_03_OPEN_N" 185 "MID_PA_E_USS_03_RING_TOO_SHORT_N" 184 "MID_PA_E_USS_03_RINGING_TOO_LONG_N" 183 "MID_PA_E_USS_03_SHORT_2_GND_N" 182 "MID_PA_E_USS_03_SHORT_2_USENS_N" 181 "MID_PA_E_USS_03_STATE_COM_VERIFIED_N" 180 "MID_PA_E_USS_03_STATE_OFFSET_N" 179 "MID_PA_E_USS_03_STATE_PROG_N" 178 "MID_PA_E_USS_03_STATE_TYPE_N" 177 "MID_PA_E_USS_04_NO_COM_N" 176 "MID_PA_E_USS_04_OPEN_N" 175 "MID_PA_E_USS_04_RING_TOO_SHORT_N" 174 "MID_PA_E_USS_04_RINGING_TOO_LONG_N" 173 "MID_PA_E_USS_04_SHORT_2_GND_N" 172 "MID_PA_E_USS_04_SHORT_2_USENS_N" 171 "MID_PA_E_USS_04_STATE_COM_VERIFIED_N" 170 "MID_PA_E_USS_04_STATE_OFFSET_N" 169 "MID_PA_E_USS_04_STATE_PROG_N" 168 "MID_PA_E_USS_04_STATE_TYPE_N" 167 "MID_PA_E_USS_05_NO_COM_N" 166 "MID_PA_E_USS_05_OPEN_N" 165 "MID_PA_E_USS_05_RING_TOO_SHORT_N" 164 "MID_PA_E_USS_05_RINGING_TOO_LONG_N" 163 "MID_PA_E_USS_05_SHORT_2_GND_N" 162 "MID_PA_E_USS_05_SHORT_2_USENS_N" 161 "MID_PA_E_USS_05_STATE_COM_VERIFIED_N" 160 "MID_PA_E_USS_05_STATE_OFFSET_N" 159 "MID_PA_E_USS_05_STATE_PROG_N" 158 "MID_PA_E_USS_05_STATE_TYPE_N" 157 "MID_PA_E_USS_06_NO_COM_N" 156 "MID_PA_E_USS_06_OPEN_N" 155 "MID_PA_E_USS_06_RING_TOO_SHORT_N" 154 "MID_PA_E_USS_06_RINGING_TOO_LONG_N" 153 "MID_PA_E_USS_06_SHORT_2_GND_N" 152 "MID_PA_E_USS_06_SHORT_2_USENS_N" 151 "MID_PA_E_USS_06_STATE_COM_VERIFIED_N" 150 "MID_PA_E_USS_06_STATE_OFFSET_N" 149 "MID_PA_E_USS_06_STATE_PROG_N" 148 "MID_PA_E_USS_06_STATE_TYPE_N" 147 "MID_CAN_ESPInvalidData_N" 146 "MID_CAN_GTWInvalidData_N" 145 "MID_CAN_SCCMInvalidData_N" 144 "MID_CAN_DASLossOfCommunication_N" 143 "MID_CAN_EPASLossOfCommunication_N" 142 "MID_CAN_EPBLossOfCommunication_N" 141 "MID_CAN_ESPLossOfCommunication_N" 140 "MID_CAN_GTWLossOfCommunication_N" 139 "MID_CAN_SCCMLossOfCommunication_N" 138 "MID_PA_E_USS_08_NO_COM_N" 137 "MID_PA_E_USS_08_OPEN_N" 136 "MID_PA_E_USS_08_RING_TOO_SHORT_N" 135 "MID_PA_E_USS_08_RINGING_TOO_LONG_N" 134 "MID_PA_E_USS_08_SHORT_2_GND_N" 133 "MID_PA_E_USS_08_SHORT_2_USENS_N" 132 "MID_PA_E_USS_08_STATE_COM_VERIFIED_N" 131 "MID_PA_E_USS_08_STATE_OFFSET_N" 130 "MID_PA_E_USS_08_STATE_PROG_N" 129 "MID_PA_E_USS_08_STATE_TYPE_N" 128 "MID_PA_E_USS_09_NO_COM_N" 127 "MID_PA_E_USS_09_OPEN_N" 126 "MID_PA_E_USS_09_RING_TOO_SHORT_N" 125 "MID_PA_E_USS_09_RINGING_TOO_LONG_N" 124 "MID_PA_E_USS_09_SHORT_2_GND_N" 123 "MID_PA_E_USS_09_SHORT_2_USENS_N" 122 "MID_PA_E_USS_09_STATE_COM_VERIFIED_N" 121 "MID_PA_E_USS_09_STATE_OFFSET_N" 120 "MID_PA_E_USS_09_STATE_PROG_N" 119 "MID_PA_E_USS_09_STATE_TYPE_N" 118 "MID_PA_E_USS_10_NO_COM_N" 117 "MID_PA_E_USS_10_OPEN_N" 116 "MID_PA_E_USS_10_RING_TOO_SHORT_N" 115 "MID_PA_E_USS_10_RINGING_TOO_LONG_N" 114 "MID_PA_E_USS_10_SHORT_2_GND_N" 113 "MID_PA_E_USS_10_SHORT_2_USENS_N" 112 "MID_PA_E_USS_10_STATE_COM_VERIFIED_N" 111 "MID_PA_E_USS_10_STATE_OFFSET_N" 110 "MID_PA_E_USS_10_STATE_PROG_N" 109 "MID_PA_E_USS_10_STATE_TYPE_N" 108 "MID_PA_E_USS_11_NO_COM_N" 107 "MID_PA_E_USS_11_OPEN_N" 106 "MID_PA_E_USS_11_RING_TOO_SHORT_N" 105 "MID_PA_E_USS_11_RINGING_TOO_LONG_N" 104 "MID_PA_E_USS_11_SHORT_2_GND_N" 103 "MID_PA_E_USS_11_SHORT_2_USENS_N" 102 "MID_PA_E_USS_11_STATE_COM_VERIFIED_N" 101 "MID_PA_E_USS_11_STATE_OFFSET_N" 100 "MID_PA_E_USS_11_STATE_PROG_N" 99 "MID_PA_E_USS_11_STATE_TYPE_N" 98 "MID_PA_E_USS_12_NO_COM_N" 97 "MID_PA_E_USS_12_OPEN_N" 96 "MID_PA_E_USS_12_RING_TOO_SHORT_N" 95 "MID_PA_E_USS_12_RINGING_TOO_LONG_N" 94 "MID_PA_E_USS_12_SHORT_2_GND_N" 93 "MID_PA_E_USS_12_SHORT_2_USENS_N" 92 "MID_PA_E_USS_12_STATE_COM_VERIFIED_N" 91 "MID_PA_E_USS_12_STATE_OFFSET_N" 90 "MID_PA_E_USS_12_STATE_PROG_N" 89 "MID_PA_E_USS_12_STATE_TYPE_N" 88 "MID_PA_E_USS_13_NO_COM_N" 87 "MID_PA_E_USS_13_OPEN_N" 86 "MID_PA_E_USS_13_RING_TOO_SHORT_N" 85 "MID_PA_E_USS_13_RINGING_TOO_LONG_N" 84 "MID_PA_E_USS_13_SHORT_2_GND_N" 83 "MID_PA_E_USS_13_SHORT_2_USENS_N" 82 "MID_PA_E_USS_13_STATE_COM_VERIFIED_N" 81 "MID_PA_E_USS_13_STATE_OFFSET_N" 80 "MID_PA_E_USS_13_STATE_PROG_N" 79 "MID_PA_E_USS_13_STATE_TYPE_N" 78 "MID_PA_E_SVA_BLOCKED_USS_ML_N" 77 "MID_PA_E_SVA_BLOCKED_USS_MR_N" 76 "MID_PA_E_WHEEL_DIR_FL_INVALID_N" 75 "MID_PA_E_WHEEL_DIR_FR_INVALID_N" 74 "MID_PA_E_WHEEL_DIR_RL_INVALID_N" 73 "MID_PA_E_WHEEL_DIR_RR_INVALID_N" 72 "MID_PA_E_WHEEL_ROTATION_FL_INVALID_N" 71 "MID_PA_E_WHEEL_ROTATION_FR_INVALID_N" 70 "MID_PA_E_WHEEL_ROTATION_RL_INVALID_N" 69 "MID_PA_E_WHEEL_ROTATION_RR_INVALID_N" 68 "MID_PA_E_WICFL_INVALID_N" 67 "MID_PA_E_WICFR_INVALID_N" 66 "MID_PA_E_WICRL_INVALID_N" 65 "MID_PA_E_WICRR_INVALID_N" 64 "MID_PA_E_YAW_RATE_INVALID_N" 63 "MID_PDUR_E_INIT_FAILED_N" 62 "MID_PDUR_E_PDU_INSTANCE_LOST_N" 61 "MID_COMM_E_NET_START_IND_CHANNEL_0_N" 60 "MID_SPI_E_DMA_TRANSFER_N" 59 "MID_SPI_E_RECEIVE_OVERFLOW_N" 58 "MID_SPI_E_TRANSFER_TIMEOUT_N" 57 "MID_PA_E_VEHDYNINTERVENTION_TIMEOUT_N" 56 "MID_TRAILER_HITCH_PRES_INVALID_N" 55 "MID_PA_E_CL15_STATE_INVALID_N" 54 "MID_PA_E_YAW_RATE_SIGN_INVALID_N" 53 "MID_PA_E_ESP_WIC_FRONT_TIMEOUT_N" 52 "MID_PA_E_SEQ_CALL_FAILURE_N" 51 "MID_PA_E_HMI_FUNCACTIVATION_TIMEOUT_N" 50 "MID_PA_E_LOWBEAM_INVALID_N" 49 "MID_PA_E_ENGINESTART_TIMEOUT_N" 48 "MID_ADC_E_VREF_N" 47 "MID_PA_E_ESP_YAW_TIMEOUT_N" 46 "MID_PA_E_TCM_PRG_TIMEOUT_N" 45 "MID_WDG_E_MODE_SWITCH_FAILED_N" 44 "MID_WDG_E_DISABLE_REJECTED_N" 43 "MID_PA_E_ESP_WHEELDIR_TIMEOUT_N" 42 "MID_PA_E_SWCPA_E_INIT_FAILURE_N" 41 "MID_PA_E_DIR_INDICATOR_INVALID_N" 40 "MID_PA_E_ESP_WIC_TIMEOUT_N" 39 "MID_PA_E_EPS_SWA_TIMEOUT_N" 38 "MID_PA_E_INSTRCLUSTER4_TIMEOUT_N" 37 "MID_PA_E_INSTRCLUSTER5_TIMEOUT_N" 36 "MID_PA_E_INSTRCLUSTER3_TIMEOUT_N" 35 "MID_PA_E_INSTRCLUSTER2_TIMEOUT_N" 34 "MID_PA_E_ASIC_WTD_RESET_N" 33 "MID_PA_E_INSTRCLUSTER1_TIMEOUT_N" 32 "MID_PA_E_ASIC_LOW_VOLT_RESET_N" 31 "MID_PA_E_POWERMODE_TIMEOUT_N" 30 "MID_PA_E_ESP_PS_TIMEOUT_N" 29 "MID_PA_E_ESP_WIC_REAR_TIMEOUT_N" 28 "MID_PA_E_TRAILER_ATTACH_INVALID_N" 27 "MID_PA_E_EXTERNAL_EPS_FAILURE_N" 26 "MID_PA_E_PSX_ACTIVATION_INVALID_N" 25 "MID_PA_E_ESP_WHEELVELO_TIMEOUT_N" 24 "MID_PA_E_ESP_LONGACC_TIMEOUT_N" 23 "MID_PA_E_VEH_DYN_INTERVENTION_INVALID_N" 22 "MID_ZPA_E_PS_MODE_INVALID_N" 21 "MID_ZPA_E_EPS_ERROR_INVALID_N" 20 "MID_ZPA_E1_ESP_PSState_INVALID_N" 19 "MID_ZPA_E2_BdaUss01BlindnessDetect_N" 18 "MID_ZPA_E2_BdaUss02BlindnessDetect_N" 17 "MID_ZPA_E2_BdaUss03BlindnessDetect_N" 16 "MID_ZPA_E2_BdaUss10BlindnessDetect_N" 15 "MID_ZPA_E2_BdaUss05BlindnessDetect_N" 14 "MID_ZPA_E2_BdaUss11BlindnessDetect_N" 13 "MID_ZPA_E2_BdaUss07BlindnessDetect_N" 12 "MID_ZPA_E2_BdaUss12BlindnessDetect_N" 11 "MID_ZPA_E2_BdaUss06BlindnessDetect_N" 10 "MID_ZPA_E2_BdaUss08BlindnessDetect_N" 9 "MID_ZPA_E2_BdaUss13BlindnessDetect_N" 8 "MID_ZPA_E2_BdaUss09BlindnessDetect_N" 7 "MID_ZPA_E2_BdaUss04BlindnessDetect_N" 6 "MID_ZPA_E2_BdaUss14BlindnessDetect_N" 5 "MID_FLS_E_READ_FAILED_N" 4 "MID_FLS_E_COMPARE_FAILED_N" 3 "MID_FLS_E_ERASE_FAILED_N" 2 "MID_FLS_E_WRITE_FAILED_N" 1 "MID_NO_FAULT_N" 0 "MID_INVALID" ;
VAL_ 1486 PARK_sw062_ambTemp 255 "UNKNOWN" ;
VAL_ 1486 PARK_sw062_voltage 255 "UNKNOWN" ;
VAL_ 1486 PARK_sw062_subCode 254 "MID_ADC_E_TOUT_N" 253 "MID_ADC_E_INIT_FAILURE_N" 252 "MID_CAN_E_TIMEOUT_N" 251 "MID_CANIF_E_FULL_TX_BUFFER_N" 250 "MID_CANIF_E_INVALID_DLC_N" 249 "MID_CANIF_E_INVALID_TXPDUID_N" 248 "MID_CANIF_E_STOPPED_N" 247 "MID_CANNM_E_CANIF_TRANSMIT_ERROR_N" 246 "MID_CANNM_E_INIT_FAILED_N" 245 "MID_CANNM_E_NETWORK_TIMEOUT_N" 244 "MID_CANSM_E_BUSOFF_NETWORK_N" 243 "MID_CANTP_E_COM_DIAMANT_N" 242 "MID_ECU_E_EEP_DATAFLASH_LAYOUT_N" 241 "MID_ECU_E_RAM_N" 240 "MID_ECU_E_ROM_N" 239 "MID_FEE_E_LAYOUT_FAILED_N" 238 "MID_NVM_E_CONFIG_FAILED_N" 237 "MID_CAN_DASInvalidData_N" 236 "MID_CAN_C_BUSOFF_N" 235 "MID_NVM_E_INTEGRITY_FAILED_N" 234 "MID_NVM_E_REQ_FAILED_N" 233 "MID_PA_E_ASIC_COM_FAILURE_N" 232 "MID_PA_E_ASIC_HW_FAILURE_N" 231 "MID_PA_E_ENGINE_START_INVALID_N" 230 "MID_PA_E_EPS_STATUS_INVALID_N" 229 "MID_PA_E_GEAR_INVALID_N" 228 "MID_PA_E_LONG_ACC_INVALID_N" 227 "MID_PA_E_OUTSIDE_TEMP_INVALID_N" 226 "MID_CAN_EPASInvalidData_N" 225 "MID_PA_E_SPEED_INVALID_N" 224 "MID_PA_E_SVA_BLOCKED_USS_FL_N" 223 "MID_PA_E_SVA_BLOCKED_USS_FR_N" 222 "MID_PA_E_SVA_BLOCKED_USS_RL_N" 221 "MID_PA_E_SVA_BLOCKED_USS_RR_N" 220 "MID_PA_E_SWA_INVALID_N" 219 "MID_PA_E_SWCPA_APT_MONITOR_FAILURE_N" 218 "MID_PA_E_SWCPA_INHIBIT_HSS_PWRLOCK_N" 217 "MID_PA_E_SWCPA_INIT_FAILURE_N" 216 "MID_PA_E_SWCPA_PARFAILURE_N" 215 "MID_CAN_EPBInvalidData_N" 214 "MID_PA_E_UBAT_HIGH_N" 213 "MID_PA_E_UBAT_LOW_N" 212 "MID_PA_E_USENS_OVERTEMPERATURE_N" 211 "MID_PA_E_USENS_OVERVOLTAGE_N" 210 "MID_PA_E_USENS_SHORT_2_GND_N" 209 "MID_PA_E_USENS_SHORT_2_UBAT_N" 208 "MID_PA_E_USENS_UNDERVOLTAGE_N" 207 "MID_PA_E_USS_01_NO_COM_N" 206 "MID_PA_E_USS_01_OPEN_N" 205 "MID_PA_E_USS_01_RING_TOO_SHORT_N" 204 "MID_PA_E_USS_01_RINGING_TOO_LONG_N" 203 "MID_PA_E_USS_01_SHORT_2_GND_N" 202 "MID_PA_E_USS_01_SHORT_2_USENS_N" 201 "MID_PA_E_USS_01_STATE_COM_VERIFIED_N" 200 "MID_PA_E_USS_01_STATE_OFFSET_N" 199 "MID_PA_E_USS_01_STATE_PROG_N" 198 "MID_PA_E_USS_01_STATE_TYPE_N" 197 "MID_PA_E_USS_02_NO_COM_N" 196 "MID_PA_E_USS_02_OPEN_N" 195 "MID_PA_E_USS_02_RING_TOO_SHORT_N" 194 "MID_PA_E_USS_02_RINGING_TOO_LONG_N" 193 "MID_PA_E_USS_02_SHORT_2_GND_N" 192 "MID_PA_E_USS_02_SHORT_2_USENS_N" 191 "MID_PA_E_USS_02_STATE_COM_VERIFIED_N" 190 "MID_PA_E_USS_02_STATE_OFFSET_N" 189 "MID_PA_E_USS_02_STATE_PROG_N" 188 "MID_PA_E_USS_02_STATE_TYPE_N" 187 "MID_PA_E_USS_03_NO_COM_N" 186 "MID_PA_E_USS_03_OPEN_N" 185 "MID_PA_E_USS_03_RING_TOO_SHORT_N" 184 "MID_PA_E_USS_03_RINGING_TOO_LONG_N" 183 "MID_PA_E_USS_03_SHORT_2_GND_N" 182 "MID_PA_E_USS_03_SHORT_2_USENS_N" 181 "MID_PA_E_USS_03_STATE_COM_VERIFIED_N" 180 "MID_PA_E_USS_03_STATE_OFFSET_N" 179 "MID_PA_E_USS_03_STATE_PROG_N" 178 "MID_PA_E_USS_03_STATE_TYPE_N" 177 "MID_PA_E_USS_04_NO_COM_N" 176 "MID_PA_E_USS_04_OPEN_N" 175 "MID_PA_E_USS_04_RING_TOO_SHORT_N" 174 "MID_PA_E_USS_04_RINGING_TOO_LONG_N" 173 "MID_PA_E_USS_04_SHORT_2_GND_N" 172 "MID_PA_E_USS_04_SHORT_2_USENS_N" 171 "MID_PA_E_USS_04_STATE_COM_VERIFIED_N" 170 "MID_PA_E_USS_04_STATE_OFFSET_N" 169 "MID_PA_E_USS_04_STATE_PROG_N" 168 "MID_PA_E_USS_04_STATE_TYPE_N" 167 "MID_PA_E_USS_05_NO_COM_N" 166 "MID_PA_E_USS_05_OPEN_N" 165 "MID_PA_E_USS_05_RING_TOO_SHORT_N" 164 "MID_PA_E_USS_05_RINGING_TOO_LONG_N" 163 "MID_PA_E_USS_05_SHORT_2_GND_N" 162 "MID_PA_E_USS_05_SHORT_2_USENS_N" 161 "MID_PA_E_USS_05_STATE_COM_VERIFIED_N" 160 "MID_PA_E_USS_05_STATE_OFFSET_N" 159 "MID_PA_E_USS_05_STATE_PROG_N" 158 "MID_PA_E_USS_05_STATE_TYPE_N" 157 "MID_PA_E_USS_06_NO_COM_N" 156 "MID_PA_E_USS_06_OPEN_N" 155 "MID_PA_E_USS_06_RING_TOO_SHORT_N" 154 "MID_PA_E_USS_06_RINGING_TOO_LONG_N" 153 "MID_PA_E_USS_06_SHORT_2_GND_N" 152 "MID_PA_E_USS_06_SHORT_2_USENS_N" 151 "MID_PA_E_USS_06_STATE_COM_VERIFIED_N" 150 "MID_PA_E_USS_06_STATE_OFFSET_N" 149 "MID_PA_E_USS_06_STATE_PROG_N" 148 "MID_PA_E_USS_06_STATE_TYPE_N" 147 "MID_CAN_ESPInvalidData_N" 146 "MID_CAN_GTWInvalidData_N" 145 "MID_CAN_SCCMInvalidData_N" 144 "MID_CAN_DASLossOfCommunication_N" 143 "MID_CAN_EPASLossOfCommunication_N" 142 "MID_CAN_EPBLossOfCommunication_N" 141 "MID_CAN_ESPLossOfCommunication_N" 140 "MID_CAN_GTWLossOfCommunication_N" 139 "MID_CAN_SCCMLossOfCommunication_N" 138 "MID_PA_E_USS_08_NO_COM_N" 137 "MID_PA_E_USS_08_OPEN_N" 136 "MID_PA_E_USS_08_RING_TOO_SHORT_N" 135 "MID_PA_E_USS_08_RINGING_TOO_LONG_N" 134 "MID_PA_E_USS_08_SHORT_2_GND_N" 133 "MID_PA_E_USS_08_SHORT_2_USENS_N" 132 "MID_PA_E_USS_08_STATE_COM_VERIFIED_N" 131 "MID_PA_E_USS_08_STATE_OFFSET_N" 130 "MID_PA_E_USS_08_STATE_PROG_N" 129 "MID_PA_E_USS_08_STATE_TYPE_N" 128 "MID_PA_E_USS_09_NO_COM_N" 127 "MID_PA_E_USS_09_OPEN_N" 126 "MID_PA_E_USS_09_RING_TOO_SHORT_N" 125 "MID_PA_E_USS_09_RINGING_TOO_LONG_N" 124 "MID_PA_E_USS_09_SHORT_2_GND_N" 123 "MID_PA_E_USS_09_SHORT_2_USENS_N" 122 "MID_PA_E_USS_09_STATE_COM_VERIFIED_N" 121 "MID_PA_E_USS_09_STATE_OFFSET_N" 120 "MID_PA_E_USS_09_STATE_PROG_N" 119 "MID_PA_E_USS_09_STATE_TYPE_N" 118 "MID_PA_E_USS_10_NO_COM_N" 117 "MID_PA_E_USS_10_OPEN_N" 116 "MID_PA_E_USS_10_RING_TOO_SHORT_N" 115 "MID_PA_E_USS_10_RINGING_TOO_LONG_N" 114 "MID_PA_E_USS_10_SHORT_2_GND_N" 113 "MID_PA_E_USS_10_SHORT_2_USENS_N" 112 "MID_PA_E_USS_10_STATE_COM_VERIFIED_N" 111 "MID_PA_E_USS_10_STATE_OFFSET_N" 110 "MID_PA_E_USS_10_STATE_PROG_N" 109 "MID_PA_E_USS_10_STATE_TYPE_N" 108 "MID_PA_E_USS_11_NO_COM_N" 107 "MID_PA_E_USS_11_OPEN_N" 106 "MID_PA_E_USS_11_RING_TOO_SHORT_N" 105 "MID_PA_E_USS_11_RINGING_TOO_LONG_N" 104 "MID_PA_E_USS_11_SHORT_2_GND_N" 103 "MID_PA_E_USS_11_SHORT_2_USENS_N" 102 "MID_PA_E_USS_11_STATE_COM_VERIFIED_N" 101 "MID_PA_E_USS_11_STATE_OFFSET_N" 100 "MID_PA_E_USS_11_STATE_PROG_N" 99 "MID_PA_E_USS_11_STATE_TYPE_N" 98 "MID_PA_E_USS_12_NO_COM_N" 97 "MID_PA_E_USS_12_OPEN_N" 96 "MID_PA_E_USS_12_RING_TOO_SHORT_N" 95 "MID_PA_E_USS_12_RINGING_TOO_LONG_N" 94 "MID_PA_E_USS_12_SHORT_2_GND_N" 93 "MID_PA_E_USS_12_SHORT_2_USENS_N" 92 "MID_PA_E_USS_12_STATE_COM_VERIFIED_N" 91 "MID_PA_E_USS_12_STATE_OFFSET_N" 90 "MID_PA_E_USS_12_STATE_PROG_N" 89 "MID_PA_E_USS_12_STATE_TYPE_N" 88 "MID_PA_E_USS_13_NO_COM_N" 87 "MID_PA_E_USS_13_OPEN_N" 86 "MID_PA_E_USS_13_RING_TOO_SHORT_N" 85 "MID_PA_E_USS_13_RINGING_TOO_LONG_N" 84 "MID_PA_E_USS_13_SHORT_2_GND_N" 83 "MID_PA_E_USS_13_SHORT_2_USENS_N" 82 "MID_PA_E_USS_13_STATE_COM_VERIFIED_N" 81 "MID_PA_E_USS_13_STATE_OFFSET_N" 80 "MID_PA_E_USS_13_STATE_PROG_N" 79 "MID_PA_E_USS_13_STATE_TYPE_N" 78 "MID_PA_E_SVA_BLOCKED_USS_ML_N" 77 "MID_PA_E_SVA_BLOCKED_USS_MR_N" 76 "MID_PA_E_WHEEL_DIR_FL_INVALID_N" 75 "MID_PA_E_WHEEL_DIR_FR_INVALID_N" 74 "MID_PA_E_WHEEL_DIR_RL_INVALID_N" 73 "MID_PA_E_WHEEL_DIR_RR_INVALID_N" 72 "MID_PA_E_WHEEL_ROTATION_FL_INVALID_N" 71 "MID_PA_E_WHEEL_ROTATION_FR_INVALID_N" 70 "MID_PA_E_WHEEL_ROTATION_RL_INVALID_N" 69 "MID_PA_E_WHEEL_ROTATION_RR_INVALID_N" 68 "MID_PA_E_WICFL_INVALID_N" 67 "MID_PA_E_WICFR_INVALID_N" 66 "MID_PA_E_WICRL_INVALID_N" 65 "MID_PA_E_WICRR_INVALID_N" 64 "MID_PA_E_YAW_RATE_INVALID_N" 63 "MID_PDUR_E_INIT_FAILED_N" 62 "MID_PDUR_E_PDU_INSTANCE_LOST_N" 61 "MID_COMM_E_NET_START_IND_CHANNEL_0_N" 60 "MID_SPI_E_DMA_TRANSFER_N" 59 "MID_SPI_E_RECEIVE_OVERFLOW_N" 58 "MID_SPI_E_TRANSFER_TIMEOUT_N" 57 "MID_PA_E_VEHDYNINTERVENTION_TIMEOUT_N" 56 "MID_TRAILER_HITCH_PRES_INVALID_N" 55 "MID_PA_E_CL15_STATE_INVALID_N" 54 "MID_PA_E_YAW_RATE_SIGN_INVALID_N" 53 "MID_PA_E_ESP_WIC_FRONT_TIMEOUT_N" 52 "MID_PA_E_SEQ_CALL_FAILURE_N" 51 "MID_PA_E_HMI_FUNCACTIVATION_TIMEOUT_N" 50 "MID_PA_E_LOWBEAM_INVALID_N" 49 "MID_PA_E_ENGINESTART_TIMEOUT_N" 48 "MID_ADC_E_VREF_N" 47 "MID_PA_E_ESP_YAW_TIMEOUT_N" 46 "MID_PA_E_TCM_PRG_TIMEOUT_N" 45 "MID_WDG_E_MODE_SWITCH_FAILED_N" 44 "MID_WDG_E_DISABLE_REJECTED_N" 43 "MID_PA_E_ESP_WHEELDIR_TIMEOUT_N" 42 "MID_PA_E_SWCPA_E_INIT_FAILURE_N" 41 "MID_PA_E_DIR_INDICATOR_INVALID_N" 40 "MID_PA_E_ESP_WIC_TIMEOUT_N" 39 "MID_PA_E_EPS_SWA_TIMEOUT_N" 38 "MID_PA_E_INSTRCLUSTER4_TIMEOUT_N" 37 "MID_PA_E_INSTRCLUSTER5_TIMEOUT_N" 36 "MID_PA_E_INSTRCLUSTER3_TIMEOUT_N" 35 "MID_PA_E_INSTRCLUSTER2_TIMEOUT_N" 34 "MID_PA_E_ASIC_WTD_RESET_N" 33 "MID_PA_E_INSTRCLUSTER1_TIMEOUT_N" 32 "MID_PA_E_ASIC_LOW_VOLT_RESET_N" 31 "MID_PA_E_POWERMODE_TIMEOUT_N" 30 "MID_PA_E_ESP_PS_TIMEOUT_N" 29 "MID_PA_E_ESP_WIC_REAR_TIMEOUT_N" 28 "MID_PA_E_TRAILER_ATTACH_INVALID_N" 27 "MID_PA_E_EXTERNAL_EPS_FAILURE_N" 26 "MID_PA_E_PSX_ACTIVATION_INVALID_N" 25 "MID_PA_E_ESP_WHEELVELO_TIMEOUT_N" 24 "MID_PA_E_ESP_LONGACC_TIMEOUT_N" 23 "MID_PA_E_VEH_DYN_INTERVENTION_INVALID_N" 22 "MID_ZPA_E_PS_MODE_INVALID_N" 21 "MID_ZPA_E_EPS_ERROR_INVALID_N" 20 "MID_ZPA_E1_ESP_PSState_INVALID_N" 19 "MID_ZPA_E2_BdaUss01BlindnessDetect_N" 18 "MID_ZPA_E2_BdaUss02BlindnessDetect_N" 17 "MID_ZPA_E2_BdaUss03BlindnessDetect_N" 16 "MID_ZPA_E2_BdaUss10BlindnessDetect_N" 15 "MID_ZPA_E2_BdaUss05BlindnessDetect_N" 14 "MID_ZPA_E2_BdaUss11BlindnessDetect_N" 13 "MID_ZPA_E2_BdaUss07BlindnessDetect_N" 12 "MID_ZPA_E2_BdaUss12BlindnessDetect_N" 11 "MID_ZPA_E2_BdaUss06BlindnessDetect_N" 10 "MID_ZPA_E2_BdaUss08BlindnessDetect_N" 9 "MID_ZPA_E2_BdaUss13BlindnessDetect_N" 8 "MID_ZPA_E2_BdaUss09BlindnessDetect_N" 7 "MID_ZPA_E2_BdaUss04BlindnessDetect_N" 6 "MID_ZPA_E2_BdaUss14BlindnessDetect_N" 5 "MID_FLS_E_READ_FAILED_N" 4 "MID_FLS_E_COMPARE_FAILED_N" 3 "MID_FLS_E_ERASE_FAILED_N" 2 "MID_FLS_E_WRITE_FAILED_N" 1 "MID_NO_FAULT_N" 0 "MID_INVALID" ;
VAL_ 1486 PARK_sw063_ambTemp 255 "UNKNOWN" ;
VAL_ 1486 PARK_sw063_voltage 255 "UNKNOWN" ;
VAL_ 1486 PARK_sw063_subCode 254 "MID_ADC_E_TOUT_N" 253 "MID_ADC_E_INIT_FAILURE_N" 252 "MID_CAN_E_TIMEOUT_N" 251 "MID_CANIF_E_FULL_TX_BUFFER_N" 250 "MID_CANIF_E_INVALID_DLC_N" 249 "MID_CANIF_E_INVALID_TXPDUID_N" 248 "MID_CANIF_E_STOPPED_N" 247 "MID_CANNM_E_CANIF_TRANSMIT_ERROR_N" 246 "MID_CANNM_E_INIT_FAILED_N" 245 "MID_CANNM_E_NETWORK_TIMEOUT_N" 244 "MID_CANSM_E_BUSOFF_NETWORK_N" 243 "MID_CANTP_E_COM_DIAMANT_N" 242 "MID_ECU_E_EEP_DATAFLASH_LAYOUT_N" 241 "MID_ECU_E_RAM_N" 240 "MID_ECU_E_ROM_N" 239 "MID_FEE_E_LAYOUT_FAILED_N" 238 "MID_NVM_E_CONFIG_FAILED_N" 237 "MID_CAN_DASInvalidData_N" 236 "MID_CAN_C_BUSOFF_N" 235 "MID_NVM_E_INTEGRITY_FAILED_N" 234 "MID_NVM_E_REQ_FAILED_N" 233 "MID_PA_E_ASIC_COM_FAILURE_N" 232 "MID_PA_E_ASIC_HW_FAILURE_N" 231 "MID_PA_E_ENGINE_START_INVALID_N" 230 "MID_PA_E_EPS_STATUS_INVALID_N" 229 "MID_PA_E_GEAR_INVALID_N" 228 "MID_PA_E_LONG_ACC_INVALID_N" 227 "MID_PA_E_OUTSIDE_TEMP_INVALID_N" 226 "MID_CAN_EPASInvalidData_N" 225 "MID_PA_E_SPEED_INVALID_N" 224 "MID_PA_E_SVA_BLOCKED_USS_FL_N" 223 "MID_PA_E_SVA_BLOCKED_USS_FR_N" 222 "MID_PA_E_SVA_BLOCKED_USS_RL_N" 221 "MID_PA_E_SVA_BLOCKED_USS_RR_N" 220 "MID_PA_E_SWA_INVALID_N" 219 "MID_PA_E_SWCPA_APT_MONITOR_FAILURE_N" 218 "MID_PA_E_SWCPA_INHIBIT_HSS_PWRLOCK_N" 217 "MID_PA_E_SWCPA_INIT_FAILURE_N" 216 "MID_PA_E_SWCPA_PARFAILURE_N" 215 "MID_CAN_EPBInvalidData_N" 214 "MID_PA_E_UBAT_HIGH_N" 213 "MID_PA_E_UBAT_LOW_N" 212 "MID_PA_E_USENS_OVERTEMPERATURE_N" 211 "MID_PA_E_USENS_OVERVOLTAGE_N" 210 "MID_PA_E_USENS_SHORT_2_GND_N" 209 "MID_PA_E_USENS_SHORT_2_UBAT_N" 208 "MID_PA_E_USENS_UNDERVOLTAGE_N" 207 "MID_PA_E_USS_01_NO_COM_N" 206 "MID_PA_E_USS_01_OPEN_N" 205 "MID_PA_E_USS_01_RING_TOO_SHORT_N" 204 "MID_PA_E_USS_01_RINGING_TOO_LONG_N" 203 "MID_PA_E_USS_01_SHORT_2_GND_N" 202 "MID_PA_E_USS_01_SHORT_2_USENS_N" 201 "MID_PA_E_USS_01_STATE_COM_VERIFIED_N" 200 "MID_PA_E_USS_01_STATE_OFFSET_N" 199 "MID_PA_E_USS_01_STATE_PROG_N" 198 "MID_PA_E_USS_01_STATE_TYPE_N" 197 "MID_PA_E_USS_02_NO_COM_N" 196 "MID_PA_E_USS_02_OPEN_N" 195 "MID_PA_E_USS_02_RING_TOO_SHORT_N" 194 "MID_PA_E_USS_02_RINGING_TOO_LONG_N" 193 "MID_PA_E_USS_02_SHORT_2_GND_N" 192 "MID_PA_E_USS_02_SHORT_2_USENS_N" 191 "MID_PA_E_USS_02_STATE_COM_VERIFIED_N" 190 "MID_PA_E_USS_02_STATE_OFFSET_N" 189 "MID_PA_E_USS_02_STATE_PROG_N" 188 "MID_PA_E_USS_02_STATE_TYPE_N" 187 "MID_PA_E_USS_03_NO_COM_N" 186 "MID_PA_E_USS_03_OPEN_N" 185 "MID_PA_E_USS_03_RING_TOO_SHORT_N" 184 "MID_PA_E_USS_03_RINGING_TOO_LONG_N" 183 "MID_PA_E_USS_03_SHORT_2_GND_N" 182 "MID_PA_E_USS_03_SHORT_2_USENS_N" 181 "MID_PA_E_USS_03_STATE_COM_VERIFIED_N" 180 "MID_PA_E_USS_03_STATE_OFFSET_N" 179 "MID_PA_E_USS_03_STATE_PROG_N" 178 "MID_PA_E_USS_03_STATE_TYPE_N" 177 "MID_PA_E_USS_04_NO_COM_N" 176 "MID_PA_E_USS_04_OPEN_N" 175 "MID_PA_E_USS_04_RING_TOO_SHORT_N" 174 "MID_PA_E_USS_04_RINGING_TOO_LONG_N" 173 "MID_PA_E_USS_04_SHORT_2_GND_N" 172 "MID_PA_E_USS_04_SHORT_2_USENS_N" 171 "MID_PA_E_USS_04_STATE_COM_VERIFIED_N" 170 "MID_PA_E_USS_04_STATE_OFFSET_N" 169 "MID_PA_E_USS_04_STATE_PROG_N" 168 "MID_PA_E_USS_04_STATE_TYPE_N" 167 "MID_PA_E_USS_05_NO_COM_N" 166 "MID_PA_E_USS_05_OPEN_N" 165 "MID_PA_E_USS_05_RING_TOO_SHORT_N" 164 "MID_PA_E_USS_05_RINGING_TOO_LONG_N" 163 "MID_PA_E_USS_05_SHORT_2_GND_N" 162 "MID_PA_E_USS_05_SHORT_2_USENS_N" 161 "MID_PA_E_USS_05_STATE_COM_VERIFIED_N" 160 "MID_PA_E_USS_05_STATE_OFFSET_N" 159 "MID_PA_E_USS_05_STATE_PROG_N" 158 "MID_PA_E_USS_05_STATE_TYPE_N" 157 "MID_PA_E_USS_06_NO_COM_N" 156 "MID_PA_E_USS_06_OPEN_N" 155 "MID_PA_E_USS_06_RING_TOO_SHORT_N" 154 "MID_PA_E_USS_06_RINGING_TOO_LONG_N" 153 "MID_PA_E_USS_06_SHORT_2_GND_N" 152 "MID_PA_E_USS_06_SHORT_2_USENS_N" 151 "MID_PA_E_USS_06_STATE_COM_VERIFIED_N" 150 "MID_PA_E_USS_06_STATE_OFFSET_N" 149 "MID_PA_E_USS_06_STATE_PROG_N" 148 "MID_PA_E_USS_06_STATE_TYPE_N" 147 "MID_CAN_ESPInvalidData_N" 146 "MID_CAN_GTWInvalidData_N" 145 "MID_CAN_SCCMInvalidData_N" 144 "MID_CAN_DASLossOfCommunication_N" 143 "MID_CAN_EPASLossOfCommunication_N" 142 "MID_CAN_EPBLossOfCommunication_N" 141 "MID_CAN_ESPLossOfCommunication_N" 140 "MID_CAN_GTWLossOfCommunication_N" 139 "MID_CAN_SCCMLossOfCommunication_N" 138 "MID_PA_E_USS_08_NO_COM_N" 137 "MID_PA_E_USS_08_OPEN_N" 136 "MID_PA_E_USS_08_RING_TOO_SHORT_N" 135 "MID_PA_E_USS_08_RINGING_TOO_LONG_N" 134 "MID_PA_E_USS_08_SHORT_2_GND_N" 133 "MID_PA_E_USS_08_SHORT_2_USENS_N" 132 "MID_PA_E_USS_08_STATE_COM_VERIFIED_N" 131 "MID_PA_E_USS_08_STATE_OFFSET_N" 130 "MID_PA_E_USS_08_STATE_PROG_N" 129 "MID_PA_E_USS_08_STATE_TYPE_N" 128 "MID_PA_E_USS_09_NO_COM_N" 127 "MID_PA_E_USS_09_OPEN_N" 126 "MID_PA_E_USS_09_RING_TOO_SHORT_N" 125 "MID_PA_E_USS_09_RINGING_TOO_LONG_N" 124 "MID_PA_E_USS_09_SHORT_2_GND_N" 123 "MID_PA_E_USS_09_SHORT_2_USENS_N" 122 "MID_PA_E_USS_09_STATE_COM_VERIFIED_N" 121 "MID_PA_E_USS_09_STATE_OFFSET_N" 120 "MID_PA_E_USS_09_STATE_PROG_N" 119 "MID_PA_E_USS_09_STATE_TYPE_N" 118 "MID_PA_E_USS_10_NO_COM_N" 117 "MID_PA_E_USS_10_OPEN_N" 116 "MID_PA_E_USS_10_RING_TOO_SHORT_N" 115 "MID_PA_E_USS_10_RINGING_TOO_LONG_N" 114 "MID_PA_E_USS_10_SHORT_2_GND_N" 113 "MID_PA_E_USS_10_SHORT_2_USENS_N" 112 "MID_PA_E_USS_10_STATE_COM_VERIFIED_N" 111 "MID_PA_E_USS_10_STATE_OFFSET_N" 110 "MID_PA_E_USS_10_STATE_PROG_N" 109 "MID_PA_E_USS_10_STATE_TYPE_N" 108 "MID_PA_E_USS_11_NO_COM_N" 107 "MID_PA_E_USS_11_OPEN_N" 106 "MID_PA_E_USS_11_RING_TOO_SHORT_N" 105 "MID_PA_E_USS_11_RINGING_TOO_LONG_N" 104 "MID_PA_E_USS_11_SHORT_2_GND_N" 103 "MID_PA_E_USS_11_SHORT_2_USENS_N" 102 "MID_PA_E_USS_11_STATE_COM_VERIFIED_N" 101 "MID_PA_E_USS_11_STATE_OFFSET_N" 100 "MID_PA_E_USS_11_STATE_PROG_N" 99 "MID_PA_E_USS_11_STATE_TYPE_N" 98 "MID_PA_E_USS_12_NO_COM_N" 97 "MID_PA_E_USS_12_OPEN_N" 96 "MID_PA_E_USS_12_RING_TOO_SHORT_N" 95 "MID_PA_E_USS_12_RINGING_TOO_LONG_N" 94 "MID_PA_E_USS_12_SHORT_2_GND_N" 93 "MID_PA_E_USS_12_SHORT_2_USENS_N" 92 "MID_PA_E_USS_12_STATE_COM_VERIFIED_N" 91 "MID_PA_E_USS_12_STATE_OFFSET_N" 90 "MID_PA_E_USS_12_STATE_PROG_N" 89 "MID_PA_E_USS_12_STATE_TYPE_N" 88 "MID_PA_E_USS_13_NO_COM_N" 87 "MID_PA_E_USS_13_OPEN_N" 86 "MID_PA_E_USS_13_RING_TOO_SHORT_N" 85 "MID_PA_E_USS_13_RINGING_TOO_LONG_N" 84 "MID_PA_E_USS_13_SHORT_2_GND_N" 83 "MID_PA_E_USS_13_SHORT_2_USENS_N" 82 "MID_PA_E_USS_13_STATE_COM_VERIFIED_N" 81 "MID_PA_E_USS_13_STATE_OFFSET_N" 80 "MID_PA_E_USS_13_STATE_PROG_N" 79 "MID_PA_E_USS_13_STATE_TYPE_N" 78 "MID_PA_E_SVA_BLOCKED_USS_ML_N" 77 "MID_PA_E_SVA_BLOCKED_USS_MR_N" 76 "MID_PA_E_WHEEL_DIR_FL_INVALID_N" 75 "MID_PA_E_WHEEL_DIR_FR_INVALID_N" 74 "MID_PA_E_WHEEL_DIR_RL_INVALID_N" 73 "MID_PA_E_WHEEL_DIR_RR_INVALID_N" 72 "MID_PA_E_WHEEL_ROTATION_FL_INVALID_N" 71 "MID_PA_E_WHEEL_ROTATION_FR_INVALID_N" 70 "MID_PA_E_WHEEL_ROTATION_RL_INVALID_N" 69 "MID_PA_E_WHEEL_ROTATION_RR_INVALID_N" 68 "MID_PA_E_WICFL_INVALID_N" 67 "MID_PA_E_WICFR_INVALID_N" 66 "MID_PA_E_WICRL_INVALID_N" 65 "MID_PA_E_WICRR_INVALID_N" 64 "MID_PA_E_YAW_RATE_INVALID_N" 63 "MID_PDUR_E_INIT_FAILED_N" 62 "MID_PDUR_E_PDU_INSTANCE_LOST_N" 61 "MID_COMM_E_NET_START_IND_CHANNEL_0_N" 60 "MID_SPI_E_DMA_TRANSFER_N" 59 "MID_SPI_E_RECEIVE_OVERFLOW_N" 58 "MID_SPI_E_TRANSFER_TIMEOUT_N" 57 "MID_PA_E_VEHDYNINTERVENTION_TIMEOUT_N" 56 "MID_TRAILER_HITCH_PRES_INVALID_N" 55 "MID_PA_E_CL15_STATE_INVALID_N" 54 "MID_PA_E_YAW_RATE_SIGN_INVALID_N" 53 "MID_PA_E_ESP_WIC_FRONT_TIMEOUT_N" 52 "MID_PA_E_SEQ_CALL_FAILURE_N" 51 "MID_PA_E_HMI_FUNCACTIVATION_TIMEOUT_N" 50 "MID_PA_E_LOWBEAM_INVALID_N" 49 "MID_PA_E_ENGINESTART_TIMEOUT_N" 48 "MID_ADC_E_VREF_N" 47 "MID_PA_E_ESP_YAW_TIMEOUT_N" 46 "MID_PA_E_TCM_PRG_TIMEOUT_N" 45 "MID_WDG_E_MODE_SWITCH_FAILED_N" 44 "MID_WDG_E_DISABLE_REJECTED_N" 43 "MID_PA_E_ESP_WHEELDIR_TIMEOUT_N" 42 "MID_PA_E_SWCPA_E_INIT_FAILURE_N" 41 "MID_PA_E_DIR_INDICATOR_INVALID_N" 40 "MID_PA_E_ESP_WIC_TIMEOUT_N" 39 "MID_PA_E_EPS_SWA_TIMEOUT_N" 38 "MID_PA_E_INSTRCLUSTER4_TIMEOUT_N" 37 "MID_PA_E_INSTRCLUSTER5_TIMEOUT_N" 36 "MID_PA_E_INSTRCLUSTER3_TIMEOUT_N" 35 "MID_PA_E_INSTRCLUSTER2_TIMEOUT_N" 34 "MID_PA_E_ASIC_WTD_RESET_N" 33 "MID_PA_E_INSTRCLUSTER1_TIMEOUT_N" 32 "MID_PA_E_ASIC_LOW_VOLT_RESET_N" 31 "MID_PA_E_POWERMODE_TIMEOUT_N" 30 "MID_PA_E_ESP_PS_TIMEOUT_N" 29 "MID_PA_E_ESP_WIC_REAR_TIMEOUT_N" 28 "MID_PA_E_TRAILER_ATTACH_INVALID_N" 27 "MID_PA_E_EXTERNAL_EPS_FAILURE_N" 26 "MID_PA_E_PSX_ACTIVATION_INVALID_N" 25 "MID_PA_E_ESP_WHEELVELO_TIMEOUT_N" 24 "MID_PA_E_ESP_LONGACC_TIMEOUT_N" 23 "MID_PA_E_VEH_DYN_INTERVENTION_INVALID_N" 22 "MID_ZPA_E_PS_MODE_INVALID_N" 21 "MID_ZPA_E_EPS_ERROR_INVALID_N" 20 "MID_ZPA_E1_ESP_PSState_INVALID_N" 19 "MID_ZPA_E2_BdaUss01BlindnessDetect_N" 18 "MID_ZPA_E2_BdaUss02BlindnessDetect_N" 17 "MID_ZPA_E2_BdaUss03BlindnessDetect_N" 16 "MID_ZPA_E2_BdaUss10BlindnessDetect_N" 15 "MID_ZPA_E2_BdaUss05BlindnessDetect_N" 14 "MID_ZPA_E2_BdaUss11BlindnessDetect_N" 13 "MID_ZPA_E2_BdaUss07BlindnessDetect_N" 12 "MID_ZPA_E2_BdaUss12BlindnessDetect_N" 11 "MID_ZPA_E2_BdaUss06BlindnessDetect_N" 10 "MID_ZPA_E2_BdaUss08BlindnessDetect_N" 9 "MID_ZPA_E2_BdaUss13BlindnessDetect_N" 8 "MID_ZPA_E2_BdaUss09BlindnessDetect_N" 7 "MID_ZPA_E2_BdaUss04BlindnessDetect_N" 6 "MID_ZPA_E2_BdaUss14BlindnessDetect_N" 5 "MID_FLS_E_READ_FAILED_N" 4 "MID_FLS_E_COMPARE_FAILED_N" 3 "MID_FLS_E_ERASE_FAILED_N" 2 "MID_FLS_E_WRITE_FAILED_N" 1 "MID_NO_FAULT_N" 0 "MID_INVALID" ;
VAL_ 622 PARK_obj_type 4 "OLO_STRAIGHT_2_CORNER" 3 "OLO_STRAIGHT_1_CORNER" 2 "OLO_STRAIGHT_O_CORNER" 1 "OLO_POINT" 0 "OLO_NO_OBJECT" ;
VAL_ 574 PARK_oocDistance 511 "SNA" 501 "NOT_INITIALIZED" 500 "NO_OBJ_COLLISION" ;
VAL_ 574 PARK_oocConfidence 127 "SNA" 0 "NO_CONFIDENCE" ;
VAL_ 574 PARK_oocDirectEchoOnly 1 "TRUE" 0 "FALSE" ;
VAL_ 574 PARK_oocVehicleX 127 "UNKNOWN" ;
VAL_ 574 PARK_oocVehicleY 127 "UNKNOWN" ;
VAL_ 574 PARK_oocCollisionSide 7 "COLLISION_SNA" 5 "COLLISION_UNKNOWN" 4 "REAR_COLLISION" 3 "FRONT_COLLISION" 2 "LEFT_SIDE_COLLISION" 1 "RIGHT_SIDE_COLLISION" 0 "NO_COLLISION" ;
VAL_ 574 PARK_oocUntrackedTime 63 "SNA" ;
VAL_ 574 PARK_oocHeight 3 "HEIGHT_UNKNOWN" 2 "HIGH_OBJ" 1 "LOW_OBJ" 0 "NO_OBJ" ;
VAL_ 574 PARK_oocOffCourse 1023 "NONE" ;
VAL_ 846 PARK_frontLeftMiddleRawDistData 255 "SNA" ;
VAL_ 846 PARK_frontMiddleRawDistData 255 "SNA" ;
VAL_ 846 PARK_frontRightMiddleRawDistData 255 "SNA" ;
VAL_ 862 PARK_rearLeftMiddleRawDistData 255 "SNA" ;
VAL_ 862 PARK_rearMiddleRawDistData 255 "SNA" ;
VAL_ 862 PARK_rearRightMiddleRawDistData 255 "SNA" ;
VAL_ 926 PARK_rightSideFrontRawDistData 255 "SNA" ;
VAL_ 926 PARK_rightSideRearRawDistData 255 "SNA" ;
VAL_ 926 PARK_leftSideFrontRawDistData 255 "SNA" ;
VAL_ 926 PARK_leftSideRearRawDistData 255 "SNA" ;
VAL_ 606 PARK_pscEnvSlotType 3 "RIGHT_CROSS" 2 "RIGHT_PARALLEL" 1 "LEFT_CROSS" 0 "LEFT_PARALLEL" ;
VAL_ 606 PARK_pscLeftParallelObj1X 2047 "SNA" 2046 "NO_SPACE" ;
VAL_ 606 PARK_pscLeftParallelObj1Y 2047 "SNA" 2046 "NO_SPACE" ;
VAL_ 606 PARK_pscLeftParallelObj1Alpha 127 "SNA" 126 "NO_SPACE" ;
VAL_ 606 PARK_pscLeftParallelObj2Y 2047 "SNA" 2046 "NO_SPACE" ;
VAL_ 606 PARK_pscLeftParallelObj2X 2047 "SNA" 2046 "NO_SPACE" ;
VAL_ 606 PARK_pscLeftParallelObj2Alpha 127 "SNA" 126 "NO_SPACE" ;
VAL_ 606 PARK_pscLeftCrossObj1X 2047 "SNA" 2046 "NO_SPACE" ;
VAL_ 606 PARK_pscLeftCrossObj1Y 2047 "SNA" 2046 "NO_SPACE" ;
VAL_ 606 PARK_pscLeftCrossObj1Alpha 127 "SNA" 126 "NO_SPACE" ;
VAL_ 606 PARK_pscLeftCrossObj2Y 2047 "SNA" 2046 "NO_SPACE" ;
VAL_ 606 PARK_pscLeftCrossObj2X 2047 "SNA" 2046 "NO_SPACE" ;
VAL_ 606 PARK_pscLeftCrossObj2Alpha 127 "SNA" 126 "NO_SPACE" ;
VAL_ 606 PARK_pscRightParallelObj1X 2047 "SNA" 2046 "NO_SPACE" ;
VAL_ 606 PARK_pscRightParallelObj1Y 2047 "SNA" 2046 "NO_SPACE" ;
VAL_ 606 PARK_pscRightParallelObj1Alpha 127 "SNA" 126 "NO_SPACE" ;
VAL_ 606 PARK_pscRightParallelObj2Y 2047 "SNA" 2046 "NO_SPACE" ;
VAL_ 606 PARK_pscRightParallelObj2X 2047 "SNA" 2046 "NO_SPACE" ;
VAL_ 606 PARK_pscRightParallelObj2Alpha 127 "SNA" 126 "NO_SPACE" ;
VAL_ 606 PARK_pscRightCrossObj1X 2047 "SNA" 2046 "NO_SPACE" ;
VAL_ 606 PARK_pscRightCrossObj1Y 2047 "SNA" 2046 "NO_SPACE" ;
VAL_ 606 PARK_pscRightCrossObj1Alpha 127 "SNA" 126 "NO_SPACE" ;
VAL_ 606 PARK_pscRightCrossObj2Y 2047 "SNA" 2046 "NO_SPACE" ;
VAL_ 606 PARK_pscRightCrossObj2X 2047 "SNA" 2046 "NO_SPACE" ;
VAL_ 606 PARK_pscRightCrossObj2Alpha 127 "SNA" 126 "NO_SPACE" ;
VAL_ 542 PARK_pscParkStatus 7 "SNA" 6 "FAULT" 5 "GUIDANCE_FINISHED" 4 "PRE_GUIDANCE" 3 "GUIDANCE_RIGHT" 2 "GUIDANCE_LEFT" 1 "SEARCHING" 0 "NOT_AVAILABLE" ;
VAL_ 542 PARK_pscParkAbortReason 31 "SNA" 25 "PSC_MOVEMENT_AT_ACTIVATION" 24 "PSC_MAX_WAY_BEHIND_HINT" 23 "PSC_PARK_STC_FAILED" 22 "PSC_PARK_PONR_NOT_REACHED" 21 "PSC_VCTL_GENERAL_ABORT" 20 "PSC_HIGH_TORQUE" 19 "PSC_ASYNC_CTRL_SYSTEM" 18 "ERROR" 17 "SYSTEM_SERVICE" 16 "SYSTEM_FAULT" 15 "ECU_INTERNAL_FAULT" 14 "DAS_ABORT" 13 "EPAS_FAULT" 12 "VEHICLE_DYNAMICS_INTERVENTION" 11 "HANDS_ON_DETECTED" 10 "FULL_WARNING_ON_BOTH_SIDES" 9 "PARK_SPACE_TOO_SMALL" 8 "OBSTACLE_ON_PATH" 7 "MAX_YAW_ANGLE_REACHED" 6 "MAX_SWA_DEV_EXCEEDED" 5 "OFF_TRACK" 4 "UNCONTROLLED_TRAVEL_DIST_REACHED" 3 "NO_VALID_PATH" 2 "MAX_NUM_OF_MOVES" 1 "VELOCITY_TOO_HIGH" 0 "NONE" ;
VAL_ 542 PARK_pscParallelSpace 3 "BOTH_AVAILABLE" 2 "LEFT_AVAILABLE" 1 "RIGHT_AVAILABLE" 0 "NONE_AVAILABLE" ;
VAL_ 542 PARK_pscCrossSpace 3 "BOTH_AVAILABLE" 2 "LEFT_AVAILABLE" 1 "RIGHT_AVAILABLE" 0 "NONE_AVAILABLE" ;
VAL_ 542 PARK_pscParallelRightParkable 3 "SNA" 2 "PARKING_SLOT_OK_POSITION_OK" 1 "PARKING_SLOT_OK" 0 "NONE" ;
VAL_ 542 PARK_pscParallelLeftParkable 3 "SNA" 2 "PARKING_SLOT_OK_POSITION_OK" 1 "PARKING_SLOT_OK" 0 "NONE" ;
VAL_ 542 PARK_pscCrossRightParkable 3 "SNA" 2 "PARKING_SLOT_OK_POSITION_OK" 1 "PARKING_SLOT_OK" 0 "NONE" ;
VAL_ 542 PARK_pscMaxVelocity 63 "SNA" ;
VAL_ 542 PARK_pscCrossLeftParkable 3 "SNA" 2 "PARKING_SLOT_OK_POSITION_OK" 1 "PARKING_SLOT_OK" 0 "NONE" ;
VAL_ 542 PARK_pscParkInstruction 7 "SNA" 5 "EXPLORATION" 4 "ABORTED" 3 "DRIVE_BACKWARD" 2 "DRIVE_FORWARD" 1 "STOP" 0 "NO_MESSAGE" ;
VAL_ 542 PARK_pscManeuverDistance 2047 "SNA" ;
VAL_ 542 PARK_pscAngleActive 1 "REQUEST_CONTROL" 0 "INACTIVE" ;
VAL_ 590 PARK_pscVehSlotType 3 "RIGHT_CROSS" 2 "RIGHT_PARALLEL" 1 "LEFT_CROSS" 0 "LEFT_PARALLEL" ;
VAL_ 590 PARK_pscLeftParallelVehX 2047 "SNA" 2046 "NO_SPACE" ;
VAL_ 590 PARK_pscLeftParallelVehY 2047 "SNA" 2046 "NO_SPACE" ;
VAL_ 590 PARK_pscLeftParallelPsi 8191 "SNA" 8190 "NO_SPACE" ;
VAL_ 590 PARK_pscLeftParallelSizeX 255 "SNA" 254 "NO_SPACE" ;
VAL_ 590 PARK_pscLeftParallelSizeY 255 "SNA" 254 "NO_SPACE" ;
VAL_ 590 PARK_pscLeftCrossVehX 2047 "SNA" 2046 "NO_SPACE" ;
VAL_ 590 PARK_pscLeftCrossVehY 2047 "SNA" 2046 "NO_SPACE" ;
VAL_ 590 PARK_pscLeftCrossPsi 8191 "SNA" 8190 "NO_SPACE" ;
VAL_ 590 PARK_pscLeftCrossSizeX 255 "SNA" 254 "NO_SPACE" ;
VAL_ 590 PARK_pscLeftCrossSizeY 255 "SNA" 254 "NO_SPACE" ;
VAL_ 590 PARK_pscRightParallelVehX 2047 "SNA" 2046 "NO_SPACE" ;
VAL_ 590 PARK_pscRightParallelVehY 2047 "SNA" 2046 "NO_SPACE" ;
VAL_ 590 PARK_pscRightParallelPsi 8191 "SNA" 8190 "NO_SPACE" ;
VAL_ 590 PARK_pscRightParallelSizeX 255 "SNA" 254 "NO_SPACE" ;
VAL_ 590 PARK_pscRightParallelSizeY 255 "SNA" 254 "NO_SPACE" ;
VAL_ 590 PARK_pscRightCrossVehX 2047 "SNA" 2046 "NO_SPACE" ;
VAL_ 590 PARK_pscRightCrossVehY 2047 "SNA" 2046 "NO_SPACE" ;
VAL_ 590 PARK_pscRightCrossPsi 8191 "SNA" 8190 "NO_SPACE" ;
VAL_ 590 PARK_pscRightCrossSizeX 255 "SNA" 254 "NO_SPACE" ;
VAL_ 590 PARK_pscRightCrossSizeY 255 "SNA" 254 "NO_SPACE" ;
VAL_ 526 PARK_sdiSensor1RawDistData 511 "SNA" 500 "NO_OBJECT_DETECTED" 1 "NEAR_DETECTION" 0 "BLOCKED" ;
VAL_ 526 PARK_sdiSensor2RawDistData 511 "SNA" 500 "NO_OBJECT_DETECTED" 1 "NEAR_DETECTION" 0 "BLOCKED" ;
VAL_ 526 PARK_sdiSensor3RawDistData 511 "SNA" 500 "NO_OBJECT_DETECTED" 1 "NEAR_DETECTION" 0 "BLOCKED" ;
VAL_ 526 PARK_sdiSensor4RawDistData 511 "SNA" 500 "NO_OBJECT_DETECTED" 1 "NEAR_DETECTION" 0 "BLOCKED" ;
VAL_ 526 PARK_sdiSensor5RawDistData 511 "SNA" 500 "NO_OBJECT_DETECTED" 1 "NEAR_DETECTION" 0 "BLOCKED" ;
VAL_ 526 PARK_sdiSensor6RawDistData 511 "SNA" 500 "NO_OBJECT_DETECTED" 1 "NEAR_DETECTION" 0 "BLOCKED" ;
VAL_ 558 PARK_sdiSensor7RawDistData 511 "SNA" 500 "NO_OBJECT_DETECTED" 1 "NEAR_DETECTION" 0 "BLOCKED" ;
VAL_ 558 PARK_sdiSensor8RawDistData 511 "SNA" 500 "NO_OBJECT_DETECTED" 1 "NEAR_DETECTION" 0 "BLOCKED" ;
VAL_ 558 PARK_sdiSensor9RawDistData 511 "SNA" 500 "NO_OBJECT_DETECTED" 1 "NEAR_DETECTION" 0 "BLOCKED" ;
VAL_ 558 PARK_sdiSensor10RawDistData 511 "SNA" 500 "NO_OBJECT_DETECTED" 1 "NEAR_DETECTION" 0 "BLOCKED" ;
VAL_ 558 PARK_sdiSensor11RawDistData 511 "SNA" 500 "NO_OBJECT_DETECTED" 1 "NEAR_DETECTION" 0 "BLOCKED" ;
VAL_ 558 PARK_sdiSensor12RawDistData 511 "SNA" 500 "NO_OBJECT_DETECTED" 1 "NEAR_DETECTION" 0 "BLOCKED" ;
VAL_ 814 PARK_frontRightSensorState 3 "SNA" 2 "TEMPORARY_FAILURE" 1 "PERMANENT_FAILURE" 0 "NO_FAILURE" ;
VAL_ 814 PARK_frontRightMiddleSensorState 3 "SNA" 2 "TEMPORARY_FAILURE" 1 "PERMANENT_FAILURE" 0 "NO_FAILURE" ;
VAL_ 814 PARK_frontLeftMiddleSensorState 3 "SNA" 2 "TEMPORARY_FAILURE" 1 "PERMANENT_FAILURE" 0 "NO_FAILURE" ;
VAL_ 814 PARK_frontLeftSensorState 3 "SNA" 2 "TEMPORARY_FAILURE" 1 "PERMANENT_FAILURE" 0 "NO_FAILURE" ;
VAL_ 814 PARK_frontLeftRawDistData 255 "SNA" ;
VAL_ 814 PARK_frontRightRawDistData 255 "SNA" ;
VAL_ 814 PARK_systemStatusFront 3 "SNA" 2 "UNUSED" 1 "ENABLED" 0 "DISABLED" ;
VAL_ 814 PARK_frontDtcPresent 3 "SNA" 2 "UNUSED" 1 "TRUE" 0 "FALSE" ;
VAL_ 830 PARK_rearRightSensorState 3 "SNA" 2 "TEMPORARY_FAILURE" 1 "PERMANENT_FAILURE" 0 "NO_FAILURE" ;
VAL_ 830 PARK_rearRightMiddleSensorState 3 "SNA" 2 "TEMPORARY_FAILURE" 1 "PERMANENT_FAILURE" 0 "NO_FAILURE" ;
VAL_ 830 PARK_rearLeftMiddleSensorState 3 "SNA" 2 "TEMPORARY_FAILURE" 1 "PERMANENT_FAILURE" 0 "NO_FAILURE" ;
VAL_ 830 PARK_rearLeftSensorState 3 "SNA" 2 "TEMPORARY_FAILURE" 1 "PERMANENT_FAILURE" 0 "NO_FAILURE" ;
VAL_ 830 PARK_rearLeftRawDistData 255 "SNA" ;
VAL_ 830 PARK_rearRightRawDistData 255 "SNA" ;
VAL_ 830 PARK_systemStatusRear 3 "SNA" 2 "UNUSED" 1 "ENABLED" 0 "DISABLED" ;
VAL_ 830 PARK_rearDtcPresent 3 "SNA" 2 "UNUSED" 1 "TRUE" 0 "FALSE" ;
VAL_ 798 PARK_status 3 "SNA" 2 "TEMPORARY_FAILURE" 1 "ENABLED" 0 "DISABLED" ;
VAL_ 798 PARK_serviceRequest 3 "SNA" 2 "UNUSED" 1 "FAILURE" 0 "NO_FAILURE" ;
VAL_ 798 PARK_systemDtcPresent 3 "SNA" 2 "UNUSED" 1 "TRUE" 0 "FALSE" ;
VAL_ 798 PARK_majorVersion 255 "SNA" ;
VAL_ 798 PARK_minorVersion 255 "SNA" ;
VAL_ 798 PARK_subMinorVersion 255 "SNA" ;
VAL_ 782 PARK_pscRightCurbType 2 "HIGH_CURB" 1 "LOW_CURB" 0 "VIRTUAL_CURB" ;
VAL_ 782 PARK_pscLeftCurbType 2 "HIGH_CURB" 1 "LOW_CURB" 0 "VIRTUAL_CURB" ;
VAL_ 782 PARK_autoCalComplete 1 "COMPLETE" 0 "INCOMPLETE" ;
VAL_ 782 PARK_geometryType 2 "MODELX" 1 "MODELS_2" 0 "MODELS" ;
VAL_ 782 PARK_tireFitment 3 "SNA" 1 "STAGGERED" 0 "SQUARE" ;
VAL_ 782 PARK_rackDetected 3 "SNA" 2 "RACK_DETECTED" 1 "NO_RACK" 0 "UNKNOWN" ;
VAL_ 782 PARK_sdiActive 1 "SDI_ENABLED" 0 "SDI_DISABLED" ;
VAL_ 782 PARK_sdiNoise 3 "SDI_NOISE_SNA" 2 "SDI_NOISE_RAIN" 1 "SDI_NOISE_HIGH" 0 "SDI_NOISE_NOMINAL" ;
VAL_ 782 PARK_sdiBlindSpotRight 3 "SNA" 2 "UNUSED" 1 "WARNING" 0 "NO_WARNING" ;
VAL_ 782 PARK_sdiBlindSpotLeft 3 "SNA" 2 "UNUSED" 1 "WARNING" 0 "NO_WARNING" ;
VAL_ 584 PM_ebrCmdState 8 "EBR_CMD_INVALID" 6 "EBR_CMD_VALID" 0 "EBR_CMD_SNA" ;
VAL_ 584 PM_aebState 7 "AEB_CAN_STATE_SNA" 4 "AEB_CAN_STATE_FAULT" 3 "AEB_CAN_STATE_STANDSTILL" 2 "AEB_CAN_STATE_ENABLED" 1 "AEB_CAN_STATE_STANDBY" 0 "AEB_CAN_STATE_UNAVAILABLE" ;
VAL_ 584 PM_vdcCmdState 8 "VDC_CMD_INVALID" 6 "VDC_CMD_VALID" 0 "VDC_CMD_SNA" ;
VAL_ 584 PM_vehicleHoldState 7 "DI_VHLD_STATE_INIT" 6 "DI_VHLD_STATE_FAULT" 5 "DI_VHLD_STATE_PARK" 4 "DI_VHLD_STATE_BLEND_OUT" 3 "DI_VHLD_STATE_STANDSTILL" 2 "DI_VHLD_STATE_BLEND_IN" 1 "DI_VHLD_STATE_STANDBY" 0 "DI_VHLD_STATE_UNAVAILABLE" ;
VAL_ 517 PN14_SupBat_Volt 255 "SNA" ;
VAL_ 517 PN14_SupBatCutSw_Stat 3 "SNA" 2 "OPN" 1 "PREOPN" 0 "CLS" ;
VAL_ 517 PN14_AS_Off_Rq 3 "SNA" 2 "AS_CANCEL" 1 "AS_FORBID" 0 "IDLE" ;
VAL_ 517 SPCR_Flt_PN14 3 "SNA" 2 "NDEF2" 1 "FLT" 0 "OK" ;
VAL_ 517 PN14_TransMd_Stat 3 "SNA" 2 "ACTV" 1 "TEMP_OFF" 0 "OFF" ;
VAL_ 1365 RADC_alertID 55 "RADC_w055_blockageInfo_Frame_2" 54 "RADC_w054_blockageInfo_Frame_1" 53 "RADC_w053_emError" 52 "RADC_w052_mismatcRadPos" 51 "RADC_w051_mismatchEPASType" 50 "RADC_w050_mismatchCountry" 49 "RADC_w049_mismatchFourWheelDrive" 48 "RADC_w048_mismatchAirSuspension" 47 "RADC_w047_mismatchChassisType" 46 "RADC_w046_wheelSpeedsErr" 45 "RADC_w045_vehicleStateErr" 44 "RADC_w044_steeringWheelAngleErr" 43 "RADC_w043_inertialSignalsErr" 42 "RADC_w042_carConfigErr" 41 "RADC_w041_vinErr" 40 "RADC_w040_wheelSpeedsMIA" 39 "RADC_w039_vehicleStateMIA" 38 "RADC_w038_steeringWheelAngleMIA" 37 "RADC_w037_inertialSignalsMIA" 36 "RADC_w036_carConfigMIA" 35 "RADC_w035_vinMIA" 34 "RADC_w034_vehDynamicsError" 33 "RADC_w033_sensorNeverAligned" 32 "RADC_w032_sensorBlocked" 31 "RADC_w031_sensorMisaligned" 30 "RADC_w030_rspError" 29 "RADC_w029_rhcError" 28 "RADC_w028_rfChipError" 27 "RADC_w027_nvmFailure" 26 "RADC_w026_underVoltage" 25 "RADC_w025_overVoltage" 24 "RADC_w024_underTempCrit" 23 "RADC_w023_underTemp" 22 "RADC_w022_tempImplausible" 21 "RADC_w021_overTempCrit" 20 "RADC_w020_overTemp" 19 "RADC_w019_internalSoftwareFault" 18 "RADC_w018_internalHardwareFault" 17 "RADC_w017_adcUnderVolt" 16 "RADC_w016_adcOverVolt" 15 "RADC_w015_fctSenInterference" 14 "RADC_w014_fctSelfTestNotDone" 13 "RADC_w013_ecuWdgError" 12 "RADC_w012_ecuSpiError" 11 "RADC_w011_ecuMcemError" 10 "RADC_w010_ecuIoHwAbError" 9 "RADC_w009_plantModeActive" 8 "RADC_w008_ecuHwSwInterlock" 7 "RADC_w007_ecuGptCheckError" 6 "RADC_w006_ecuFimError" 5 "RADC_w005_ecuEcuMError" 4 "RADC_w004_ecuCrcHwError" 3 "RADC_w003_ecuBistDisabled" 2 "RADC_w002_ecuAdcError" 1 "RADC_w001_can1BusOff" ;
VAL_ 1365 RADC_a002_ecuAdcErrType 1 "ADC_E_INVALID_CONV_MODE" 0 "ADC_E_LIMIT_RANGE" ;
VAL_ 1365 RADC_a008_interLockErrType 1 "SW_VERSION_MISMATCH" 0 "HW_SW_PROJECT_ID_INCOMPATIBLE" ;
VAL_ 1365 RADC_a011_ecuMcemErrType 10 "MCEM__ALARM_ISR" 9 "MCEM_E_CORRUPTED_HW_CONFIG" 8 "MCEM_E_FAULT" 7 "MCEM_E_FORBIDDEN_INVOCATION" 6 "MCEM_E_INIT_FAILED" 5 "MCEM_E_OPERATION_FAILED" 4 "MCU_E_CLOCK_FAILURE" 3 "MCU_E_MCME_PERIODIC_CHECK" 2 "MCU_E_MCPCU_PERIODIC_CHECK" 1 "MCU_E_MCRGM_PERIODIC_CHECK" 0 "MCU_E_QUARTZ_FAILURE" ;
VAL_ 1365 RADC_a013_ecuWdgErrType 3 "WATCHDOG_CORRUPT_CONFIG" 2 "WATCHDOG_DISABLE_REJECTED" 1 "WATCHDOG_INVALID_CALL" 0 "WATCHDOG_UNLOCKED" ;
VAL_ 1365 RADC_a016_adcOverVoltType 7 "ADC_5V_SMPS_OVER_VOLTAGE" 6 "ADC_4V5_LIN_VOLTAGECO_OVER_VOLTAGE" 5 "ADC_3V8_SMPS_OVER_VOLTAGE" 4 "ADC_3V3_LIN_ANALOG_OVER_VOLTAGE" 3 "ADC_3V3_LIN_DIGITAL_OVER_VOLTAGE" 2 "ADC_3V3_LIN_PA_OVER_VOLTAGE" 1 "ADC_3V3_LIN_VOLTAGECO_OVER_VOLTAGE" 0 "ADC_1V25_SMPS_OVER_VOLTAGE" ;
VAL_ 1365 RADC_a017_adcUnderVoltType 7 "ADC_5V_SMPS_UNDER_VOLTAGE" 6 "ADC_4V5_LIN_VOLTAGECO_UNDER_VOLTAGE" 5 "ADC_3V8_SMPS_UNDER_VOLTAGE" 4 "ADC_3V3_LIN_ANALOG_UNDER_VOLTAGE" 3 "ADC_3V3_LIN_DIGITAL_UNDER_VOLTAGE" 2 "ADC_3V3_LIN_PA_UNDER_VOLTAGE" 1 "ADC_3V3_LIN_VOLTAGECO_UNDER_VOLTAGE" 0 "ADC_1V25_SMPS_UNDER_VOLTAGE" ;
VAL_ 1365 RADC_a019_internalSWFaultType 110 "FS_RESET_ADC_CALIBRATION" 109 "FS_RESET_PROCESSOR_VERSION" 108 "FS_RESET_FLASH_CYCLIC_CHECK" 107 "FS_RESET_INTERNAL_VOLTAGE_FAILED" 106 "FS_RESET_ATIC_RESET" 105 "FS_RESET_LBIST_FAILED" 104 "FS_RESET_MBIST_FAILED" 103 "FS_RESET_STARTUP_ERROR" 102 "FS_RESET_TEMP_CROSS_CHECK" 101 "FS_RESET_ECC_INIT_FAILED" 100 "FS_RESET_RADAR_CYCLE_VIOLATION" 99 "FS_RESET_FLSP_INIT_FAILED" 98 "FS_RESET_POWERUP_SEQ_TIMEOUT" 97 "FS_RESET_IOHWAB_TIMEOUT" 96 "FS_RESET_UBATT_OUT_OF_RANGE" 95 "FS_RESET_EXCEPT_RESERVED_15" 94 "FS_RESET_EXCEPT_RESERVED_14" 93 "FS_RESET_EXCEPT_RESERVED_13" 92 "FS_RESET_EXCEPT_TRAP" 91 "FS_RESET_EXCEPT_CENTRAL" 90 "FS_RESET_FCCU_HEALED_FAULT" 89 "FS_RESET_FCCU_CHECKER_MISMATCH" 88 "FS_RESET_PLL_STUCK" 87 "FS_RESET_ECUM_REQUEST" 86 "FS_RESET_SPI_ATIC_FAULT" 85 "FS_RESET_SPI_MMIC_MISMATCH" 84 "FS_RESET_SPI_MMIC_FAULT" 83 "FS_RESET_ECC_OTHER_2BIT" 82 "FS_RESET_ECC_CORE_ICACHE_2BIT" 81 "FS_RESET_ECC_CORE_DCACHE_2BIT" 80 "FS_RESET_ECC_CORE_IMEM_2BIT" 79 "FS_RESET_ECC_CORE_DMEM_2BIT" 78 "FS_RESET_ECC_EEPROM_2BIT" 77 "FS_RESET_ECC_FLASH_2BIT" 76 "FS_RESET_ECC_SRAM_2BIT" 75 "FS_RESET_SMPU" 74 "FS_RESET_IOHWAB" 73 "FS_RESET_ECC_PATTERN_MISSING" 72 "FS_RESET_WATCHDOG" 71 "FS_RESET_WATCHDOG_INITIALIZATION" 70 "FS_RESET_CLKMON_CALIBRATION" 69 "FS_RESET_CLKMON_CONFIG_CHECK" 68 "FS_RESET_CLKMON_INITIALIZATION" 67 "FS_RESET_FCCU_FAULT_SIGNALED" 66 "FS_RESET_FCCU_CORRUPTED_CONFIG" 65 "FS_RESET_HW_SW_INCOMPATIBLE" 64 "FS_RESET_SPE_CHECK" 63 "FS_RESET_FPU_CHECK" 62 "FS_RESET_ECC_SPT_2BIT" 61 "FS_RESET_ECC_DMA_2BIT" 60 "FS_RESET_ECC_HARDWARE_FAILURE" 59 "FS_RESET_DRIVERINIT_FAILED" 58 "FS_RESET_CORE2_STACK_OVERFLOW" 57 "FS_RESET_CORE1_STACK_OVERFLOW" 56 "FS_RESET_NVM_TIMEOUT" 55 "FS_RESET_EXCEPT_ECC2BITERROR" 54 "FS_RESET_EXCEPT_ECC1BITERROR" 53 "FS_RESET_EXCEPT_DECREMENTER" 52 "FS_RESET_EXCEPT_AP_UNAVAILABLE" 51 "FS_RESET_EXCEPT_SYSTEM_CALL" 50 "FS_RESET_E_FLOATINGPOINT_UNAVAIL" 49 "FS_RESET_FCCU" 48 "FS_RESET_INTENTIONAL_RESET" 47 "FS_RESET_CYCLE_MON" 46 "FS_RESET_TESTCASE_CONFIG" 45 "FS_RESET_TESTCASE_ABORT" 44 "FS_RESET_EXCEPT_CORE_FREEZE" 43 "FS_RESET_INVALID_SAFESECTION" 42 "FS_RESET_BUS_TEST" 41 "FS_RESET_UNEXPECTED_RESET" 40 "FS_RESET_ALU_CHECK" 39 "FS_RESET_MISC_CHECK" 38 "FS_RESET_APPL_CRC_CHECK" 37 "FS_RESET_CONFIG_REGISTER_CHECK" 36 "FS_RESET_CPU_REGISTER_CHECK" 35 "FS_RESET_TPU_RAM_ADDRESS_BUS1" 34 "FS_RESET_TPU_RAM_ADDRESS_BUS0" 33 "FS_RESET_SRAM_ADDRESS_BUS1" 32 "FS_RESET_SRAM_ADDRESS_BUS0" 31 "FS_RESET_ECC_TIMEOUT" 30 "FS_RESET_DCACHE_MARCHC" 29 "FS_RESET_AD_CONVERTER" 28 "FS_RESET_TASK_STACK" 27 "FS_RESET_TASK_MON_LOGIC" 26 "FS_RESET_SYSTEM_CYCLE_MON" 25 "FS_RESET_EXCEPT_UNDEFINED" 24 "FS_RESET_EXCEPT_ERROR_TPU_RAM" 23 "FS_RESET_EXCEPT_ERROR_SRAM" 22 "FS_RESET_EXCEPT_SHUTDOWN_OS" 21 "FS_RESET_EXCEPT_EFP_ROUND" 20 "FS_RESET_EXCEPT_EFP_DATA" 19 "FS_RESET_EXCEPT_SPE_UNAVAIL" 18 "FS_RESET_EXCEPT_INSTR_TLB_ERROR" 17 "FS_RESET_EXCEPT_DATA_TLB_ERROR" 16 "FS_RESET_EXCEPT_WATCHDOG_TIMER" 15 "FS_RESET_EXCEPT_FIXED_INTER" 14 "FS_RESET_EXCEPT_DEBUG" 13 "FS_RESET_EXCEPT_PERFORMANCEMON" 12 "FS_RESET_EXCEPT_PROGRAM" 11 "FS_RESET_EXCEPT_ALIGN" 10 "FS_RESET_EXCEPT_INSTRUCT_STORE" 9 "FS_RESET_EXCEPT_DATA_STORE" 8 "FS_RESET_EXCEPT_MACH_CHECK" 7 "FS_RESET_EXCEPT_CRIT_INPUT" 6 "FS_RESET_ROM_ECC_2BIT" 5 "FS_RESET_RAM_ECC_2BIT" 4 "FS_RESET_ROM_ECC_1BIT" 3 "FS_RESET_RAM_ECC_1BIT" 2 "FS_RESET_MCU_SUPPLY" 1 "FS_RESET_TEMP_MON" 0 "FS_RESET_NONE" ;
VAL_ 1365 RADC_a019_internalSWFaultCoreID 2 "INTERNAL_SOFTWARE_FAULT_CORE_2" 1 "INTERNAL_SOFTWARE_FAULT_CORE_1" 0 "INTERNAL_SOFTWARE_FAULT_CORE_0" ;
VAL_ 1365 RADC_a027_nvmFailureType 2 "NVM_INTEGRITY_FAILED" 1 "NVM_REQ_FAILED" 0 "NVM_RECORD_SIZE_MISSMATCH" ;
VAL_ 1365 RADC_a028_rfComRegCheckFail 4 "RFCOM_MON_RF_OVERTEMP" 3 "RFCOM_MON_RF_CHIP_TEMP_IMPLAUSIBLE" 2 "RFCOM_REG_CHECK_FAILED_LT" 1 "RFCOM_REG_CHECK_FAILED" 0 "RFCOM_REG_CHECK_CYCLE_FAILED" ;
VAL_ 1365 RADC_a029_rhcChirpMonErrType 2 "RHC_CHIRP_MON_RG_LENGTH_ERROR_NS" 1 "RHC_CHIRP_MON_RMSE_TOO_LARGE_NS" 0 "RHC_CHIRP_MON_FREQ_ERROR_SPEC_TOO_LARGE_NS" ;
VAL_ 1365 RADC_a029_rhcRxLongTermErrType 6 "RHC_RX_NOISE_POWER_TOO_HIGH_LT" 5 "RHC_RX_SPURIOUS_PEAKS_TOO_HIGH_LT" 4 "RHC_RX_SIGNAL_POWER_TOO_LOW_LT" 3 "RHC_RX_TRANSFER_FUNCTION_ERR_LT" 2 "RHC_RX_CHANNEL_VARIATION_ERR_LT" 1 "RHC_RX_STC_FILTER_ERR_LT" 0 "RHC_RX_NONLINEAR_ERR_LT" ;
VAL_ 1365 RADC_a029_rhcRxErrType 7 "RHC_RX_SPURIOUS_PEAKS_TOO_HIGH" 6 "RHC_LOAD_PULLING_TOO_HIGH_NS" 5 "RHC_RX_NOISE_POWER_TOO_HIGH" 4 "RHC_RX_SIGNAL_POWER_TOO_LOW" 3 "RHC_RX_TRANSFER_FUNCTION_ERR" 2 "RHC_RX_CHANNEL_VARIATION_ERR" 1 "RHC_RX_STC_FILTER_ERR" 0 "RHC_RX_NONLINEAR_ERR" ;
VAL_ 1365 RADC_a029_rhcVcoPowerErrType 1 "RHC_VCO_POWER_TOO_LOW" 0 "RHC_VCO_POWER_TOO_HIGH" ;
VAL_ 1365 RADC_a029_rhcSp1ErrType 0 "RHC_CTE_LUT_DUR_STUCK_ERR" ;
VAL_ 1365 RADC_a029_rhcFdcErrType 2 "RHC_FDC_LONG_TERM_ERROR_NS" 1 "RHC_FDC_RMSE_TOO_LARGE_NS" 0 "RHC_FDC_DRIFT_FREQ_TOO_LARGE_NS" ;
VAL_ 1365 RADC_a030_rspErrType 1 "RSP_SPT_LONG_TERM_ERROR" 0 "RSP_SPT_SHORT_TERM_ERROR" ;
VAL_ 1365 RADC_a032_blockageType 4 "FCTSEN_OBJ_NOT_MEASURED" 3 "FCTSEN_BLOCKAGE" 2 "FCTSEN_DEC_BLOCKAGE" 1 "FCTSEN_INC_BLOCKAGE" 0 "ALN_PATH_COMP_HIGH_NEAR" ;
VAL_ 1365 RADC_a032_block_SPMBlockageState 4 "GDB_UNKNOWN_DAMP" 3 "GDB_RDC_DAMP" 2 "GDB_FULL_DAMP" 1 "GDB_INC_DAMP" 0 "DB_NO_DAMP" ;
VAL_ 1365 RADC_a032_block_SPMSelfTestState 3 "GDB_PD_ROADBEAM_TEST" 2 "GDB_PD_STARTUP" 1 "GDB_PD_ON" 0 "GDB_PD_OFF" ;
VAL_ 1365 RADC_a034_vehDynamicsErrType 7 "VDY_INPUT_SIG_ERROR" 6 "VDY_INPUT_SIG_PEAK_ERROR" 5 "VDY_LEARND_SWA_OFFSET_OUT_OF_RANGE" 4 "VDY_INPUT_PARAM_ERROR" 3 "VDY_FS_VEH_CORR_MON" 2 "VDY_EXT_VELO_IMPLAUSIBLE" 1 "OUTPUT_YAW_SNA" 0 "OUTPUT_VELOCITY_SNA" ;
VAL_ 1365 RADC_a041_vinErrType 5 "OVERRUN" 4 "INVALID_DATA" 3 "SEQUENCE" 2 "CHECKSUM" 1 "LENGTH" 0 "NONE" ;
VAL_ 1365 RADC_a042_carConfigErrType 5 "OVERRUN" 4 "INVALID_DATA" 3 "SEQUENCE" 2 "CHECKSUM" 1 "LENGTH" 0 "NONE" ;
VAL_ 1365 RADC_a043_inertialSignalsErrType 5 "OVERRUN" 4 "INVALID_DATA" 3 "SEQUENCE" 2 "CHECKSUM" 1 "LENGTH" 0 "NONE" ;
VAL_ 1365 RADC_a044_stwAngleErrType 5 "OVERRUN" 4 "INVALID_DATA" 3 "SEQUENCE" 2 "CHECKSUM" 1 "LENGTH" 0 "NONE" ;
VAL_ 1365 RADC_a045_vehicleStateErrType 5 "OVERRUN" 4 "INVALID_DATA" 3 "SEQUENCE" 2 "CHECKSUM" 1 "LENGTH" 0 "NONE" ;
VAL_ 1365 RADC_a046_wheelSpeedsErrType 5 "OVERRUN" 4 "INVALID_DATA" 3 "SEQUENCE" 2 "CHECKSUM" 1 "LENGTH" 0 "NONE" ;
VAL_ 1365 RADC_a047_chassisTypeExp 7 "SNA" 2 "MODEL_3_CHASSIS" 1 "MODEL_X_CHASSIS" 0 "MODEL_S_CHASSIS" ;
VAL_ 1365 RADC_a047_chassisTypeRx 7 "SNA" 2 "MODEL_3_CHASSIS" 1 "MODEL_X_CHASSIS" 0 "MODEL_S_CHASSIS" ;
VAL_ 1365 RADC_a048_airSuspensionExp 7 "SNA" 4 "TESLA_PLUS" 3 "TESLA_STANDARD" 2 "PLUS" 1 "STANDARD" 0 "NONE" ;
VAL_ 1365 RADC_a048_airSuspensionRx 7 "SNA" 4 "TESLA_PLUS" 3 "TESLA_STANDARD" 2 "PLUS" 1 "STANDARD" 0 "NONE" ;
VAL_ 1365 RADC_a049_fourWheelDriveExp 3 "SNA" 2 "UNUSED" 1 "4WD" 0 "2WD" ;
VAL_ 1365 RADC_a049_fourWheelDriveRx 3 "SNA" 2 "UNUSED" 1 "4WD" 0 "2WD" ;
VAL_ 1365 RADC_a050_countryExp 8191 "SNA" ;
VAL_ 1365 RADC_a050_countryRx 8191 "SNA" ;
VAL_ 1365 RADC_a051_epasTypeExp 7 "SNA" 4 "MANDO_VGR63_GEN3" 3 "MANDO_VGR66" 2 "MANDO_FGR64" 1 "BOSCH_L405" 0 "BOSCH_L538" ;
VAL_ 1365 RADC_a051_epasTypeRx 7 "SNA" 4 "MANDO_VGR63_GEN3" 3 "MANDO_VGR66" 2 "MANDO_FGR64" 1 "BOSCH_L405" 0 "BOSCH_L538" ;
VAL_ 1365 RADC_a052_radarPositionExp 7 "SNA" 3 "MODEL_3" 2 "MODELX" 1 "MODELS_2" 0 "MODELS" ;
VAL_ 1365 RADC_a052_radarPositionRx 7 "SNA" 3 "MODEL_3" 2 "MODELX" 1 "MODELS_2" 0 "MODELS" ;
VAL_ 1329 RADC_infoIndex 255 "INFO_END" 20 "INFO_UDS_PROTOCOL_BOOTCRC" 19 "INFO_VERSION_DEPRECATED" 18 "INFO_BOOTLOADER_GITHASH" 17 "INFO_APP_GITHASH" 16 "INFO_SUBCOMPONENT" 15 "INFO_BOOTLOADER_CRC" 14 "INFO_BOOTLOADER_SVN" 13 "INFO_APP_CRC" 11 "INFO_PCBAID_ASSYID_USAGEID" 10 "INFO_BUILD_HWID_COMPONENTID" 9 "INFO_DEPRECATED_9" 8 "INFO_DEPRECATED_8" 7 "INFO_DEPRECATED_7" 6 "INFO_DEPRECATED_6" 5 "INFO_DEPRECATED_5" 4 "INFO_DEPRECATED_4" 3 "INFO_DEPRECATED_3" 2 "INFO_DEPRECATED_2" 1 "INFO_DEPRECATED_1" 0 "INFO_DEPRECATED_0" ;
SIG_GROUP_ 517 PN14_LHC_Stat 1 : LHC_ComfLmp_Rq LHC_CoolBox_R_Rq LHC_DSH_Stg1_Rq LHC_DSH_Stg2_Rq LHC_EBL_Rq LHC_EngFan_50_Rq LHC_FogLmp_Ft_Rq LHC_ICH_Rq LHC_IntFan_F_50_Rq LHC_IntFan_R_50_Rq LHC_MirrHt_Rq LHC_PTC1_Rq LHC_PTC2_Rq LHC_PTC3_Rq LHC_PTC4_Rq LHC_PTC5_Rq LHC_PTC6_Rq LHC_PkLmp_Rq LHC_PosnLmp_Rq LHC_RHU_Rq LHC_SeatHtStg1_Rq LHC_SeatHtStg2_Rq LHC_SeatHtStg3_Rq LHC_SeatVn_Rq LHC_StW_Ht_Rq LHC_Tlm_Rq LHC_TrkSock_Rq LHC_TrlrSock_Rq LHC_WShHt_Rq LHC_WprPkHt_Rq PN14_LHC_Actv PN14_LHC_Taxi_Rq PN14_TransMd_Stat;
SIG_GROUP_ 517 PN14_SupBat_Stat 1 : PN14_GM1_Actv PN14_GM1_Avl PN14_SupBatCutSw_Stat PN14_SupBat_Volt;
SIG_GROUP_ 517 SPCR_Stat_PN14 1 : PN14_AS_Off_Rq SPCR_Flt_PN14;
